VERSION ""

NS_ :

BS_:

BU_: XXX

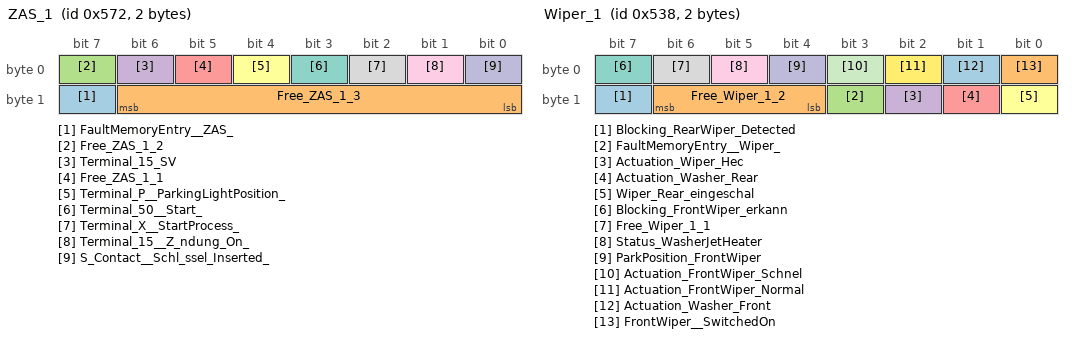
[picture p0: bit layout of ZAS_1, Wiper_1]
BO_ 1394 ZAS_1: 2 XXX
 SG_ FaultMemoryEntry__ZAS_ : 15|1@1+ (1,0) [0|0] "" XXX
 SG_ Free_ZAS_1_3 : 8|7@1+ (1,0) [0|0] "" XXX
 SG_ Free_ZAS_1_2 : 7|1@1+ (1,0) [0|0] "" XXX
 SG_ Terminal_15_SV : 6|1@1+ (1,0) [0|0] "" XXX
 SG_ Free_ZAS_1_1 : 5|1@1+ (1,0) [0|0] "" XXX
 SG_ Terminal_P__ParkingLightPosition_ : 4|1@1+ (1,0) [0|0] "" XXX
 SG_ Terminal_50__Start_ : 3|1@1+ (1,0) [0|0] "" XXX
 SG_ Terminal_X__StartProcess_ : 2|1@1+ (1,0) [0|0] "" XXX
 SG_ Terminal_15__Z_ndung_On_ : 1|1@1+ (1,0) [0|0] "" XXX
 SG_ S_Contact__Schl_ssel_Inserted_ : 0|1@1+ (1,0) [0|0] "" XXX

BO_ 1336 Wiper_1: 2 XXX
 SG_ Blocking_RearWiper_Detected : 15|1@1+ (1,0) [0|0] "" XXX
 SG_ Free_Wiper_1_2 : 12|3@1+ (1,0) [0|0] "" XXX
 SG_ FaultMemoryEntry__Wiper_ : 11|1@1+ (1,0) [0|0] "" XXX
 SG_ Actuation_Wiper_Hec : 10|1@1+ (1,0) [0|0] "" XXX
 SG_ Actuation_Washer_Rear : 9|1@1+ (1,0) [0|0] "" XXX
 SG_ Wiper_Rear_eingeschal : 8|1@1+ (1,0) [0|0] "" XXX
 SG_ Blocking_FrontWiper_erkann : 7|1@1+ (1,0) [0|0] "" XXX
 SG_ Free_Wiper_1_1 : 6|1@1+ (1,0) [0|0] "" XXX
 SG_ Status_WasherJetHeater : 5|1@1+ (1,0) [0|0] "" XXX
 SG_ ParkPosition_FrontWiper : 4|1@1+ (1,0) [0|0] "" XXX
 SG_ Actuation_FrontWiper_Schnel : 3|1@1+ (1,0) [0|0] "" XXX
 SG_ Actuation_FrontWiper_Normal : 2|1@1+ (1,0) [0|0] "" XXX
 SG_ Actuation_Washer_Front : 1|1@1+ (1,0) [0|0] "" XXX
 SG_ FrontWiper__SwitchedOn : 0|1@1+ (1,0) [0|0] "" XXX

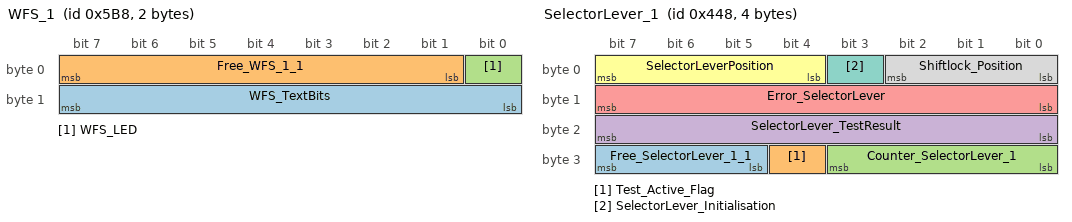
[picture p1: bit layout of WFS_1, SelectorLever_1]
BO_ 1464 WFS_1: 2 XXX
 SG_ WFS_TextBits : 8|8@1+ (1,0) [0|0] "" XXX
 SG_ Free_WFS_1_1 : 1|7@1+ (1,0) [0|0] "" XXX
 SG_ WFS_LED : 0|1@1+ (1,0) [0|0] "" XXX

BO_ 1096 SelectorLever_1: 4 XXX
 SG_ Free_SelectorLever_1_1 : 29|3@1+ (1,0) [0|0] "" XXX
 SG_ Test_Active_Flag : 28|1@1+ (1,0) [0|0] "" XXX
 SG_ Counter_SelectorLever_1 : 24|4@1+ (1,0) [0|15] "" XXX
 SG_ SelectorLever_TestResult : 16|8@1+ (1,0) [0|255] "" XXX
 SG_ Error_SelectorLever : 8|8@1+ (1,0) [0|0] "" XXX
 SG_ SelectorLeverPosition : 4|4@1+ (1,0) [0|0] "" XXX
 SG_ SelectorLever_Initialisation : 3|1@1+ (1,0) [0|0] "" XXX
 SG_ Shiftlock_Position : 0|3@1+ (1,0) [0|0] "" XXX

BO_ 1496 FitmentList_1: 8 XXX
 SG_ TV_Tuner : 63|1@1+ (1,0) [0|0] "" XXX
 SG_ DSP : 62|1@1+ (1,0) [0|0] "" XXX
 SG_ CD_Changer : 61|1@1+ (1,0) [0|0] "" XXX
 SG_ VoiceInput : 60|1@1+ (1,0) [0|0] "" XXX
 SG_ Telematics : 59|1@1+ (1,0) [0|0] "" XXX
 SG_ Navigation : 58|1@1+ (1,0) [0|0] "" XXX
 SG_ Phone : 57|1@1+ (1,0) [0|0] "" XXX
 SG_ Radio : 56|1@1+ (1,0) [0|0] "" XXX
 SG_ MMI_Front : 55|1@1+ (1,0) [0|0] "" XXX
 SG_ MMI_Rear : 54|1@1+ (1,0) [0|0] "" XXX
 SG_ Free_FitmentList_1_11 : 53|1@1+ (1,0) [0|0] "" XXX
 SG_ ClimatePanel_HL : 52|1@1+ (1,0) [0|0] "" XXX
 SG_ Free_FitmentList_1_10 : 50|2@1+ (1,0) [0|0] "" XXX
 SG_ FuelSender : 49|1@1+ (1,0) [0|0] "" XXX
 SG_ AssistDrivingLight : 48|1@1+ (1,0) [0|0] "" XXX
 SG_ Memory_hinter_Driver : 47|1@1+ (1,0) [0|0] "" XXX
 SG_ SeatMemory_Rear : 46|1@1+ (1,0) [0|0] "" XXX
 SG_ SeatMemory_Passenger : 45|1@1+ (1,0) [0|0] "" XXX
 SG_ Trailer_ngersteuergeraet : 44|1@1+ (1,0) [0|0] "" XXX
 SG_ EnergyManagement : 43|1@1+ (1,0) [0|0] "" XXX
 SG_ WiperModule : 42|1@1+ (1,0) [0|0] "" XXX
 SG_ EZS___Kessy__Comfort_ : 41|1@1+ (1,0) [0|0] "" XXX
 SG_ RoofControlUnit : 40|1@1+ (1,0) [0|0] "" XXX
 SG_ AuxHeater : 39|1@1+ (1,0) [0|0] "" XXX
 SG_ Free_FitmentList_1_9 : 38|1@1+ (1,0) [0|0] "" XXX
 SG_ ParkAssist : 37|1@1+ (1,0) [0|0] "" XXX
 SG_ ClimateControlUnit_Comfort : 36|1@1+ (1,0) [0|0] "" XXX
 SG_ Gateway : 35|1@1+ (1,0) [0|0] "" XXX
 SG_ SteeringColumnModule : 34|1@1+ (1,0) [0|0] "" XXX
 SG_ TyrePressure : 33|1@1+ (1,0) [0|0] "" XXX
 SG_ InstrumentCluster_Comfort : 32|1@1+ (1,0) [0|0] "" XXX
 SG_ RoofModule : 31|1@1+ (1,0) [0|0] "" XXX
 SG_ Memory : 30|1@1+ (1,0) [0|0] "" XXX
 SG_ DoorECU_HR : 29|1@1+ (1,0) [0|0] "" XXX
 SG_ DoorECU_HL : 28|1@1+ (1,0) [0|0] "" XXX
 SG_ DoorECU_BT : 27|1@1+ (1,0) [0|0] "" XXX
 SG_ DoorECU_FT : 26|1@1+ (1,0) [0|0] "" XXX
 SG_ ZKE : 25|1@1+ (1,0) [0|0] "" XXX
 SG_ BodyECU_Comfort : 24|1@1+ (1,0) [0|0] "" XXX
 SG_ Free_FitmentList_1_8 : 19|5@1+ (1,0) [0|0] "" XXX
 SG_ Stabiliser_Decoupling : 18|1@1+ (1,0) [0|0] "" XXX
 SG_ SelectorLever : 17|1@1+ (1,0) [0|0] "" XXX
 SG_ BatteryManager : 16|1@1+ (1,0) [0|0] "" XXX
 SG_ Damper_ECU : 15|1@1+ (1,0) [0|0] "" XXX
 SG_ LevelControl : 14|1@1+ (1,0) [0|0] "" XXX
 SG_ EZS___Kessy__Drive_ : 13|1@1+ (1,0) [0|0] "" XXX
 SG_ BrakeBooster : 12|1@1+ (1,0) [0|0] "" XXX
 SG_ PowerSteering : 11|1@1+ (1,0) [0|0] "" XXX
 SG_ Cluster_Drive : 10|1@1+ (1,0) [0|0] "" XXX
 SG_ InjectionPump : 9|1@1+ (1,0) [0|0] "" XXX
 SG_ SteeringAngle : 8|1@1+ (1,0) [0|0] "" XXX
 SG_ AllWheelDrive : 7|1@1+ (1,0) [0|0] "" XXX
 SG_ BodyECU_Drive : 6|1@1+ (1,0) [0|0] "" XXX
 SG_ ADDR : 5|1@1+ (1,0) [0|0] "" XXX
 SG_ Airbag : 4|1@1+ (1,0) [0|0] "" XXX
 SG_ Climatronic_Drive : 3|1@1+ (1,0) [0|0] "" XXX
 SG_ ABS : 2|1@1+ (1,0) [0|0] "" XXX
 SG_ GearboxControlUnit : 1|1@1+ (1,0) [0|0] "" XXX
 SG_ EngineControlUnit : 0|1@1+ (1,0) [0|0] "" XXX

BO_ 1488 SystemInfo_1: 6 XXX
 SG_ CAN_Level_4_1_Drive_Data_Hau : 44|4@1+ (1,0) [0|15] "" XXX
 SG_ CAN_Level_4_1_Drive_Data_Neb : 40|4@1+ (1,0) [0|15] "" XXX
 SG_ CAN_Level_4_1_Comfort_Data_Hau : 36|4@1+ (1,0) [0|15] "" XXX
 SG_ CAN_Level_4_1_Comfort_Data_Neb : 32|4@1+ (1,0) [0|15] "" XXX
 SG_ Free_SystemInfo_1_6 : 30|1@1+ (1,0) [0|0] "" XXX
 SG_ FourDoor : 29|1@1+ (1,0) [0|0] "" XXX
 SG_ RightHandDrive : 28|1@1+ (1,0) [0|0] "" XXX
 SG_ Vehicle_Index : 24|4@1+ (1,0) [0|0] "" XXX
 SG_ Vehicle_Generation : 20|4@1+ (1,0) [0|15] "" XXX
 SG_ Vehicle_Derivative : 16|4@1+ (1,0) [0|15] "" XXX
 SG_ Vehicle_Brand_2 : 12|4@1+ (1,0) [0|15] "" XXX
 SG_ Vehicle_Class : 8|4@1+ (1,0) [0|15] "" XXX
 SG_ FitmentInformation_Valid : 7|1@1+ (1,0) [0|0] "" XXX
 SG_ CAN_Infotainment_Fitted : 6|1@1+ (1,0) [0|0] "" XXX
 SG_ CAN_Infotainment_in_Diagnostics : 5|1@1+ (1,0) [0|0] "" XXX
 SG_ Sleep_CAN_Infotainment : 4|1@1+ (1,0) [0|0] "" XXX
 SG_ CAN_Comfort_in_Diagnostics : 3|1@1+ (1,0) [0|0] "" XXX
 SG_ Sleep_CAN_Comfort : 2|1@1+ (1,0) [0|0] "" XXX
 SG_ CAN_Drive_in_Diagnostics : 1|1@1+ (1,0) [0|0] "" XXX
 SG_ CAN_External_SwitchedIn : 0|1@1+ (1,0) [0|0] "" XXX

BO_ 268 Slave_1: 8 XXX
 SG_ Delta_Reduced_TargetTorque : 48|1@1+ (1,0) [0|0] "" XXX
 SG_ Delta_ThrottleValveAngle : 32|16@1+ (1,0) [0|0] "" XXX
 SG_ Free_Slave_1_1 : 25|7@1+ (1,0) [0|0] "" XXX
 SG_ Delta_IgnitionAngleOutput : 24|1@1+ (1,0) [0|0] "" XXX
 SG_ BattVoltage_Enable_DVE__Slave_ : 23|1@1+ (1,0) [0|0] "" XXX
 SG_ ThrottleValve_Sollwertbegrenzun : 22|1@1+ (1,0) [0|0] "" XXX
 SG_ InjectionInhibit_Learn__Slave_ : 21|1@1+ (1,0) [0|0] "" XXX
 SG_ Master_Detected__Slave_ : 20|1@1+ (1,0) [0|0] "" XXX
 SG_ Error_TorqueOutput : 19|1@1+ (1,0) [0|0] "" XXX
 SG_ Error_Gearbox_Torque : 18|1@1+ (1,0) [0|0] "" XXX
 SG_ Error_BrakesMessage : 17|1@1+ (1,0) [0|0] "" XXX
 SG_ Indicated_ActualTorque__Slave_ : 0|16@1+ (0.0015259,0) [0|99.998] "%" XXX
 SG_ Timeout_BrakesMessage : 0|1@1+ (1,0) [0|0] "" XXX

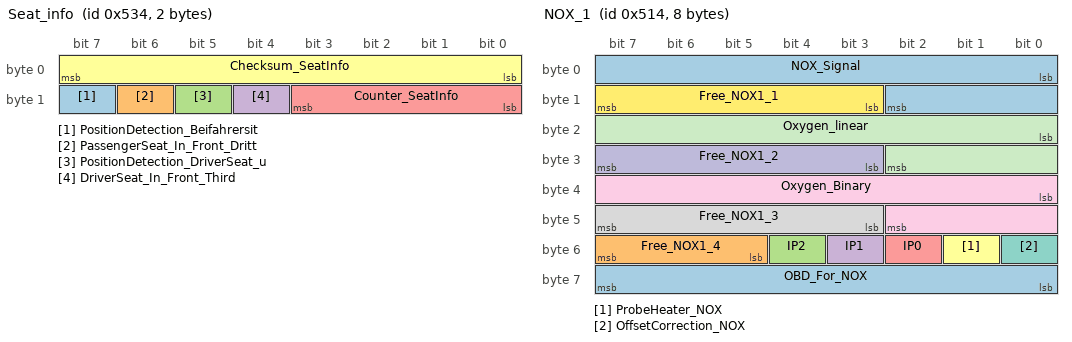
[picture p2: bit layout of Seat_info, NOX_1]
BO_ 1332 Seat_info: 2 XXX
 SG_ PositionDetection_Beifahrersit : 15|1@1+ (1,0) [0|0] "" XXX
 SG_ PassengerSeat_In_Front_Dritt : 14|1@1+ (1,0) [0|0] "" XXX
 SG_ PositionDetection_DriverSeat_u : 13|1@1+ (1,0) [0|0] "" XXX
 SG_ DriverSeat_In_Front_Third : 12|1@1+ (1,0) [0|0] "" XXX
 SG_ Counter_SeatInfo : 8|4@1+ (1,0) [0|15] "" XXX
 SG_ Checksum_SeatInfo : 0|8@1+ (1,0) [0|0] "" XXX

BO_ 1810 PSG_3: 2 XXX
 SG_ SelfTestResult : 0|16@1+ (1,0) [0|0] "" XXX

BO_ 1298 PSG_2: 8 XXX
 SG_ RAM_Contents_4 : 48|16@1+ (1,0) [0|0] "" XXX
 SG_ RAM_Contents_3 : 32|16@1+ (1,0) [0|0] "" XXX
 SG_ RAM_Contents_2 : 16|16@1+ (1,0) [0|0] "" XXX
 SG_ RAM_Contents_1 : 0|16@1+ (1,0) [0|0] "" XXX

BO_ 274 PSG_1: 8 XXX
 SG_ PumpTemperature__2_1_ : 48|16@1+ (0.0625,0) [0|4096] "K" XXX
 SG_ PumpTemperature__3_2_2_ : 44|12@1+ (1,0) [0|0] "" XXX
 SG_ CylinderCounter__3_2_2_ : 43|3@1+ (1,0) [1|8] "Zaehler" XXX
 SG_ ActuationTime__3_2_2_ : 32|11@1+ (0.0469,0) [0|96] "NW" XXX
 SG_ CamshaftSpeed__3_2_2_ : 20|12@1+ (4,0) [0|16380] "upm" XXX
 SG_ Pump_StatusWord__3_2_2_ : 0|20@1+ (1,0) [0|0] "" XXX

BO_ 1300 NOX_1: 8 XXX
 SG_ OBD_For_NOX : 56|8@1+ (1,0) [0|0] "" XXX
 SG_ Free_NOX1_4 : 53|3@1+ (1,0) [0|0] "" XXX
 SG_ IP2 : 52|1@1+ (1,0) [0|0] "" XXX
 SG_ IP1 : 51|1@1+ (1,0) [0|0] "" XXX
 SG_ IP0 : 50|1@1+ (1,0) [0|0] "" XXX
 SG_ ProbeHeater_NOX : 49|1@1+ (1,0) [0|0] "" XXX
 SG_ OffsetCorrection_NOX : 48|1@1+ (1,0) [0|0] "" XXX
 SG_ Free_NOX1_3 : 43|5@1+ (1,0) [0|0] "" XXX
 SG_ Oxygen_Binary : 32|11@1+ (1,-200) [-200|1847] "mV" XXX
 SG_ Free_NOX1_2 : 27|5@1+ (1,0) [0|0] "" XXX
 SG_ Oxygen_linear : 16|11@1+ (1,0) [0|2047] "1000/Lambd" XXX
 SG_ Free_NOX1_1 : 11|5@1+ (1,0) [0|0] "" XXX
 SG_ NOX_Signal : 0|11@1+ (1,0) [0|2047] "ppm" XXX

BO_ 1424 Level_1: 6 XXX
 SG_ LoadState : 40|8@1+ (1,0) [0|253] "Zuladung" XXX
 SG_ FaultMemoryEntry__Level_1 : 39|1@1+ (1,0) [0|0] "" XXX
 SG_ SystemStatus__Level_1_ : 38|1@1+ (1,0) [0|0] "" XXX
 SG_ Reserve_VehicleType : 37|1@1+ (1,0) [0|0] "" XXX
 SG_ VehicleType_Level : 36|1@1+ (1,0) [0|0] "" XXX
 SG_ TextBits__Level_1_ : 32|4@1+ (1,0) [0|0] "" XXX
 SG_ Adjustment_HL : 31|1@1+ (1,0) [0|0] "" XXX
 SG_ Adjustment_HR : 30|1@1+ (1,0) [0|0] "" XXX
 SG_ Adjustment_VL : 29|1@1+ (1,0) [0|0] "" XXX
 SG_ Adjustment_VR : 28|1@1+ (1,0) [0|0] "" XXX
 SG_ Lowering_Vehicle : 27|1@1+ (1,0) [0|0] "" XXX
 SG_ Raise_Vehicle : 26|1@1+ (1,0) [0|0] "" XXX
 SG_ Adjustment_Active : 25|1@1+ (1,0) [0|0] "" XXX
 SG_ CompressorRun_in_Kuerze : 24|1@1+ (1,0) [0|0] "" XXX
 SG_ Free_Level_1_5 : 23|1@1+ (1,0) [0|0] "" XXX
 SG_ PushButton_Level : 22|1@1+ (1,0) [0|0] "" XXX
 SG_ ParkLevel : 21|1@1+ (1,0) [0|0] "" XXX
 SG_ BetweenLevel : 20|1@1+ (1,0) [0|0] "" XXX
 SG_ LevelStatuses : 16|4@1+ (1,0) [0|0] "" XXX
 SG_ MSG_Restriction : 15|1@1+ (1,0) [0|0] "" XXX
 SG_ ESP_Influence : 14|1@1+ (1,0) [0|0] "" XXX
 SG_ WarningLamp_Level_1 : 13|1@1+ (1,0) [0|0] "" XXX
 SG_ Free_Level_1_1 : 12|1@1+ (1,0) [0|0] "" XXX
 SG_ Counter_Level_1 : 8|4@1+ (1,0) [0|15] "Zaehler" XXX
 SG_ Checksum_Level_1 : 0|8@1+ (1,0) [0|0] "" XXX

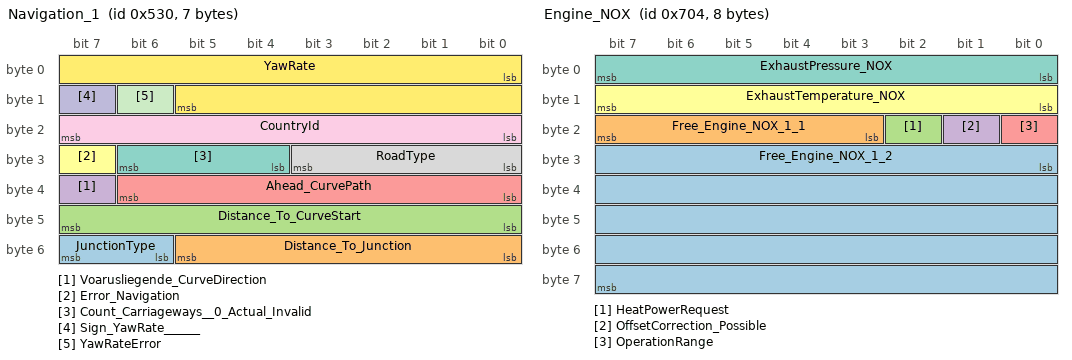
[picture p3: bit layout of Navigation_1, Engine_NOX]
BO_ 1328 Navigation_1: 7 XXX
 SG_ JunctionType : 54|2@1+ (1,0) [0|3] "" XXX
 SG_ Distance_To_Junction : 48|6@1+ (5,0) [0|315] "m" XXX
 SG_ Distance_To_CurveStart : 40|8@1+ (1,0) [0|255] "m" XXX
 SG_ Voarusliegende_CurveDirection : 39|1@1+ (1,0) [0|0] "" XXX
 SG_ Ahead_CurvePath : 32|7@1+ (50,0) [0|6350] "m" XXX
 SG_ Error_Navigation : 31|1@1+ (1,0) [0|0] "" XXX
 SG_ Count_Carriageways__0_Actual_Invalid : 28|3@1+ (1,0) [1|7] "" XXX
 SG_ RoadType : 24|4@1+ (1,0) [0|15] "" XXX
 SG_ CountryId : 16|8@1+ (1,0) [0|0] "" XXX
 SG_ Sign_YawRate______ : 15|1@1+ (1,0) [0|0] "" XXX
 SG_ YawRateError : 14|1@1+ (1,0) [0|0] "" XXX
 SG_ YawRate : 0|14@1+ (0.01,0) [0|100] "deg/sek" XXX

BO_ 1792 MSG_3: 3 XXX
 SG_ MSG_Configuration : 16|8@1+ (1,0) [0|0] "" XXX
 SG_ Position_Of_OT_Pulse : 0|16@1+ (0.01172,-384) [-384|384] "KW" XXX

BO_ 1280 MSG_2: 8 XXX
 SG_ RAM_Address_4 : 48|16@1+ (1,0) [0|0] "" XXX
 SG_ RAM_Address_3 : 32|16@1+ (1,0) [0|0] "" XXX
 SG_ RAM_Address_2 : 16|16@1+ (1,0) [0|0] "" XXX
 SG_ Ram_Address_1 : 0|16@1+ (1,0) [0|0] "" XXX

BO_ 256 MSG_1: 8 XXX
 SG_ CrankshaftSpeed__3_2_2_ : 56|8@1+ (1,0) [0|0] "" XXX
 SG_ Target_DeliveryStart_KW__3_2_2_ : 40|16@1+ (0.01172,-384) [-384|384] "KW" XXX
 SG_ Target_DeliveryStart_NW__3_2_2_ : 28|12@1+ (0.01172,0) [0|768] "degNW" XXX
 SG_ Target_BeforeInjection : 16|12@1+ (1,0) [0|0] "" XXX
 SG_ Target_InjectionQuantity : 0|16@1+ (0.03125,0) [0|2047] "mg/H" XXX

BO_ 1796 Engine_NOX: 8 XXX
 SG_ Free_Engine_NOX_1_2 : 24|40@1+ (1,0) [0|0] "" XXX
 SG_ Free_Engine_NOX_1_1 : 19|5@1+ (1,0) [0|0] "" XXX
 SG_ HeatPowerRequest : 18|1@1+ (1,0) [0|0] "" XXX
 SG_ OffsetCorrection_Possible : 17|1@1+ (1,0) [0|0] "" XXX
 SG_ OperationRange : 16|1@1+ (1,0) [0|0] "" XXX
 SG_ ExhaustTemperature_NOX : 8|8@1+ (5,-40) [-40|1230] "C" XXX
 SG_ ExhaustPressure_NOX : 0|8@1+ (5,600) [600|1870] "mbar" XXX

BO_ 900 Engine_Torques: 8 XXX
 SG_ TorqueData_Inaccurate__Torque : 35|2@1+ (1,0) [0|0] "" XXX

BO_ 1408 Engine_Flexia: 8 XXX
 SG_ IntakeSystem m0 : 63|1@1+ (1,0) [0|0] "" XXX
 SG_ Displacement m0 : 56|7@1+ (0.1,0) [0|12.7] "l" XXX
 SG_ Gradient_The_FillCurve m1 : 56|8@1+ (0.001,0) [0|0.255] "l/mm" XXX
 SG_ Count_Cylinder m0 : 52|4@1+ (1,0) [0|15] "Vent./Zyl." XXX
 SG_ WeightingFactor_SootIndex_Turbo m1 : 50|6@1+ (0.1,0) [0|6.3] "" XXX
 SG_ Count_Valves m0 : 49|3@1+ (1,0) [0|7] "Vent./Zyl." XXX
 SG_ WeightingFactor_WearIndex m1 : 44|6@1+ (0.1,0) [0|6.3] "" XXX
 SG_ Manufacturer_Code m1 : 40|4@1+ (1,0) [0|15] "" XXX
 SG_ EnginePower m0 : 40|9@1+ (1,0) [0|512] "KW" XXX
 SG_ Max_Torque m0 : 32|8@1+ (10,0) [0|2550] "Nm" XXX
 SG_ Normalised_Consumption m1 : 32|8@1+ (10,0) [0|2550] "l/Zyl." XXX
 SG_ OilLevelThreshold m1 : 24|8@1+ (0.25,0) [0|63.75] "cm" XXX
 SG_ Rpm_MaxNorm m0 : 24|8@1+ (100,0) [0|25500] "U/min" XXX
 SG_ WearIndex : 16|8@1+ (1,0) [0|254] "" XXX
 SG_ SootIndex : 8|8@1+ (1,0) [0|254] "" XXX
 SG_ CombustionType : 7|1@1+ (1,0) [0|0] "" XXX
 SG_ Free_Engine_Flexia_1 : 6|1@1+ (1,0) [0|0] "" XXX
 SG_ Warm_Up_Cycle : 5|1@1+ (1,0) [0|0] "" XXX
 SG_ Driving_Cycle : 4|1@1+ (1,0) [0|0] "" XXX
 SG_ Counter_Engine_Flexia : 1|3@1+ (1,0) [0|15] "" XXX
 SG_ Multiplex_Switch_Engine_Flexia M : 0|1@1+ (1,0) [0|0] "" XXX

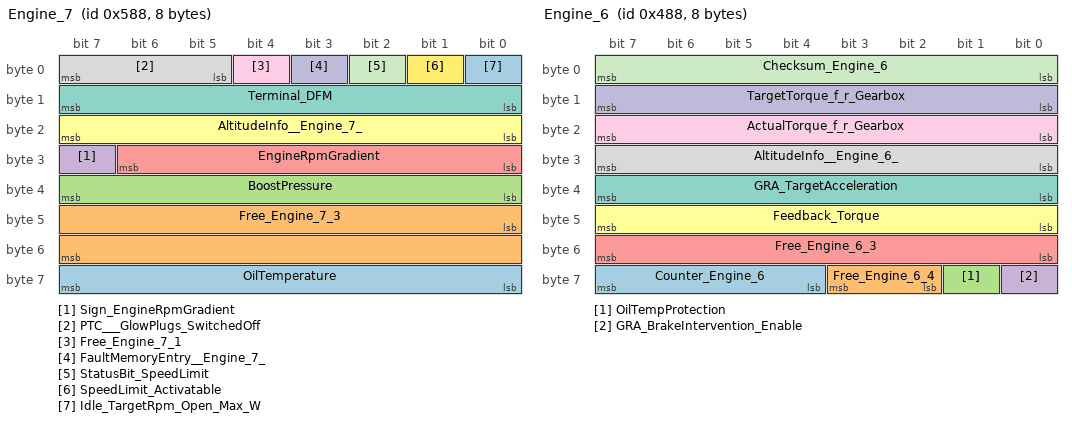
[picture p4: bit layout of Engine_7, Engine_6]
BO_ 1416 Engine_7: 8 XXX
 SG_ OilTemperature : 56|8@1+ (1,0) [0|0] "" XXX
 SG_ Free_Engine_7_3 : 40|16@1+ (1,0) [0|0] "" XXX
 SG_ BoostPressure : 32|8@1+ (0.01,0) [0|2.54] "bar" XXX
 SG_ Sign_EngineRpmGradient : 31|1@1+ (1,0) [0|0] "" XXX
 SG_ EngineRpmGradient : 24|7@1+ (1,0) [0|126] "U/min" XXX
 SG_ AltitudeInfo__Engine_7_ : 16|8@1+ (0.00787,0) [0|2] "" XXX
 SG_ Terminal_DFM : 8|8@1+ (0.4,0) [0|101.6] "%" XXX
 SG_ PTC___GlowPlugs_SwitchedOff : 5|3@1+ (1,0) [0|0] "" XXX
 SG_ Free_Engine_7_1 : 4|1@1+ (1,0) [0|0] "" XXX
 SG_ FaultMemoryEntry__Engine_7_ : 3|1@1+ (1,0) [0|0] "" XXX
 SG_ StatusBit_SpeedLimit : 2|1@1+ (1,0) [0|0] "" XXX
 SG_ SpeedLimit_Activatable : 1|1@1+ (1,0) [0|0] "" XXX
 SG_ Idle_TargetRpm_Open_Max_W : 0|1@1+ (1,0) [0|0] "" XXX

BO_ 1160 Engine_6: 8 XXX
 SG_ Counter_Engine_6 : 60|4@1+ (1,0) [0|15] "" XXX
 SG_ Free_Engine_6_4 : 58|2@1+ (1,0) [0|0] "" XXX
 SG_ OilTempProtection : 57|1@1+ (1,0) [0|0] "" XXX
 SG_ GRA_BrakeIntervention_Enable : 56|1@1+ (1,0) [0|0] "" XXX
 SG_ Free_Engine_6_3 : 48|8@1+ (1,0) [0|0] "" XXX
 SG_ Feedback_Torque : 40|8@1+ (0.39,0) [0|100] "" XXX
 SG_ GRA_TargetAcceleration : 32|8@1+ (0.024,-3.984) [-3.984|2.112] "m/s2" XXX
 SG_ AltitudeInfo__Engine_6_ : 24|8@1+ (0.00787,0) [0|2] "" XXX
 SG_ ActualTorque_f_r_Gearbox : 16|8@1+ (0.39,0) [0|99] "MDI" XXX
 SG_ TargetTorque_f_r_Gearbox : 8|8@1+ (0.39,0) [0|99] "MDI" XXX
 SG_ Checksum_Engine_6 : 0|8@1+ (1,0) [0|0] "" XXX

BO_ 1152 Engine_5: 8 Motor
 SG_ MO5_Mp_Code M : 6|2@1+ (1,0) [0|3] "" Gateway
 SG_ MO5_max_Torque m0 : 0|6@1+ (10,0) [0|630] "Nm" Gateway
 SG_ MO5_Rpm m1 : 0|6@1+ (100,0) [0|6300] "U/min" Gateway
 SG_ MO5_EngineType m2 : 0|6@1+ (1,0) [0|63] "" Gateway
 SG_ MO5_ExhaustType m3 : 0|1@1+ (1,0) [0|1] "" Gateway
 SG_ MO5_ExhaustType2 m3 : 1|1@1+ (1,0) [0|1] "" Gateway
 SG_ MO5_ExhaustType3 m3 : 2|1@1+ (1,0) [0|1] "" Gateway
 SG_ OBD_ColdStart_Denominator m3 : 3|1@1+ (1,0) [0|1] "" Gateway
 SG_ OBD_Minimum_Trip m3 : 4|1@1+ (1,0) [0|1] "" Gateway
 SG_ MO5_DPF_reg m3 : 5|1@1+ (1,0) [0|1] "" Gateway
 SG_ MO5_Preheat : 9|1@1+ (1,0) [0|1] "" KOMBI
 SG_ MO5_E_Gas : 10|1@1+ (1,0) [0|1] "" KOMBI
 SG_ MO5_OBD_2 : 11|1@1+ (1,0) [0|1] "" KOMBI
 SG_ MO5_HotWarning : 12|1@1+ (1,0) [0|1] "" KOMBI
 SG_ MO5_AcCompressor : 13|1@1+ (1,0) [0|1] "" Gateway
 SG_ MO5_Field_Cool : 14|1@1+ (1,0) [0|1] "" Gateway
 SG_ MO5_KliKo_Red : 15|1@1+ (1,0) [0|1] "" Gateway
 SG_ MO5_Consumption : 16|15@1+ (1,0) [0|32767] "µl" KOMBI
 SG_ MO5_UeberlVerb : 31|1@1+ (1,0) [0|1] "" KOMBI
 SG_ MO5_Fan : 32|8@1+ (0.4,0) [0|101.6] "%" Gateway
 SG_ MO5_HLamp : 40|1@1+ (1,0) [0|1] "" KOMBI
 SG_ MO5_ParticleLamp : 41|1@1+ (1,0) [0|1] "" KOMBI
 SG_ MO5_Status_BKU : 42|1@1+ (1,0) [0|1] "" Gateway
 SG_ MO5_TypeStartSteu : 43|1@1+ (1,0) [0|1] "" Gateway
 SG_ MO5_TDE_Lamp : 44|1@1+ (1,0) [0|1] "" KOMBI
 SG_ MO5_TDE_Text : 45|1@1+ (1,0) [0|1] "" KOMBI
 SG_ MO5_DZM_Damping : 46|1@1+ (1,0) [0|1] "" KOMBI
 SG_ MO5_Interlock : 47|1@1+ (1,0) [0|1] "" Gateway
 SG_ MO5_Start : 48|1@1+ (1,0) [0|1] "" Gateway
 SG_ MO5_Starter : 49|1@1+ (1,0) [0|1] "" Gateway
 SG_ MO5_GRA_Hauptsch : 50|1@1+ (1,0) [0|1] "" Gateway
 SG_ MO5_Torques : 51|1@1+ (1,0) [0|1] "" Gateway
 SG_ MO5_EngineText1 : 52|1@1+ (1,0) [0|1] "" KOMBI
 SG_ MO5_EngineText2 : 53|1@1+ (1,0) [0|1] "" KOMBI
 SG_ MO5_EngineText3 : 54|1@1+ (1,0) [0|1] "" KOMBI
 SG_ MO5_EngineText4 : 55|1@1+ (1,0) [0|1] "" KOMBI
 SG_ CHECKSUM : 56|8@1+ (1,0) [0|255] "" Gateway

BO_ 896 Engine_3: 8 Motor
 SG_ MO3_Preheat : 0|1@1+ (1,0) [0|1] "" Gateway
 SG_ MO3_Prio_Rpm : 1|1@1+ (1,0) [0|1] "" Transmission
 SG_ MO_Switch_StartStop : 2|1@1+ (1,0) [0|1] "" Gateway
 SG_ MO3_WinterProgram : 3|1@1+ (1,0) [0|1] "" Transmission
 SG_ MO3_Status_Pedal : 4|1@1+ (1,0) [0|1] "" Gateway
 SG_ MO3_Status_FPG M : 5|1@1+ (1,0) [0|1] "" ESP
 SG_ MO3_Sign_FPG m1 : 6|1@1+ (1,0) [0|1] "" ESP
 SG_ MO3_Status_Temp : 7|1@1+ (1,0) [0|1] "" Gateway
 SG_ MO3_Offsentemp : 8|8@1+ (0.75,-48) [-48|142.5] "°C" Gateway
 SG_ MO3_PedalValue : 16|8@1+ (0.4,0) [0|101.6] "%" Gateway
 SG_ MO3_Wheel_Wu_Mo : 24|12@1+ (0.39,0) [0|1596.66] "%" Transmission
 SG_ MO3_Sign_WheelWu : 36|1@1+ (1,0) [0|1] "" Transmission
 SG_ MO3_Enable_Coasting : 37|1@1+ (1,0) [0|1] "" Transmission
 SG_ MO_StartStop_StopPreparation : 38|1@1+ (1,0) [0|1] "" Gateway
 SG_ MO3_Rpm_Influence : 40|8@1+ (0.39,0) [0|99.45] "%" Transmission
 SG_ MO3_RequestRpm : 48|8@1+ (25,0) [0|6350] "U/min" Transmission
 SG_ MO3_DKW m0 : 56|8@1+ (0.4,0) [0|101.6] "%" Gateway
 SG_ MO3_FPGradient m1 : 56|8@1+ (25,0) [0|6350] "%/s" ESP

BO_ 648 Engine_2: 8 Motor
 SG_ MO2_Mp_Code m : 6|2@1+ (1,0) [0|3] "" Gateway
 SG_ MO2_Gearbox_Code m2 : 0|6@1+ (1,0) [0|63] "" Gateway
 SG_ MO2_max_Mo m3 : 0|6@1+ (10,0) [0|630] "Nm" Gateway
 SG_ MO2_CAN_Vers m0 : 0|6@1+ (1,0) [0|63] "" Gateway
 SG_ MO2_Engine_Code m1 : 0|6@1+ (1,0) [0|63] "" Gateway
 SG_ MO2_Coolant_T : 8|8@1+ (0.75,-48) [-47.25|142.5] "°C" Gateway
 SG_ MO2_BLS : 16|1@1+ (1,0) [0|1] "" Gateway
 SG_ MO2_BTS : 17|1@1+ (1,0) [0|1] "" Gateway
 SG_ MO2_Status_Coolant : 18|1@1+ (1,0) [0|1] "" Gateway
 SG_ MO2_Status_Climate : 19|1@1+ (1,0) [0|1] "" Gateway
 SG_ MO2_Status_No_Bet : 20|1@1+ (1,0) [0|1] "" Gateway
 SG_ MO2_Status_TSK : 21|1@1+ (1,0) [0|1] "" Gateway
 SG_ MO2_Status_GRA : 22|2@1+ (1,0) [0|3] "" ACC,GRA
 SG_ TSK_Limiter_Selected : 25|1@1+ (1,0) [0|1] "" ACC,GRA
 SG_ MO2_GRAregelt : 26|1@1+ (1,0) [0|1] "" Gateway
 SG_ MO2_Sport_Error : 27|1@1+ (1,0) [0|1] "" Gateway
 SG_ MO2_OffRoad : 28|1@1+ (1,0) [0|1] "" Gateway
 SG_ MO2_RME_Gehalt : 29|3@1+ (12.5,0) [0|75] "%" Gateway
 SG_ MO2_GRA_Target : 32|8@1+ (1.28,0) [0|325.12] "km/h" ACC,GRA
 SG_ MO2_LL_TargetRpm : 40|8@1+ (10,0) [0|2540] "1/min" Gateway
 SG_ MO2_Limit_Mo : 48|8@1+ (0.39,0) [0|99.06] "%" Gateway
 SG_ MO2_Mo_ZWR : 56|8@1+ (0.39,0) [0|99.06] "%" Gateway

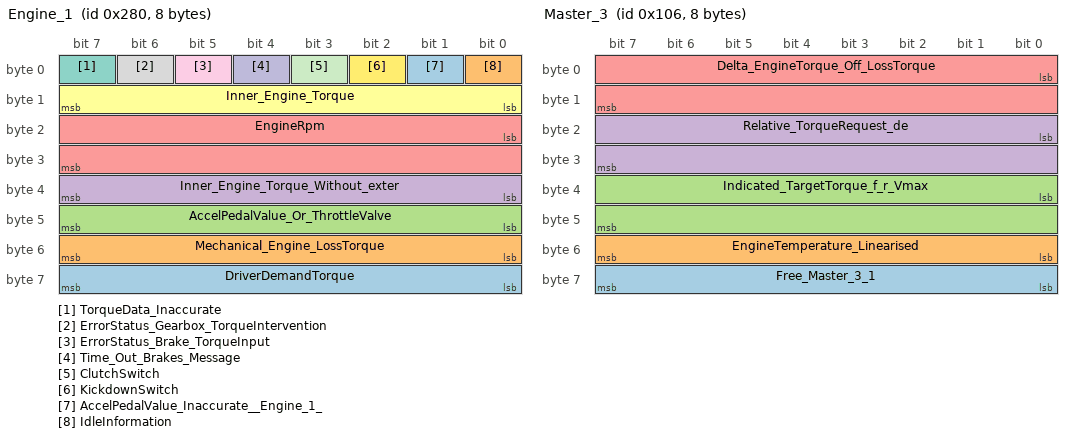
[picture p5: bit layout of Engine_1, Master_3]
BO_ 640 Engine_1: 8 XXX
 SG_ DriverDemandTorque : 56|8@1+ (0.39,0) [0|99] "MDI" XXX
 SG_ Mechanical_Engine_LossTorque : 48|8@1+ (0.39,0) [0|99] "MDI" XXX
 SG_ AccelPedalValue_Or_ThrottleValve : 40|8@1+ (0.4,0) [0|101.6] "%" XXX
 SG_ Inner_Engine_Torque_Without_exter : 32|8@1+ (0.39,0) [0|99] "MDI" XXX
 SG_ EngineRpm : 16|16@1+ (0.25,0) [0|16256] "U/min" XXX
 SG_ Inner_Engine_Torque : 8|8@1+ (0.39,0) [0|99] "MDI" XXX
 SG_ TorqueData_Inaccurate : 7|1@1+ (1,0) [0|0] "" XXX
 SG_ ErrorStatus_Gearbox_TorqueIntervention : 6|1@1+ (1,0) [0|0] "" XXX
 SG_ ErrorStatus_Brake_TorqueInput : 5|1@1+ (1,0) [0|0] "" XXX
 SG_ Time_Out_Brakes_Message : 4|1@1+ (1,0) [0|0] "" XXX
 SG_ ClutchSwitch : 3|1@1+ (1,0) [0|0] "" XXX
 SG_ KickdownSwitch : 2|1@1+ (1,0) [0|0] "" XXX
 SG_ AccelPedalValue_Inaccurate__Engine_1_ M : 1|1@1+ (1,0) [0|0] "" XXX
 SG_ IdleInformation : 0|1@1+ (1,0) [0|0] "" XXX

BO_ 262 Master_3: 8 XXX
 SG_ Free_Master_3_1 : 56|8@1+ (1,0) [0|0] "" XXX
 SG_ EngineTemperature_Linearised : 48|8@1+ (0.75,-48) [-48|143.25] "" XXX
 SG_ Indicated_TargetTorque_f_r_Vmax : 32|16@1+ (0.0015259,0) [0|100] "%" XXX
 SG_ Relative_TorqueRequest_de : 16|16@1+ (0.003052,0) [0|200] "%" XXX
 SG_ Delta_EngineTorque_Off_LossTorque : 0|16@1+ (0.003052,-100) [-100|100] "%" XXX

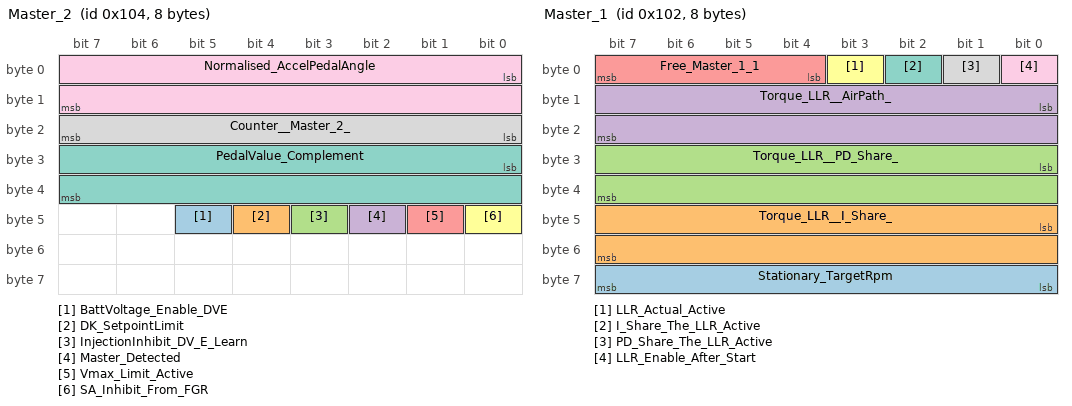
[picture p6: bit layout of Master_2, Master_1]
BO_ 260 Master_2: 8 XXX
 SG_ BattVoltage_Enable_DVE : 45|1@1+ (1,0) [0|0] "" XXX
 SG_ DK_SetpointLimit : 44|1@1+ (1,0) [0|0] "" XXX
 SG_ InjectionInhibit_DV_E_Learn : 43|1@1+ (1,0) [0|0] "" XXX
 SG_ Master_Detected : 42|1@1+ (1,0) [0|0] "" XXX
 SG_ Vmax_Limit_Active : 41|1@1+ (1,0) [0|0] "" XXX
 SG_ SA_Inhibit_From_FGR : 40|1@1+ (1,0) [0|0] "" XXX
 SG_ PedalValue_Complement : 24|16@1+ (1,0) [0|0] "" XXX
 SG_ Counter__Master_2_ : 16|8@1+ (1,0) [0|255] "" XXX
 SG_ Normalised_AccelPedalAngle : 0|16@1+ (0.001526,0) [0|100] "%" XXX

BO_ 258 Master_1: 8 XXX
 SG_ Stationary_TargetRpm : 56|8@1+ (10,0) [0|2550] "Umin" XXX
 SG_ Torque_LLR__I_Share_ : 40|16@1+ (0.003052,-100) [-100|100] "%" XXX
 SG_ Torque_LLR__PD_Share_ : 24|16@1+ (0.003052,-100) [-100|100] "%" XXX
 SG_ Torque_LLR__AirPath_ : 8|16@1+ (0.003052,-100) [-100|100] "%" XXX
 SG_ Free_Master_1_1 : 4|4@1+ (1,0) [0|0] "" XXX
 SG_ LLR_Actual_Active : 3|1@1+ (1,0) [0|0] "" XXX
 SG_ I_Share_The_LLR_Active : 2|1@1+ (1,0) [0|0] "" XXX
 SG_ PD_Share_The_LLR_Active : 1|1@1+ (1,0) [0|0] "" XXX
 SG_ LLR_Enable_After_Start : 0|1@1+ (1,0) [0|0] "" XXX

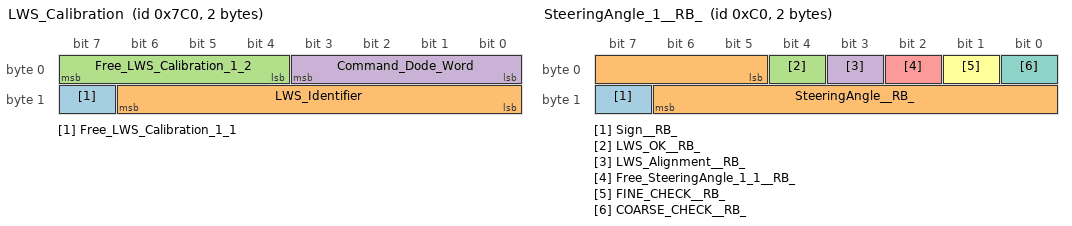
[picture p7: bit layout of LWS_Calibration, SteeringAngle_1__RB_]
BO_ 1984 LWS_Calibration: 2 XXX
 SG_ Free_LWS_Calibration_1_1 : 15|1@1+ (1,0) [0|0] "" XXX
 SG_ LWS_Identifier : 8|7@1+ (1,0) [0|0] "" XXX
 SG_ Free_LWS_Calibration_1_2 : 4|4@1+ (1,0) [0|0] "" XXX
 SG_ Command_Dode_Word : 0|4@1+ (1,0) [0|0] "" XXX

BO_ 1986 SteeringAngle_Init: 4 XXX
 SG_ CodingBytes : 8|24@1+ (1,0) [0|0] "" XXX
 SG_ Identiifier_f_r_LWS_Init : 0|8@1+ (1,0) [0|0] "" XXX

BO_ 192 SteeringAngle_1__RB_: 2 XXX
 SG_ Sign__RB_ : 15|1@1+ (1,0) [0|0] "" XXX
 SG_ SteeringAngle__RB_ : 5|10@1+ (2.5,-720) [-720|720] "" XXX
 SG_ LWS_OK__RB_ : 4|1@1+ (1,0) [0|0] "" XXX
 SG_ LWS_Alignment__RB_ : 3|1@1+ (1,0) [0|0] "" XXX
 SG_ Free_SteeringAngle_1_1__RB_ : 2|1@1+ (1,0) [0|0] "" XXX
 SG_ FINE_CHECK__RB_ : 1|1@1+ (1,0) [0|0] "" XXX
 SG_ COARSE_CHECK__RB_ : 0|1@1+ (1,0) [0|0] "" XXX

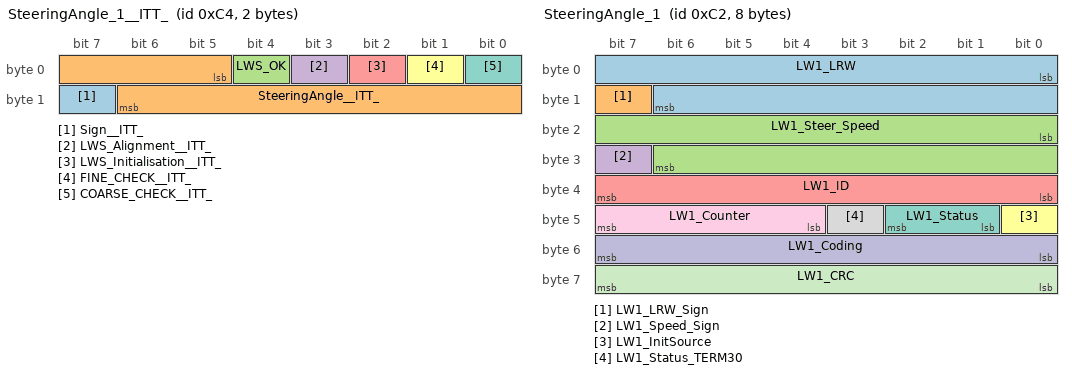
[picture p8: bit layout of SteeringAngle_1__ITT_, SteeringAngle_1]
BO_ 196 SteeringAngle_1__ITT_: 2 XXX
 SG_ Sign__ITT_ : 15|1@1+ (1,0) [0|0] "" XXX
 SG_ SteeringAngle__ITT_ : 5|10@1+ (1.5,-768) [-768|766.5] "" XXX
 SG_ LWS_OK : 4|1@1+ (1,0) [0|0] "" XXX
 SG_ LWS_Alignment__ITT_ : 3|1@1+ (1,0) [0|0] "" XXX
 SG_ LWS_Initialisation__ITT_ : 2|1@1+ (1,0) [0|0] "" XXX
 SG_ FINE_CHECK__ITT_ : 1|1@1+ (1,0) [0|0] "" XXX
 SG_ COARSE_CHECK__ITT_ : 0|1@1+ (1,0) [0|0] "" XXX

BO_ 194 SteeringAngle_1: 8 XXX
 SG_ LW1_LRW : 0|15@1+ (0.04375,0) [0|1433.55625] "°Grad" Gateway,ESP,ABS
 SG_ LW1_LRW_Sign : 15|1@1+ (1,0) [0|1] "" Gateway,ESP,ABS
 SG_ LW1_Steer_Speed : 16|15@1+ (0.04375,0) [0|1433.55625] "°Grad/s" Gateway,ESP,ABS
 SG_ LW1_Speed_Sign : 31|1@1+ (1,0) [0|1] "" Gateway,ESP,ABS
 SG_ LW1_ID : 32|8@1+ (1,0) [0|255] "" Gateway,ESP,ABS
 SG_ LW1_InitSource : 40|1@1+ (1,0) [0|1] "" Gateway,ESP,ABS
 SG_ LW1_Status : 41|2@1+ (1,0) [0|3] "" Gateway,ESP,ABS
 SG_ LW1_Status_TERM30 : 43|1@1+ (1,0) [0|1] "" Gateway,ESP,ABS
 SG_ LW1_Counter : 44|4@1+ (1,0) [0|15] "" Gateway,ESP,ABS
 SG_ LW1_Coding : 48|8@1+ (1,0) [0|255] "" Gateway
 SG_ LW1_CRC : 56|8@1+ (1,0) [0|255] "" Gateway,ESP,ABS

BO_ 1502 PowerSteering_Error: 7 XXX
 SG_ WorkshopCode : 48|8@1+ (1,0) [0|0] "" XXX
 SG_ Multiplex_Signal : 45|3@1+ (1,0) [0|7] "" XXX
 SG_ SensorCoding_PowerSteering : 44|1@1+ (1,0) [0|0] "" XXX
 SG_ CurveCoding_PowerSteering : 40|4@1+ (1,0) [0|15] "Kennlinie" XXX
 SG_ Sender_f__Lenkw__Memory_ausles : 39|1@1+ (1,0) [0|0] "" XXX
 SG_ InstrumentCluster__Memory_ReadOut : 38|1@1+ (1,0) [0|0] "" XXX
 SG_ ControlUnit__Memory_ReadOut : 37|1@1+ (1,0) [0|0] "" XXX
 SG_ PowerSteering_ControlUnit_Defective : 36|1@1+ (1,0) [0|0] "" XXX
 SG_ Free_PowerSteering_1_3 : 32|4@1+ (1,0) [0|0] "" XXX
 SG_ Free_PowerSteering_1_4 : 30|2@1+ (1,0) [0|0] "" XXX
 SG_ Sender_f__Lenkwi__k__CAN_Comm_sp : 29|1@1+ (1,0) [0|0] "" XXX
 SG_ Sender_f__SteeringAngle_k__CAN_Comm : 28|1@1+ (1,0) [0|0] "" XXX
 SG_ InstrumentCluster__k__CAN_Comm__sp : 27|1@1+ (1,0) [0|0] "" XXX
 SG_ InstrumentCluster_k__CAN_Comm : 26|1@1+ (1,0) [0|0] "" XXX
 SG_ ControlUnit_k__CAN_Comm__S : 25|1@1+ (1,0) [0|0] "" XXX
 SG_ ControlUnit_No_CAN_Comm : 24|1@1+ (1,0) [0|0] "" XXX
 SG_ PowerSteering_Voltage_Ks__After_Mas : 23|1@1+ (1,0) [0|0] "" XXX
 SG_ PowerSteering_Voltage_Ks_After_Mass : 22|1@1+ (1,0) [0|0] "" XXX
 SG_ PowerSteering_Voltage_Ks__After___s : 21|1@1+ (1,0) [0|0] "" XXX
 SG_ PowerSteering_Voltage_Ks__After__ : 20|1@1+ (1,0) [0|0] "" XXX
 SG_ PowerSteering_TemperatureProtection_sp_ : 19|1@1+ (1,0) [0|0] "" XXX
 SG_ PowerSteering_TemperatureProtection : 18|1@1+ (1,0) [0|0] "" XXX
 SG_ PowerSteering_Operation_Implaus__Sig__sp : 17|1@1+ (1,0) [0|0] "" XXX
 SG_ PowerSteering_Operation_Implaus__Signal : 16|1@1+ (1,0) [0|0] "" XXX
 SG_ PowerSteeringSensor_k__Comm__sp : 15|1@1+ (1,0) [0|0] "" XXX
 SG_ PowerSteeringSensor_No_Comm_ : 14|1@1+ (1,0) [0|0] "" XXX
 SG_ PowerSteeringSensor_Defective_sp_ : 13|1@1+ (1,0) [0|0] "" XXX
 SG_ PowerSteeringSensor_Defective : 12|1@1+ (1,0) [0|0] "" XXX
 SG_ PowerSteeringSensor_OpenCircuit_s : 11|1@1+ (1,0) [0|0] "" XXX
 SG_ PowerSteeringSensor_OpenCircuit : 10|1@1+ (1,0) [0|0] "" XXX
 SG_ PowerSteeringSensor_Ks_After_Mass_s : 9|1@1+ (1,0) [0|0] "" XXX
 SG_ PowerSteeringSensor_Ks_After_Mass : 8|1@1+ (1,0) [0|0] "" XXX
 SG_ Voltage_Term_15_Closed_Small_sp_ : 7|1@1+ (1,0) [0|0] "" XXX
 SG_ Voltage_Term_15_Closed_Small : 6|1@1+ (1,0) [0|0] "" XXX
 SG_ Free_PowerSteering_1_5 : 4|2@1+ (1,0) [0|0] "" XXX
 SG_ Voltage_Term_30_Closed_Small_sp_ : 3|1@1+ (1,0) [0|0] "" XXX
 SG_ Voltage_Term_30_Closed_Small : 2|1@1+ (1,0) [0|0] "" XXX
 SG_ Voltage_Term_30_Closed_gro__sp_ : 1|1@1+ (1,0) [0|0] "" XXX
 SG_ Voltage_Term_30_Closed_gro_ : 0|1@1+ (1,0) [0|0] "" XXX

BO_ 976 PowerSteering_1: 2 XXX
 SG_ LH1_LoadInfo : 0|7@1+ (1,0) [0|127] "A" XXX
 SG_ LH1_Error_LEFT : 7|1@1+ (1,0) [0|1] "" XXX
 SG_ LH1_SafetyLamp : 8|1@1+ (1,0) [0|1] "" XXX
 SG_ LH1_FaultLamp : 9|1@1+ (1,0) [0|1] "" XXX
 SG_ LH1_TextBits : 10|3@1+ (1,0) [0|7] "" XXX
 SG_ LH1_AcousticSign : 13|1@1+ (1,0) [0|1] "" XXX
 SG_ LH1_SleepInd : 14|1@1+ (1,0) [0|1] "" XXX
 SG_ LH1_FaultEntry : 15|1@1+ (1,0) [0|1] "" XXX
 SG_ LH1_EPS_DiagMode : 16|1@1+ (1,0) [0|1] "" XXX
 SG_ LH1_Valid_ECU_Temp : 19|1@1+ (1,0) [0|1] "" XXX
 SG_ LH1_Cooling : 20|1@1+ (1,0) [0|1] "" XXX
 SG_ LH1_Mode_Hybrid : 21|1@1+ (1,0) [0|1] "" XXX
 SG_ LH1_NL_Undervolt : 24|1@1+ (1,0) [0|1] "" XXX
 SG_ LH1_NL_Overvolt : 25|1@1+ (1,0) [0|1] "" XXX
 SG_ LH1_NL_Overtemp : 26|1@1+ (1,0) [0|1] "" XXX
 SG_ LH1_NL_Sensor : 27|1@1+ (1,0) [0|1] "" XXX
 SG_ LH1_NL_CAN_SS : 28|1@1+ (1,0) [0|1] "" XXX
 SG_ LH1_NL_ECU : 29|1@1+ (1,0) [0|1] "" XXX
 SG_ LH1_NL_Engine : 30|1@1+ (1,0) [0|1] "" XXX
 SG_ LH1_NL_PowerDensity : 31|1@1+ (1,0) [0|1] "" XXX
 SG_ LH1_UPower : 32|8@1+ (0.5,0) [0|100] "%" XXX
 SG_ LH1_ECU_Temp : 40|8@1+ (1,-70) [-70|185] "°C" XXX

BO_ 1312 Cluster_3: 8 XXX
 SG_ Free_Cluster_3_2 : 60|4@1+ (1,0) [0|0] "" XXX
 SG_ Odometer : 40|20@1+ (1,0) [0|1000000] "km" XXX
 SG_ ErrorStatus_ParkedTime : 39|1@1+ (1,0) [0|0] "" XXX
 SG_ ParkedTime : 24|15@1+ (4,0) [0|131068] "sec" XXX
 SG_ Free_Cluster_3_1 : 20|4@1+ (1,0) [0|0] "" XXX
 SG_ KeyInfo : 16|4@1+ (1,0) [0|15] "" XXX
 SG_ Cluster_Multiplex_Code M : 14|2@1+ (1,0) [0|0] "" XXX
 SG_ Cluster_FitmentList_Niveauregulie m3 : 11|1@1+ (1,0) [0|0] "" XXX
 SG_ Cluster_Multiplex_Brand m1 : 11|3@1+ (1,0) [0|0] "" XXX
 SG_ Cluster_FitmentList_PowerSteering m3 : 10|1@1+ (1,0) [0|0] "" XXX
 SG_ Cluster_FitmentList_DieselPump m3 : 9|1@1+ (1,0) [0|0] "" XXX
 SG_ Cluster_FitmentList_SteeringAngle m3 : 8|1@1+ (1,0) [0|0] "" XXX
 SG_ Cluster_Multiplex_Series m1 : 8|3@1+ (1,0) [0|0] "" XXX
 SG_ Cluster_Multiplex_CountryVariant m0 : 8|6@1+ (1,0) [0|0] "" XXX
 SG_ Cluster_FitmentList_AllWheelDrive m3 : 7|1@1+ (1,0) [0|0] "" XXX
 SG_ Cluster_FitmentList_VehicleElectrics m3 : 6|1@1+ (1,0) [0|0] "" XXX
 SG_ Cluster_FitmentList_ACC m3 : 5|1@1+ (1,0) [0|0] "" XXX
 SG_ Cluster_FitmentList_Airbag m3 : 4|1@1+ (1,0) [0|0] "" XXX
 SG_ Cluster_Multiplex_Generation m1 : 4|4@1+ (1,0) [0|0] "" XXX
 SG_ Cluster_FitmentList_Climate m3 : 3|1@1+ (1,0) [0|0] "" XXX
 SG_ Cluster_FitmentList_ABS m3 : 2|1@1+ (1,0) [0|0] "" XXX
 SG_ Cluster_FitmentList_Engine m3 : 0|1@1+ (1,0) [0|0] "" XXX
 SG_ Cluster_Multiplex_Derivative m1 : 0|4@1+ (1,0) [0|0] "" XXX
 SG_ Cluster_Multiplex_LanguageVariant m0 : 0|8@1+ (1,0) [0|0] "" XXX
 SG_ Cluster_Multiplex_TyreCircumference m2 : 0|12@1+ (1,0) [0|4095] "mm" XXX

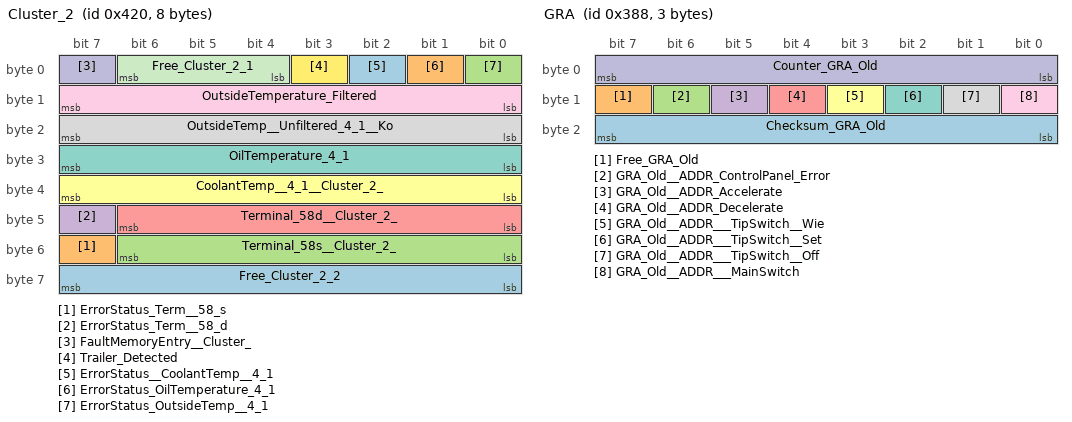
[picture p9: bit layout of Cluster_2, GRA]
BO_ 1056 Cluster_2: 8 XXX
 SG_ Free_Cluster_2_2 : 56|8@1+ (1,0) [0|0] "" XXX
 SG_ ErrorStatus_Term__58_s : 55|1@1+ (1,0) [0|0] "" XXX
 SG_ Terminal_58s__Cluster_2_ : 48|7@1+ (1,0) [0|100] "%" XXX
 SG_ ErrorStatus_Term__58_d : 47|1@1+ (1,0) [0|0] "" XXX
 SG_ Terminal_58d__Cluster_2_ : 40|7@1+ (1,0) [0|100] "%" XXX
 SG_ CoolantTemp__4_1__Cluster_2_ : 32|8@1+ (0.75,-48) [-48|142.5] "C" XXX
 SG_ OilTemperature_4_1 : 24|8@1+ (1,-60) [-60|194] "C" XXX
 SG_ OutsideTemp__Unfiltered_4_1__Ko : 16|8@1+ (0.5,-50) [-50|77] "C" XXX
 SG_ OutsideTemperature_Filtered : 8|8@1+ (0.5,-50) [-50|77] "C" XXX
 SG_ FaultMemoryEntry__Cluster_ : 7|1@1+ (1,0) [0|0] "" XXX
 SG_ Free_Cluster_2_1 : 4|3@1+ (1,0) [0|0] "" XXX
 SG_ Trailer_Detected : 3|1@1+ (1,0) [0|0] "" XXX
 SG_ ErrorStatus__CoolantTemp__4_1 : 2|1@1+ (1,0) [0|0] "" XXX
 SG_ ErrorStatus_OilTemperature_4_1 : 1|1@1+ (1,0) [0|0] "" XXX
 SG_ ErrorStatus_OutsideTemp__4_1 : 0|1@1+ (1,0) [0|0] "" XXX

BO_ 800 Cluster_1: 8 XXX
 SG_ Free_Cluster_1_3 : 56|8@1+ (1,0) [0|0] "" XXX
 SG_ Displayed_Speed : 46|10@1+ (0.32,0) [0|325] "km/h" XXX
 SG_ Indicator_Right_4_1 : 45|1@1+ (1,0) [0|0] "" XXX
 SG_ Indicator_Left_4_1 : 44|1@1+ (1,0) [0|0] "" XXX
 SG_ Set_TimeGap__Cluster_1_ : 43|1@1+ (1,0) [0|0] "" XXX
 SG_ ADDR_Buzzer_SwitchedOff : 42|1@1+ (1,0) [0|0] "" XXX
 SG_ Free_Cluster_1_2 : 40|2@1+ (1,0) [0|0] "" XXX
 SG_ Speed__Cluster_1_ : 25|15@1+ (0.01,0) [0|326] "km/h" XXX
 SG_ SignalSource_Speed_4_ : 24|1@1+ (1,0) [0|0] "" XXX
 SG_ LowFuelWarning : 23|1@1+ (1,0) [0|0] "" XXX
 SG_ TankContents : 16|7@1+ (1,0) [0|126] "l" XXX
 SG_ FuelStop : 15|1@1+ (1,0) [0|0] "" XXX
 SG_ Free_Cluster_1_7 : 12|3@1+ (1,0) [0|0] "" XXX
 SG_ Cluster_In_ActuatorTest : 11|1@1+ (1,0) [0|0] "" XXX
 SG_ ChargeWarning_Lamp__Cluster_ : 10|1@1+ (1,0) [0|0] "" XXX
 SG_ BrakeInfo : 8|2@1+ (1,0) [0|0] "" XXX
 SG_ GlowPlugLamp__Cluster_1_ : 7|1@1+ (1,0) [0|0] "" XXX
 SG_ LowFuelLamp : 6|1@1+ (1,0) [0|0] "" XXX
 SG_ HotWarning_PreWarning : 5|1@1+ (1,0) [0|0] "" XXX
 SG_ CoolantLow : 4|1@1+ (1,0) [0|0] "" XXX
 SG_ Dynamic_OilPressureWarning : 3|1@1+ (1,0) [0|0] "" XXX
 SG_ OilPressure : 2|1@1+ (1,0) [0|0] "" XXX
 SG_ ErrorStatus_Tank : 1|1@1+ (1,0) [0|0] "" XXX
 SG_ DriverDoor_4_1 : 0|1@1+ (1,0) [0|0] "" XXX

BO_ 1504 Climate_1: 8 XXX
 SG_ OutsideTemp__Unfilt__Sto_f__4_1 : 56|8@1+ (0.5,-50) [-50|77] "C" XXX
 SG_ FaultMemoryEntry__Climate_ : 55|1@1+ (1,0) [0|0] "" XXX
 SG_ Free_Climate_1_5 : 50|5@1+ (1,0) [0|0] "" XXX
 SG_ AC_Switch : 49|1@1+ (1,0) [0|0] "" XXX
 SG_ TemperatureUnit : 48|1@1+ (1,0) [0|0] "" XXX
 SG_ RadiatorFanActuation__Klim : 40|8@1+ (0.4,0) [0|101.6] "%" XXX
 SG_ BlowerLoad_4_1 : 32|8@1+ (0.4,0) [0|101.6] "%" XXX
 SG_ CompressorLoad : 24|8@1+ (0.25,0) [0|63.5] "Nm" XXX
 SG_ ClimatePressureSignal__Climate_1_ : 16|8@1+ (0.2,0) [0|50.8] "bar" XXX
 SG_ OutsideTemp__Unfilt__4_1__Climate_1 : 8|8@1+ (0.5,-50) [-50|77] "C" XXX
 SG_ RefrigerantPressure_Outdated : 7|1@1+ (1,0) [0|0] "" XXX
 SG_ CompressorTorque_Outdated_4_1 : 6|1@1+ (1,0) [0|0] "" XXX
 SG_ No_HeatOutput_Requested_4_1 : 5|1@1+ (1,0) [0|0] "" XXX
 SG_ CompressorState__4_1_ : 4|1@1+ (1,0) [0|0] "" XXX
 SG_ Heated_Windscreen : 3|1@1+ (1,0) [0|0] "" XXX
 SG_ Heated_RearWindow : 2|1@1+ (1,0) [0|0] "" XXX
 SG_ DriverDemand_AuxHeater : 1|1@1+ (1,0) [0|0] "" XXX
 SG_ RpmIncrease : 0|1@1+ (1,0) [0|0] "" XXX

BO_ 906 GRA_New: 4 XXX
 SG_ CHECKSUM : 0|8@1+ (1,0) [0|255] "" XXX
 SG_ GRA_MainSwitch : 8|1@1+ (1,0) [0|1] "" XXX
 SG_ GRA_Cancel : 9|1@1+ (1,0) [0|1] "" XXX
 SG_ GRA_Down_Short : 10|1@1+ (1,0) [0|1] "" XXX
 SG_ GRA_Up_Short : 11|1@1+ (1,0) [0|1] "" XXX
 SG_ GRA_Down_Long : 12|1@1+ (1,0) [0|1] "" XXX
 SG_ GRA_Up_Long : 13|1@1+ (1,0) [0|1] "" XXX
 SG_ GRA_Error_Condition : 14|1@1+ (1,0) [0|1] "" XXX
 SG_ GRA_CodingInfo : 15|1@1+ (1,0) [0|1] "" XXX
 SG_ GRA_New_Set : 16|1@1+ (1,0) [0|1] "" XXX
 SG_ GRA_Recall : 17|1@1+ (1,0) [0|1] "" XXX
 SG_ GRA_Transmitter : 18|2@1+ (1,0) [0|3] "" XXX
 SG_ COUNTER : 20|4@1+ (1,0) [0|15] "" XXX
 SG_ GRA_Tip_Down : 24|1@1+ (1,0) [0|1] "" XXX
 SG_ GRA_Tip_Up : 25|1@1+ (1,0) [0|1] "" XXX
 SG_ GRA_TimeGap : 26|2@1+ (1,0) [0|3] "" XXX
 SG_ GRA_Status_Limiter : 28|1@1+ (1,0) [0|1] "" XXX
 SG_ GRA_Type_MainSwitch : 29|1@1+ (1,0) [0|1] "" XXX
 SG_ GRA_SportSwitch : 30|1@1+ (1,0) [0|1] "" XXX
 SG_ GRA_Error_Tip : 31|1@1+ (1,0) [0|1] "" XXX

BO_ 904 GRA: 3 XXX
 SG_ Checksum_GRA_Old : 16|8@1+ (1,0) [0|0] "" XXX
 SG_ Free_GRA_Old : 15|1@1+ (1,0) [0|0] "" XXX
 SG_ GRA_Old__ADDR_ControlPanel_Error : 14|1@1+ (1,0) [0|0] "" XXX
 SG_ GRA_Old__ADDR_Accelerate : 13|1@1+ (1,0) [0|0] "" XXX
 SG_ GRA_Old__ADDR_Decelerate : 12|1@1+ (1,0) [0|0] "" XXX
 SG_ GRA_Old__ADDR___TipSwitch__Wie : 11|1@1+ (1,0) [0|0] "" XXX
 SG_ GRA_Old__ADDR___TipSwitch__Set : 10|1@1+ (1,0) [0|0] "" XXX
 SG_ GRA_Old__ADDR___TipSwitch__Off : 9|1@1+ (1,0) [0|0] "" XXX
 SG_ GRA_Old__ADDR___MainSwitch : 8|1@1+ (1,0) [0|0] "" XXX
 SG_ Counter_GRA_Old : 0|8@1+ (1,0) [0|255] "" XXX

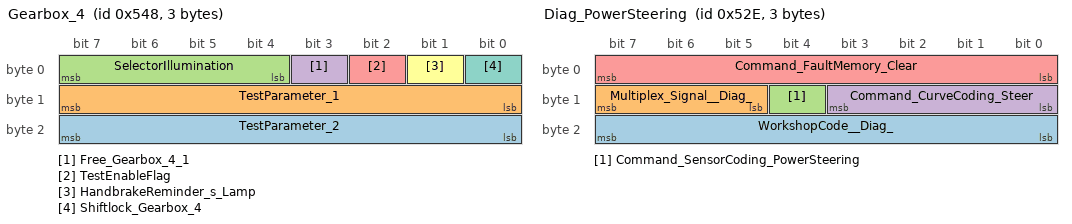
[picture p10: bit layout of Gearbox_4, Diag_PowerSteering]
BO_ 1352 Gearbox_4: 3 XXX
 SG_ TestParameter_2 : 16|8@1+ (1,0) [0|255] "" XXX
 SG_ TestParameter_1 : 8|8@1+ (1,0) [0|255] "" XXX
 SG_ SelectorIllumination : 4|4@1+ (1,0) [0|0] "" XXX
 SG_ Free_Gearbox_4_1 : 3|1@1+ (1,0) [0|0] "" XXX
 SG_ TestEnableFlag : 2|1@1+ (1,0) [0|0] "" XXX
 SG_ HandbrakeReminder_s_Lamp : 1|1@1+ (1,0) [0|0] "" XXX
 SG_ Shiftlock_Gearbox_4 : 0|1@1+ (1,0) [0|0] "" XXX

BO_ 1344 Gearbox_2: 8 XXX
 SG_ Engaged_DriveRange : 60|4@1+ (1,0) [0|0] "" XXX
 SG_ GearDisplay_Cluster___Gearbox_Va : 56|4@1+ (1,0) [0|15] "" XXX
 SG_ FaultLamp_f_r_Clutch_At_VL : 55|1@1+ (1,0) [0|0] "" XXX
 SG_ Request_CreepAdaptation : 54|1@1+ (1,0) [0|0] "" XXX
 SG_ ECO_Display__4_1_ : 53|1@1+ (1,0) [0|0] "" XXX
 SG_ Shift_Lock_Lamp : 52|1@1+ (1,0) [0|0] "" XXX
 SG_ Suppression_From_Warnings : 51|1@1+ (1,0) [0|0] "" XXX
 SG_ Chime : 50|1@1+ (1,0) [0|0] "" XXX
 SG_ Starter_Is_Actuated : 49|1@1+ (1,0) [0|0] "" XXX
 SG_ HighShiftLamp : 48|1@1+ (1,0) [0|0] "" XXX
 SG_ SyncTime : 40|8@1+ (20,0) [0|5080] "ms" XXX
 SG_ Inverted_Synchronisation_Wu : 32|8@1+ (25,0) [0|6350] "U/min" XXX
 SG_ Synchronisation_RequestedRpm : 24|8@1+ (25,0) [0|6350] "U/min" XXX
 SG_ GradientLimit : 16|8@1+ (10,0) [0|2540] "Nm/s" XXX
 SG_ IdleTargetRpm__Gearbox : 8|8@1+ (10,0) [0|2540] "U/min" XXX
 SG_ Zahler_Gearbox_2 : 4|4@1+ (1,0) [0|15] "" XXX
 SG_ ThrottleBlipFlag : 3|1@1+ (1,0) [0|0] "" XXX
 SG_ Ecomatic__4_1_ : 2|1@1+ (1,0) [0|0] "" XXX
 SG_ OverrunCutSupport : 1|1@1+ (1,0) [0|0] "" XXX
 SG_ LFR_Adaptation_EnableFlag : 0|1@1+ (1,0) [0|0] "" XXX

BO_ 1088 Gearbox_1: 8 Transmission
 SG_ GE1_Shift : 0|1@1+ (1,0) [0|1] "" Gateway
 SG_ GE1_Status_Protection : 1|1@1+ (1,0) [0|1] "" Motor
 SG_ GE1_AcCompressor : 2|1@1+ (1,0) [0|1] "" Motor
 SG_ GE1_WK : 3|2@1+ (1,0) [0|3] "" Gateway
 SG_ GE1_StSt_Info : 5|2@1+ (1,0) [0|3] "" Gateway
 SG_ GE1_EGS_Req : 7|1@1+ (1,0) [0|1] "" Motor
 SG_ GE1_TargetGear : 8|4@1+ (1,0) [0|15] "" Gateway
 SG_ GE1_Selection_Pos : 12|4@1+ (1,0) [0|15] "" Gateway
 SG_ GE1_Mrad_CrankTorque : 16|8@1+ (0.1,0) [0|25.4] "" Gateway
 SG_ GE1_Target_Mo : 24|8@1+ (0.39,0) [0|99.06] "%" Motor
 SG_ GE1_Fahrwistd : 32|8@1+ (0.249,-31.623) [-31.623|31.623] "" Gateway
 SG_ GE1_LimpHome : 40|4@1+ (1,0) [0|15] "" Gateway
 SG_ GE1_Cooling : 44|2@1+ (1,0) [0|3] "" Gateway
 SG_ GE1_Status_OBD : 47|1@1+ (1,0) [0|1] "" Motor
 SG_ GE1_LaunchControl : 48|1@1+ (1,0) [0|1] "" ESP
 SG_ GE1_InfoBit : 49|1@1+ (1,0) [0|1] "" Gateway
 SG_ GE1_SleepInd : 50|1@1+ (1,0) [0|1] "" Gateway
 SG_ COUNTER : 51|4@1+ (1,0) [0|15] "" Gateway
 SG_ GE1_FaultEntry : 55|1@1+ (1,0) [0|1] "" Gateway
 SG_ GE1_WaVerl_Mo : 56|8@1+ (0.39,0) [0|99.06] "%" Motor

BO_ 912 Gate_Comfort_1: 8 XXX
 SG_ GK1_Status_RDK_Warn : 0|1@1+ (1,0) [0|1] "" XXX
 SG_ GK1_Status_Trailer : 1|1@1+ (1,0) [0|1] "" XXX
 SG_ GK1_Status_Light1 : 2|1@1+ (1,0) [0|1] "" XXX
 SG_ GK1_Status_Light3 : 3|1@1+ (1,0) [0|1] "" XXX
 SG_ GK1_Status_DoorContact : 4|1@1+ (1,0) [0|1] "" XXX
 SG_ GK1_Status_Left_Front : 5|1@1+ (1,0) [0|1] "" XXX
 SG_ GK1_SleepAckn : 7|1@1+ (1,0) [0|1] "" XXX
 SG_ GK1_CharismaMode m1 : 8|4@1+ (1,0) [0|15] "" XXX
 SG_ GK1_SamFuncNr M : 12|4@1+ (1,0) [0|15] "" XXX
 SG_ GK1_Fa_DoorContact : 16|1@1+ (1,0) [0|1] "" XXX
 SG_ GK1_ReverseSch : 17|1@1+ (1,0) [0|1] "" XXX
 SG_ GK1_ELV_Lock : 18|1@1+ (1,0) [0|1] "" XXX
 SG_ GK1_Status_Kessy_2 : 19|1@1+ (1,0) [0|1] "" XXX
 SG_ GK1_Status_AuxHeater : 20|1@1+ (1,0) [0|1] "" XXX
 SG_ GK1_SH_Fitment : 21|1@1+ (1,0) [0|1] "" XXX
 SG_ GK1_ParkFrontWi : 22|1@1+ (1,0) [0|1] "" XXX
 SG_ GK1_KW_Warm : 23|1@1+ (1,0) [0|1] "" XXX
 SG_ BCM_Remotestart_Operation : 24|1@1+ (1,0) [0|1] "" XXX
 SG_ BSK_HL_Opened : 26|1@1+ (1,0) [0|1] "" XXX
 SG_ BSK_HR_Opened : 27|1@1+ (1,0) [0|1] "" XXX
 SG_ GK1_Reverse : 28|1@1+ (1,0) [0|1] "" XXX
 SG_ GK1_BrLeft_Left : 29|1@1+ (1,0) [0|1] "" XXX
 SG_ GK1_BrLeft_Right : 30|1@1+ (1,0) [0|1] "" XXX
 SG_ GK1_BrLeft_Centre : 31|1@1+ (1,0) [0|1] "" XXX
 SG_ GK1_BLS_ILM : 32|1@1+ (1,0) [0|1] "" XXX
 SG_ GK1_EDC_ILM : 33|1@1+ (1,0) [0|1] "" XXX
 SG_ GK1_Indicator_Left : 34|1@1+ (1,0) [0|1] "" XXX
 SG_ GK1_Indicator_Right : 35|1@1+ (1,0) [0|1] "" XXX
 SG_ GK1_def_P_Lock : 36|1@1+ (1,0) [0|1] "" XXX
 SG_ GK1_LS1_HighBeam : 37|1@1+ (1,0) [0|1] "" XXX
 SG_ GK1_Status_Light2 : 38|1@1+ (1,0) [0|1] "" XXX
 SG_ GK1_Status_LSM : 39|1@1+ (1,0) [0|1] "" XXX
 SG_ GK1_Count_Trailer : 40|4@1+ (1,0) [0|15] "" XXX
 SG_ BSK_BT_Opened : 41|1@1+ (1,0) [0|1] "" XXX
 SG_ BSK_HD_MainDetent : 43|1@1+ (1,0) [0|1] "" XXX
 SG_ GK1_BLS_AAG : 44|1@1+ (1,0) [0|1] "" XXX
 SG_ GK1_EDC_AAG : 45|1@1+ (1,0) [0|1] "" XXX
 SG_ GK1_Trailer : 46|1@1+ (1,0) [0|1] "" XXX
 SG_ GK1_BrLeft_Trailer : 47|1@1+ (1,0) [0|1] "" XXX
 SG_ GK1_LowBeam : 48|1@1+ (1,0) [0|1] "" XXX
 SG_ GK1_HighBeam : 49|1@1+ (1,0) [0|1] "" XXX
 SG_ GK1_Wiper_Front : 50|1@1+ (1,0) [0|1] "" XXX
 SG_ GK1_Status_ILM_F_1 : 51|1@1+ (1,0) [0|1] "" XXX
 SG_ GK1_LowBeam_VL_def : 52|1@1+ (1,0) [0|1] "" XXX
 SG_ GK1_LowBeam_VR_def : 53|1@1+ (1,0) [0|1] "" XXX
 SG_ GK1_Flash_Motorway : 54|1@1+ (1,0) [0|1] "" XXX
 SG_ GK1_HazardFlash_Status : 55|1@1+ (1,0) [0|1] "" XXX
 SG_ GK1_SH_Running : 56|1@1+ (1,0) [0|1] "" XXX
 SG_ SH1_On_WaterPump : 57|1@1+ (1,0) [0|1] "" XXX
 SG_ GK1_Fog_On : 58|1@1+ (1,0) [0|1] "" XXX
 SG_ GK1_BrakeLight : 59|1@1+ (1,0) [0|1] "" XXX
 SG_ GK1_Trailer_Unplugged : 60|1@1+ (1,0) [0|1] "" XXX
 SG_ GK1_TrailerKonLamp : 61|1@1+ (1,0) [0|1] "" XXX
 SG_ LDS_Position_AFL : 62|1@1+ (1,0) [0|1] "" XXX
 SG_ GK1_SH_AdditionalFunc : 63|1@1+ (1,0) [0|1] "" XXX

BO_ 1340 Chassis_1: 1 XXX
 SG_ Free_Chassis_1_2 : 7|1@1+ (1,0) [0|0] "" XXX
 SG_ Free_Chassis_1_1 : 6|2@1+ (1,0) [0|0] "" XXX
 SG_ OnPosition_ChassisDamping_4 : 4|3@1+ (1,0) [0|7] "" XXX
 SG_ Actuation_VehicleLevel : 0|4@1+ (1,0) [0|15] "" XXX

BO_ 1472 EPB_1: 8 XXX
 SG_ COUNTER : 0|4@1+ (1,0) [0|15] "" XXX
 SG_ EP1_Error_Status : 4|2@1+ (1,0) [0|3] "" Vector__XXX
 SG_ EP1_Status_EPB : 6|1@1+ (1,0) [0|1] "" XXX
 SG_ EP1_Status_Switch : 7|1@1+ (1,0) [0|1] "" XXX
 SG_ EP1_ClampForce : 8|5@1+ (1,0) [0|30] "Unit_KiloNewto" XXX
 SG_ EP1_SwitchInfo : 13|2@1+ (1,0) [0|3] "" XXX
 SG_ EP1_Status_NWS : 15|1@1+ (1,0) [0|1] "" XXX
 SG_ EP1_Tilt_Angle : 16|8@1+ (1,-128) [-128|127] "Unit_PerCentOfForceOfGravi" XXX
 SG_ EP1_Deceleration : 24|8@1+ (0.048,-7.968) [-7.968|4.224] "Unit_MeterPerSeconSquar" XXX
 SG_ EP1_FaultEntry : 32|1@1+ (1,0) [0|1] "" XXX
 SG_ EP1_Enable_Ver : 33|1@1+ (1,0) [0|1] "" XXX
 SG_ EP1_AutoHold_Allowed : 34|1@1+ (1,0) [0|1] "" XXX
 SG_ EP1_AutoHold_Active : 35|1@1+ (1,0) [0|1] "" XXX
 SG_ EP1_SleepInd : 36|1@1+ (1,0) [0|1] "" XXX
 SG_ EP1_Status_Term_15 : 37|1@1+ (1,0) [0|1] "" XXX
 SG_ EP1_Lamp_AutoP : 38|1@1+ (1,0) [0|1] "" XXX
 SG_ EP1_BrakeLight : 39|1@1+ (1,0) [0|1] "" XXX
 SG_ EP1_WarningTone1 : 40|1@1+ (1,0) [0|1] "" XXX
 SG_ EP1_WarningTone2 : 41|1@1+ (1,0) [0|1] "" XXX
 SG_ EP1_ReqShLock : 42|1@1+ (1,0) [0|1] "" XXX
 SG_ EPB_AutoHoldLamp : 43|1@1+ (1,0) [0|1] "" XXX
 SG_ EP1_QualTiltWi : 44|1@1+ (1,0) [0|1] "" XXX
 SG_ EP1_ClutchModRange : 45|2@1+ (1,0) [0|3] "" XXX
 SG_ EP1_HydraulicHold : 47|1@1+ (1,0) [0|1] "" XXX
 SG_ EP1_Func_Lamp : 48|1@1+ (1,0) [0|1] "" Vector__XXX
 SG_ EP1_WarningTone : 49|1@1+ (1,0) [0|1] "" XXX
 SG_ EP1_Error_BKL : 50|1@1+ (1,0) [0|1] "" Vector__XXX
 SG_ EP1_Error_Yellow : 51|1@1+ (1,0) [0|1] "" XXX
 SG_ EP1__Text : 52|4@1+ (1,0) [0|8] "" Vector__XXX
 SG_ CHECKSUM : 56|8@1+ (1,0) [0|255] "" XXX

BO_ 1326 Diag_PowerSteering: 3 XXX
 SG_ WorkshopCode__Diag_ : 16|8@1+ (1,0) [0|0] "" XXX
 SG_ Multiplex_Signal__Diag_ : 13|3@1+ (1,0) [0|7] "" XXX
 SG_ Command_SensorCoding_PowerSteering : 12|1@1+ (1,0) [0|0] "" XXX
 SG_ Command_CurveCoding_Steer : 8|4@1+ (1,0) [0|0] "" XXX
 SG_ Command_FaultMemory_Clear : 0|8@1+ (1,0) [0|0] "" XXX

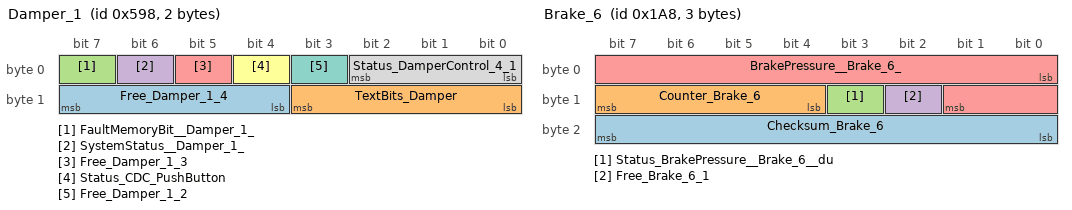
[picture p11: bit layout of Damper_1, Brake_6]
BO_ 1432 Damper_1: 2 XXX
 SG_ Free_Damper_1_4 : 12|4@1+ (1,0) [0|0] "" XXX
 SG_ TextBits_Damper : 8|4@1+ (1,0) [0|0] "" XXX
 SG_ FaultMemoryBit__Damper_1_ : 7|1@1+ (1,0) [0|0] "" XXX
 SG_ SystemStatus__Damper_1_ : 6|1@1+ (1,0) [0|0] "" XXX
 SG_ Free_Damper_1_3 : 5|1@1+ (1,0) [0|0] "" XXX
 SG_ Status_CDC_PushButton : 4|1@1+ (1,0) [0|0] "" XXX
 SG_ Free_Damper_1_2 : 3|1@1+ (1,0) [0|0] "" XXX
 SG_ Status_DamperControl_4_1 : 0|3@1+ (1,0) [0|7] "" XXX

BO_ 1392 BodyECU_Load: 4 XXX
 SG_ AirCon_SwitchOff : 31|1@1+ (1,0) [0|0] "" XXX
 SG_ SeatVentilation_SwitchOff : 30|1@1+ (1,0) [0|0] "" XXX
 SG_ WasherFluidHeater_SwitchOff : 29|1@1+ (1,0) [0|0] "" XXX
 SG_ SteeringWheelHeating_SwitchOff : 28|1@1+ (1,0) [0|0] "" XXX
 SG_ Heated_Seats_SwitchOff : 27|1@1+ (1,0) [0|0] "" XXX
 SG_ Heated_DoorMirror_Shutoff : 26|1@1+ (1,0) [0|0] "" XXX
 SG_ Heated_Windscreen_Shutoff : 25|1@1+ (1,0) [0|0] "" XXX
 SG_ Heated_RearWindow_SwitchOff : 24|1@1+ (1,0) [0|0] "" XXX
 SG_ BatteryVoltage_VehicleBattery : 16|8@1+ (0.05,5) [5|17.7] "V" XXX
 SG_ BonnetContact : 15|1@1+ (1,0) [0|0] "" XXX
 SG_ HeadlightLevelling : 14|1@1+ (1,0) [0|0] "" XXX
 SG_ FaultMemoryEntry__BodyECU_Load : 13|1@1+ (1,0) [0|0] "" XXX
 SG_ State_The_StarterBattery : 11|2@1+ (1,0) [0|0] "" XXX
 SG_ State_The_VehicleElectricsBattery : 9|2@1+ (1,0) [0|0] "" XXX
 SG_ LL_RpmIncrease : 8|1@1+ (1,0) [0|0] "" XXX
 SG_ Terminal_L : 7|1@1+ (1,0) [0|0] "" XXX
 SG_ Free_BodyECU_Load_1_1 : 4|3@1+ (1,0) [0|0] "" XXX
 SG_ ZAS_Terminal_50 : 3|1@1+ (1,0) [0|0] "" XXX
 SG_ ZAS_Terminal_X : 2|1@1+ (1,0) [0|0] "" XXX
 SG_ ZAS_Terminal_15 : 1|1@1+ (1,0) [0|0] "" XXX
 SG_ ZAS_Terminal_S : 0|1@1+ (1,0) [0|0] "" XXX

BO_ 1136 BodyECU_Cluster: 5 XXX
 SG_ Free_BodyECU_Cluster_1_3 : 36|4@1+ (1,0) [0|0] "" XXX
 SG_ RearBackrest_HR_Lock__4_1 : 35|1@1+ (1,0) [0|0] "" XXX
 SG_ RearBackrest_HL_Lock__4_1 : 34|1@1+ (1,0) [0|0] "" XXX
 SG_ FaultLamp_PowerSteering_Outdated : 33|1@1+ (1,0) [0|0] "" XXX
 SG_ FaultLamp_PowerSteering__BodyECU_Komb : 32|1@1+ (1,0) [0|0] "" XXX
 SG_ ErrorStatus_Term__58s : 31|1@1+ (1,0) [0|0] "" XXX
 SG_ Terminal_58s__BodyECU_Cluster_ : 24|7@1+ (1,0) [0|100] "%" XXX
 SG_ ErrorStatus_Term__58d : 23|1@1+ (1,0) [0|0] "" XXX
 SG_ Terminal_58d__BodyECU_Cluster_ : 16|7@1+ (1,0) [0|100] "%" XXX
 SG_ Undervoltage : 15|1@1+ (1,0) [0|0] "" XXX
 SG_ Free_BodyECU_Cluster_1_2 : 14|1@1+ (1,0) [0|0] "" XXX
 SG_ Tailgate_Opened : 13|1@1+ (1,0) [0|0] "" XXX
 SG_ Bonnet_Opened : 12|1@1+ (1,0) [0|0] "" XXX
 SG_ Door_Rear_Right_Opened : 11|1@1+ (1,0) [0|0] "" XXX
 SG_ Door_Rear_Left_Opened : 10|1@1+ (1,0) [0|0] "" XXX
 SG_ PassengerDoor_Opened : 9|1@1+ (1,0) [0|0] "" XXX
 SG_ DriverDoor_Opened : 8|1@1+ (1,0) [0|0] "" XXX
 SG_ Charge_TellTale : 7|1@1+ (1,0) [0|0] "" XXX
 SG_ Free_BodyECU_Cluster_1_1 : 6|1@1+ (1,0) [0|0] "" XXX
 SG_ ReversingLight : 5|1@1+ (1,0) [0|0] "" XXX
 SG_ DWA_Accumulator : 4|1@1+ (1,0) [0|0] "" XXX
 SG_ HazardFlash_Mode : 3|1@1+ (1,0) [0|0] "" XXX
 SG_ Trailer_TellTale : 2|1@1+ (1,0) [0|0] "" XXX
 SG_ Indicator_Right_TellTale : 1|1@1+ (1,0) [0|0] "" XXX
 SG_ Indicator_Left_TellTale : 0|1@1+ (1,0) [0|0] "" XXX

BO_ 424 Brake_6: 3 XXX
 SG_ Checksum_Brake_6 : 16|8@1+ (1,0) [0|0] "" XXX
 SG_ Counter_Brake_6 : 12|4@1+ (1,0) [0|15] "" XXX
 SG_ Status_BrakePressure__Brake_6__du : 11|1@1+ (1,0) [0|0] "" XXX
 SG_ Free_Brake_6_1 : 10|1@1+ (1,0) [0|0] "" XXX
 SG_ BrakePressure__Brake_6_ : 0|10@1+ (0.3255,-40) [-40|293] "bar" XXX

BO_ 1192 Brake_5: 8 XXX
 SG_ CHECKSUM : 56|8@1+ (1,0) [0|0] "" XXX
 SG_ COUNTER : 52|4@1+ (1,0) [0|15] "" XXX
 SG_ BR5_ECD_Lamp : 51|1@1+ (1,0) [0|0] "" XXX
 SG_ BR5_ZT_Rueckk_Convert : 48|1@1+ (1,0) [0|1] "" XXX
 SG_ BR5_Anhi_Status : 40|1@1+ (1,0) [0|1] "" XXX
 SG_ ESP_RollerMode_Deactivate : 34|1@1+ (1,0) [0|1] "" XXX
 SG_ BR5_Sign_Pressure : 31|1@1+ (1,0) [0|1] "" XXX
 SG_ BR5_Status_Pressure : 30|1@1+ (1,0) [0|1] "" XXX
 SG_ BR5_PressureValid : 29|1@1+ (1,0) [0|1] "" XXX
 SG_ BR5_Standstill : 28|1@1+ (1,0) [0|1] "" XXX
 SG_ BR5_BrakePressure : 16|12@1+ (0.1,0) [0|250] "bar" XXX
 SG_ BR5_Sign : 15|1@1+ (1,0) [0|1] "" XXX
 SG_ BR5_Status_YawRate : 14|1@1+ (1,0) [0|1] "" XXX
 SG_ BR5_YawRate : 0|14@1+ (0.01,0) [0|100] "Grad/sec" XXX
 SG_ BR5_ANB_CM_Rueckk_Convert : 49|1@1+ (1,0) [0|1] "" XXX
 SG_ BR5_HDC_Ready : 50|1@1+ (1,0) [0|1] "" XXX
 SG_ ESP_Status_FallBack_eBKV : 35|1@1+ (1,0) [0|1] "" XXX
 SG_ ESP_Request_EPB : 36|2@1+ (1,0) [0|3] "" XXX
 SG_ ESP_AutoHold_active : 38|1@1+ (1,0) [0|1] "" XXX
 SG_ ESP_AutoHold_Standby : 39|1@1+ (1,0) [0|1] "" XXX
 SG_ BR5_Anhi_Act : 41|1@1+ (1,0) [0|1] "" XXX
 SG_ BR5_v_Monitor : 42|1@1+ (1,0) [0|1] "" XXX
 SG_ BR5_BrakeLight : 43|1@1+ (1,0) [0|1] "" XXX
 SG_ BR5_EmergencyBraking : 44|1@1+ (1,0) [0|1] "" XXX
 SG_ BR5_Driver_Occurs_ZBR_Threshold : 45|1@1+ (1,0) [0|1] "" XXX
 SG_ BR5_AWV2_BrakeJerk : 46|1@1+ (1,0) [0|1] "" XXX
 SG_ BR5_AWV2_Error : 47|1@1+ (1,0) [0|1] "" XXX

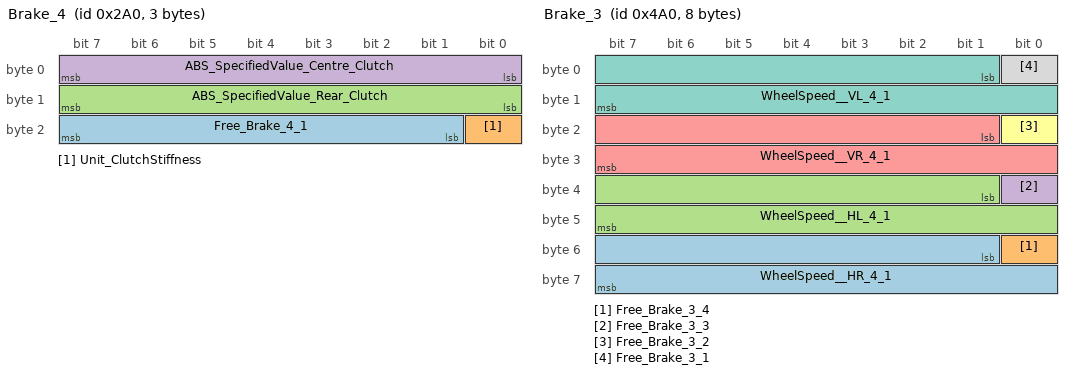
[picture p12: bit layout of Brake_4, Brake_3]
BO_ 672 Brake_4: 3 XXX
 SG_ Free_Brake_4_1 : 17|7@1+ (1,0) [0|0] "" XXX
 SG_ Unit_ClutchStiffness : 16|1@1+ (1,0) [0|0] "" XXX
 SG_ ABS_SpecifiedValue_Rear_Clutch : 8|8@1+ (0.7874,0) [0|100] "%" XXX
 SG_ ABS_SpecifiedValue_Centre_Clutch : 0|8@1+ (3,-381) [-381|378] "Nm/min" XXX

BO_ 1184 Brake_3: 8 XXX
 SG_ WheelSpeed__HR_4_1 : 49|15@1+ (0.01,0) [0|326] "km/h" XXX
 SG_ Free_Brake_3_4 : 48|1@1+ (1,0) [0|0] "" XXX
 SG_ WheelSpeed__HL_4_1 : 33|15@1+ (0.01,0) [0|326] "km/h" XXX
 SG_ Free_Brake_3_3 : 32|1@1+ (1,0) [0|0] "" XXX
 SG_ WheelSpeed__VR_4_1 : 17|15@1+ (0.01,0) [0|326] "km/h" XXX
 SG_ Free_Brake_3_2 : 16|1@1+ (0.01,0) [0|325] "km/h" XXX
 SG_ WheelSpeed__VL_4_1 : 1|15@1+ (0.01,0) [0|326] "km/h" XXX
 SG_ Free_Brake_3_1 : 0|1@1+ (1,0) [0|0] "" XXX

BO_ 1440 Brake_2: 8 XXX
 SG_ Measured_LateralAccel : 63|1@1+ (1,0) [0|0] "" XXX
 SG_ Free_Brake_2_2 : 62|1@1+ (1,0) [0|0] "" XXX
 SG_ PulseCount : 56|6@1+ (1,0) [0|63] "" XXX
 SG_ ErrorStatus_DistancePulses_4_1 : 55|1@1+ (1,0) [0|0] "" XXX
 SG_ Free_Brake_2_5 : 54|1@1+ (1,0) [0|0] "" XXX
 SG_ WarningLamp_DDS : 53|1@1+ (1,0) [0|0] "" XXX
 SG_ FaultMemoryEntry_Brake : 52|1@1+ (1,0) [0|0] "" XXX
 SG_ DistPulseCounterStatus : 51|1@1+ (1,0) [0|0] "" XXX
 SG_ DistancePulses_FrontAxle : 40|11@1+ (1,0) [0|2047] "" XXX
 SG_ Timestamp : 24|16@1+ (1,0) [0|65535] "tics" XXX
 SG_ Average_WheelSpeed__Brake_2 : 9|15@1+ (0.002,0) [0|65.278] "U/sec" XXX
 SG_ LatAccel__TimerTic M : 8|1@1+ (1,0) [0|0] "" XXX
 SG_ Timer m1 : 0|8@1+ (0.04,0) [0|10.2] "usec" XXX
 SG_ LateralAccel m0 : 0|8@1+ (0.01,-1.27) [-1.27|1.27] "g" XXX

BO_ 416 Brake_1: 8 ABS
 SG_ BR1_ASR_Req : 0|1@1+ (1,0) [0|1] "" Motor
 SG_ BR1_MSR_Req M : 1|1@1+ (1,0) [0|1] "" Motor
 SG_ BR1_ABS_Brake : 2|1@1+ (1,0) [0|1] "" XXX
 SG_ BR1_EDS_OnGround : 3|1@1+ (1,0) [0|1] "" XXX
 SG_ BR1_ESP_OnGround : 4|1@1+ (1,0) [0|1] "" XXX
 SG_ BR1_ASR_OnGround : 5|2@1+ (1,0) [0|3] "" Transmission
 SG_ BR1_EBV_OnGround : 7|1@1+ (1,0) [0|1] "" XXX
 SG_ BR1_Lamp_ABS : 8|1@1+ (1,0) [0|1] "" XXX
 SG_ BR1_Lamp_ASR : 9|1@1+ (1,0) [0|1] "" XXX
 SG_ BR1_Lamp_BK : 10|1@1+ (1,0) [0|1] "" XXX
 SG_ BR1_LightShift : 11|1@1+ (1,0) [0|1] "" XXX
 SG_ BR1_StatusPressureThreshold : 12|1@1+ (1,0) [0|1] "" XXX
 SG_ BR1_MAD : 13|1@1+ (1,0) [0|1] "" XXX
 SG_ BR1_Status_MAD : 14|1@1+ (1,0) [0|1] "" XXX
 SG_ BR1_Diagnostics : 15|1@1+ (1,0) [0|1] "" XXX
 SG_ BR1_BKV_active : 16|1@1+ (1,0) [0|1] "" XXX
 SG_ BR1_Wheel_kmh : 17|15@1+ (0.01,0) [0|326.39] "km/h" XXX
 SG_ BR1_ASRMo_sl : 32|8@1+ (0.39,0) [0|99.06] "%" Motor
 SG_ BR1_ASRMo_fa m0 : 40|8@1+ (0.39,0) [0|99.06] "%" Motor
 SG_ BR1_MSR_Mo_inv m1 : 40|8@1+ (-0.39,99.45) [0|99.06] "%" Motor
 SG_ BR1_MSR_Mo : 48|8@1+ (0.39,0) [0|99.06] "%" Motor
 SG_ BR1_Counter : 56|4@1+ (1,0) [0|15] "" XXX
 SG_ BR1_ASR_ESP : 60|1@1+ (1,0) [0|1] "" XXX
 SG_ BR1_ESPASR_passive : 61|1@1+ (1,0) [0|1] "" XXX
 SG_ BR1_Status_ESP : 62|1@1+ (1,0) [0|1] "" XXX
 SG_ BR1_Substitute_Kmh : 63|1@1+ (1,0) [0|1] "" XXX

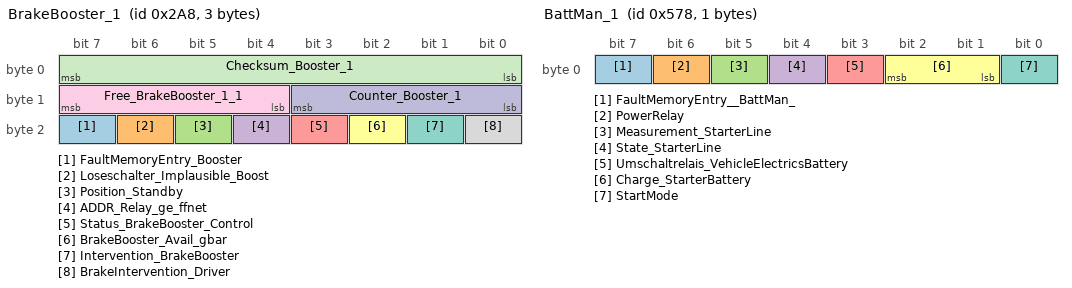
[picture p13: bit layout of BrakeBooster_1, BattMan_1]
BO_ 680 BrakeBooster_1: 3 XXX
 SG_ FaultMemoryEntry_Booster : 23|1@1+ (1,0) [0|0] "" XXX
 SG_ Loseschalter_Implausible_Boost : 22|1@1+ (1,0) [0|0] "" XXX
 SG_ Position_Standby : 21|1@1+ (1,0) [0|0] "" XXX
 SG_ ADDR_Relay_ge_ffnet : 20|1@1+ (1,0) [0|0] "" XXX
 SG_ Status_BrakeBooster_Control : 19|1@1+ (1,0) [0|0] "" XXX
 SG_ BrakeBooster_Avail_gbar : 18|1@1+ (1,0) [0|0] "" XXX
 SG_ Intervention_BrakeBooster : 17|1@1+ (1,0) [0|0] "" XXX
 SG_ BrakeIntervention_Driver : 16|1@1+ (1,0) [0|0] "" XXX
 SG_ Free_BrakeBooster_1_1 : 12|4@1+ (1,0) [0|0] "" XXX
 SG_ Counter_Booster_1 : 8|4@1+ (1,0) [0|15] "" XXX
 SG_ Checksum_Booster_1 : 0|8@1+ (1,0) [0|0] "" XXX

BO_ 1400 BattMan_1: 1 XXX
 SG_ FaultMemoryEntry__BattMan_ : 7|1@1+ (1,0) [0|0] "" XXX
 SG_ PowerRelay : 6|1@1+ (1,0) [0|0] "" XXX
 SG_ Measurement_StarterLine : 5|1@1+ (1,0) [0|0] "" XXX
 SG_ State_StarterLine : 4|1@1+ (1,0) [0|0] "" XXX
 SG_ Umschaltrelais_VehicleElectricsBattery : 3|1@1+ (1,0) [0|0] "" XXX
 SG_ Charge_StarterBattery : 1|2@1+ (1,0) [0|0] "" XXX
 SG_ StartMode : 0|1@1+ (1,0) [0|0] "" XXX

BO_ 704 AllWheelDrive_1: 5 XXX
 SG_ ClutchStiffness_Rear__Is : 32|8@1+ (0.7874,0) [0|100] "%" XXX
 SG_ FaultMemoryEntry_AllWheelDrive_1 : 31|1@1+ (1,0) [0|0] "" XXX
 SG_ Free_AllWheelDrive_1_1 : 26|5@1+ (1,0) [0|0] "" XXX
 SG_ Shift_PreWarning : 25|1@1+ (1,0) [0|0] "" XXX
 SG_ Shift_Active__AllWheelDrive_1_ : 24|1@1+ (1,0) [0|0] "" XXX
 SG_ GearInfo__PNG_ : 20|4@1+ (1,0) [0|0] "" XXX
 SG_ PNG_Display_Flashing : 19|1@1+ (1,0) [0|0] "" XXX
 SG_ PNG_Status_4_1 : 16|3@1+ (1,0) [0|0] "" XXX
 SG_ ClutchStiffness_Centre__Actual : 8|8@1+ (3,-381) [-381|378] "Nm/min" XXX
 SG_ Unit_The_Kupplungssteifigkei : 7|1@1+ (1,0) [0|0] "" XXX
 SG_ SpeedLimit : 6|1@1+ (1,0) [0|0] "" XXX
 SG_ AllWheelDrive_WarningLamp : 5|1@1+ (1,0) [0|0] "" XXX
 SG_ LimpHome : 4|1@1+ (1,0) [0|0] "" XXX
 SG_ Clutch_Complete_Open : 3|1@1+ (1,0) [0|0] "" XXX
 SG_ ErrorStatus_Kupplungssteifigke : 2|1@1+ (1,0) [0|0] "" XXX
 SG_ Ubertemperaturschutz__AllWheelDrive_1_ : 1|1@1+ (1,0) [0|0] "" XXX
 SG_ Error_AllWheelDrive_Clutch : 0|1@1+ (1,0) [0|0] "" XXX

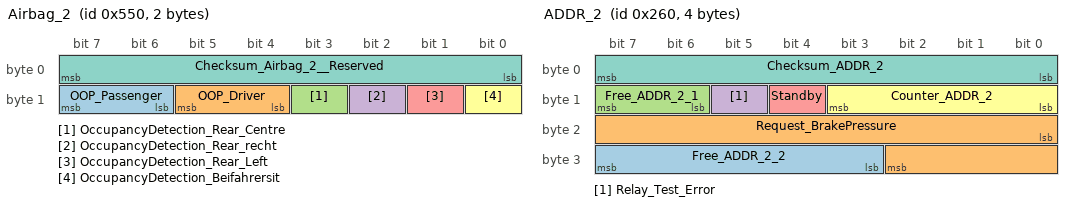
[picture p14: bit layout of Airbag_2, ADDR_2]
BO_ 1360 Airbag_2: 2 XXX
 SG_ OOP_Passenger : 14|2@1+ (1,0) [0|0] "" XXX
 SG_ OOP_Driver : 12|2@1+ (1,0) [0|0] "" XXX
 SG_ OccupancyDetection_Rear_Centre : 11|1@1+ (1,0) [0|0] "" XXX
 SG_ OccupancyDetection_Rear_recht : 10|1@1+ (1,0) [0|0] "" XXX
 SG_ OccupancyDetection_Rear_Left : 9|1@1+ (1,0) [0|0] "" XXX
 SG_ OccupancyDetection_Beifahrersit : 8|1@1+ (1,0) [0|0] "" XXX
 SG_ Checksum_Airbag_2__Reserved : 0|8@1+ (1,0) [0|0] "" XXX

BO_ 80 Airbag_1: 4 XXX
 SG_ CHECKSUM : 24|8@1+ (1,0) [0|0] "" XXX
 SG_ COUNTER : 20|4@1+ (1,0) [0|15] "" XXX
 SG_ FaultMemoryEntry : 19|1@1+ (1,0) [0|0] "" XXX
 SG_ Free_Airbag_1_2 : 18|1@1+ (1,0) [0|0] "" XXX
 SG_ Airbag_In_ActuatorTest : 17|1@1+ (1,0) [0|0] "" XXX
 SG_ Airbag_in_Diagnostics : 16|1@1+ (1,0) [0|0] "" XXX
 SG_ BeltWarning_Passenger : 15|1@1+ (1,0) [0|0] "" XXX
 SG_ BeltSwitch_Passenger : 14|1@1+ (1,0) [0|0] "" XXX
 SG_ BeltWarning_Driver : 13|1@1+ (1,0) [0|0] "" XXX
 SG_ BeltSwitch_Driver : 12|1@1+ (1,0) [0|0] "" XXX
 SG_ Airbag_SystemError : 11|1@1+ (1,0) [0|0] "" XXX
 SG_ Kindersitzerkennung : 10|1@1+ (1,0) [0|0] "" XXX
 SG_ Airbag_Deactivated : 9|1@1+ (1,0) [0|0] "" XXX
 SG_ Airbag_Lamp : 8|1@1+ (1,0) [0|0] "" XXX
 SG_ Crash_Intensity : 5|3@1+ (1,0) [0|111] "B" XXX
 SG_ Rollover : 4|1@1+ (1,0) [0|0] "" XXX
 SG_ Side_Crash_Passenger : 3|1@1+ (1,0) [0|0] "" XXX
 SG_ Side_Crash_Driver : 2|1@1+ (1,0) [0|0] "" XXX
 SG_ Rear_Crash : 1|1@1+ (1,0) [0|0] "" XXX
 SG_ Front_Crash : 0|1@1+ (1,0) [0|0] "" XXX

BO_ 864 ADDR_System: 8 XXX
 SG_ S_Checksum_ADDR_1 : 56|8@1+ (1,0) [0|0] "" XXX
 SG_ S_Free_ADDR_1_1 : 52|4@1+ (1,0) [0|0] "" XXX
 SG_ S_TimeGap_Measured : 48|4@1+ (1,0) [0|15] "" XXX
 SG_ S_FaultMemoryEntry_ADDR : 47|1@1+ (1,0) [0|0] "" XXX
 SG_ S_FaultMemoryEntry_Bremsbo : 46|1@1+ (1,0) [0|0] "" XXX
 SG_ S_ADDR_Relay_Opened : 45|1@1+ (1,0) [0|0] "" XXX
 SG_ S_BrakeBooster_Status : 43|2@1+ (1,0) [0|0] "" XXX
 SG_ S_Intervention_BrakeBooster : 42|1@1+ (1,0) [0|0] "" XXX
 SG_ S_Loeseschalter_Implausible : 41|1@1+ (1,0) [0|0] "" XXX
 SG_ S_BrakeIntervention_Driver : 40|1@1+ (1,0) [0|0] "" XXX
 SG_ S_Display_Sensor_blind : 39|1@1+ (1,0) [0|0] "" XXX
 SG_ S_Actuation_Optical_Fahrerh : 38|1@1+ (1,0) [0|0] "" XXX
 SG_ S_Actuation_Chime_2 : 37|1@1+ (1,0) [0|0] "" XXX
 SG_ S_Actuation_Chime_1 : 36|1@1+ (1,0) [0|0] "" XXX
 SG_ S_ShiftPrompt : 34|2@1+ (1,0) [0|0] "" XXX
 SG_ S_Display_Priority : 33|1@1+ (1,0) [0|0] "" XXX
 SG_ S_Display_TimeGap : 32|1@1+ (1,0) [0|0] "" XXX
 SG_ S_SetSpeed : 24|8@1+ (1,0) [0|254] "km/h" XXX
 SG_ S_Object_Recorded : 22|2@1+ (1,0) [0|0] "" XXX
 SG_ S_Set_TimeGap__ADDR_1_ : 18|4@1+ (1,0) [0|15] "" XXX
 SG_ S_Synchronisation_BrakeBooster : 17|1@1+ (1,0) [0|0] "" XXX
 SG_ S_TorqueRequest_Enable : 16|1@1+ (1,0) [0|0] "" XXX
 SG_ S_Prevention_OverrunFuelCut : 15|1@1+ (1,0) [0|0] "" XXX
 SG_ S_Status_ADDR_1__S_ : 13|2@1+ (1,0) [0|0] "" XXX
 SG_ S_Error_ADDR_1__S_ : 12|1@1+ (1,0) [0|0] "" XXX
 SG_ S_Counter_ADDR_1 : 8|4@1+ (1,0) [0|15] "" XXX
 SG_ S_TorqueRequest_ADDR : 0|8@1+ (0.39,0) [0|99] "MDI" XXX

BO_ 608 ADDR_2: 4 XXX
 SG_ Free_ADDR_2_2 : 27|5@1+ (1,0) [0|0] "" XXX
 SG_ Request_BrakePressure : 16|11@1+ (0.0625,0) [0|127.9375] "bar" XXX
 SG_ Free_ADDR_2_1 : 14|2@1+ (1,0) [0|0] "" XXX
 SG_ Relay_Test_Error : 13|1@1+ (1,0) [0|0] "" XXX
 SG_ Standby : 12|1@1+ (1,0) [0|0] "" XXX
 SG_ Counter_ADDR_2 : 8|4@1+ (1,0) [0|15] "" XXX
 SG_ Checksum_ADDR_2 : 0|8@1+ (1,0) [0|0] "" XXX

BO_ 1324 ADDR_1: 8 XXX
 SG_ Checksum_ADDR_1 : 56|8@1+ (1,0) [0|0] "" XXX
 SG_ Free_ADDR_1_5 : 52|4@1+ (1,0) [0|0] "" XXX
 SG_ TimeGap_Measured : 48|4@1+ (1,0) [0|15] "" XXX
 SG_ FaultMemoryEntry_ADDR : 47|1@1+ (1,0) [0|0] "" XXX
 SG_ Reserved_ADDR_1_1 : 40|7@1+ (1,0) [0|0] "" XXX
 SG_ Display_Sensor_blind : 39|1@1+ (1,0) [0|0] "" XXX
 SG_ Actuation_Optical_Fahrerhin : 38|1@1+ (1,0) [0|0] "" XXX
 SG_ Actuation_Chime_2 : 37|1@1+ (1,0) [0|0] "" XXX
 SG_ Actuation_Chime_1 : 36|1@1+ (1,0) [0|0] "" XXX
 SG_ ShiftPrompt : 34|2@1+ (1,0) [0|0] "" XXX
 SG_ Display_Priority : 33|1@1+ (1,0) [0|0] "" XXX
 SG_ Display_TimeGap : 32|1@1+ (1,0) [0|0] "" XXX
 SG_ SetSpeed : 24|8@1+ (1,0) [0|254] "km/h" XXX
 SG_ Object_Recorded : 22|2@1+ (1,0) [0|0] "" XXX
 SG_ Set_TimeGap__ADDR_1_ : 18|4@1+ (1,0) [0|15] "" XXX
 SG_ Synchronisation_BrakeBooster : 17|1@1+ (1,0) [0|0] "" XXX
 SG_ TorqueRequest_Enable : 16|1@1+ (1,0) [0|0] "" XXX
 SG_ Prevention_OverrunFuelCut : 15|1@1+ (1,0) [0|0] "" XXX
 SG_ Status_ADDR_1 : 13|2@1+ (1,0) [0|0] "" XXX
 SG_ Error_ADDR_1 : 12|1@1+ (1,0) [0|0] "" XXX
 SG_ Counter_ADDR_1 : 8|4@1+ (1,0) [0|15] "" XXX
 SG_ TorqueRequest_ADDR : 0|8@1+ (0.39,0) [0|99] "MDI" XXX

BO_ 1550 Units_1: 2 XXX
 SG_ MFA_v_Unit_02 : 0|1@1+ (1,0) [0|1] "" XXX

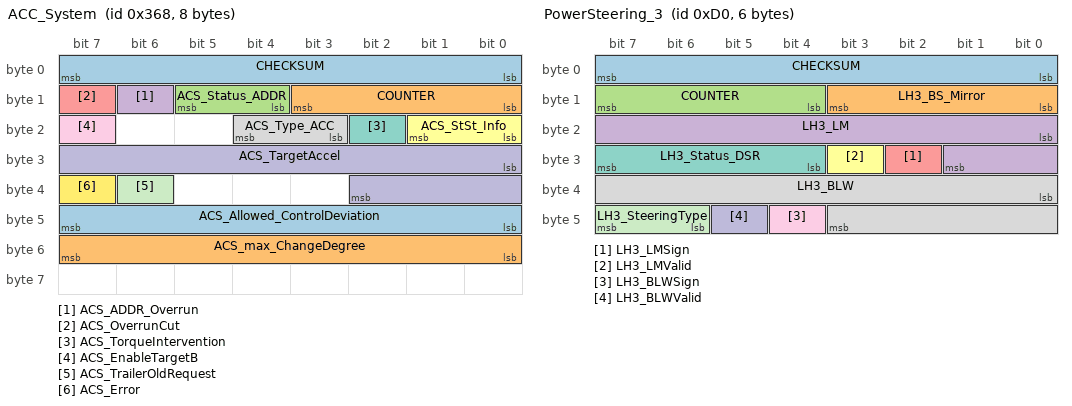
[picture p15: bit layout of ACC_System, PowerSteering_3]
BO_ 872 ACC_System: 8 XXX
 SG_ CHECKSUM : 0|8@1+ (1,0) [0|255] "" XXX
 SG_ COUNTER : 8|4@1+ (1,0) [0|15] "" XXX
 SG_ ACS_Status_ADDR : 12|2@1+ (1,0) [0|3] "" XXX
 SG_ ACS_ADDR_Overrun : 14|1@1+ (1,0) [0|1] "" XXX
 SG_ ACS_OverrunCut : 15|1@1+ (1,0) [0|1] "" XXX
 SG_ ACS_StSt_Info : 16|2@1+ (1,0) [0|3] "" XXX
 SG_ ACS_TorqueIntervention : 18|1@1+ (1,0) [0|1] "" XXX
 SG_ ACS_Type_ACC : 19|2@1+ (1,0) [0|3] "" XXX
 SG_ ACS_EnableTargetB : 23|1@1+ (1,0) [0|1] "" XXX
 SG_ ACS_TargetAccel : 24|11@1+ (0.005,-7.22) [-7.22|3.005] "Unit_MeterPerSeconSquar" XXX
 SG_ ACS_TrailerOldRequest : 38|1@1+ (1,0) [0|1] "" XXX
 SG_ ACS_Error : 39|1@1+ (1,0) [0|1] "" XXX
 SG_ ACS_Allowed_ControlDeviation : 40|8@1+ (0.005,0) [0|1.265] "Unit_MeterPerSeconSquar" XXX
 SG_ ACS_max_ChangeDegree : 48|8@1+ (0.02,0) [0.02|5.06] "Unit_MeterPerSeconSquar" XXX

BO_ 1386 ACC_GRA_Display: 8 XXX
 SG_ CHECKSUM : 0|8@1+ (1,0) [0|255] "" XXX
 SG_ ACA_StatusACC : 8|3@1+ (1,0) [0|7] "" XXX
 SG_ ACA_ID_StatusACC : 11|5@1+ (1,0) [0|31] "" XXX
 SG_ ACA_Fahrerhinw : 16|1@1+ (1,0) [0|1] "" XXX
 SG_ ACA_DispDisplay : 17|1@1+ (1,0) [0|1] "" XXX
 SG_ ACA_TimeGap : 18|4@1+ (1,0) [0|15] "" XXX
 SG_ ACA_V_Request : 24|8@1+ (1,0) [0|255] "Unit_KiloMeterPerHour" XXX
 SG_ ACA_kmh_mph : 32|1@1+ (1,0) [0|1] "" XXX
 SG_ ACA_Acoustic1 : 33|1@1+ (1,0) [0|1] "" XXX
 SG_ ACA_Acoustic2 : 34|1@1+ (1,0) [0|1] "" XXX
 SG_ ACA_PrioDisp : 35|2@1+ (1,0) [0|3] "" XXX
 SG_ ACA_gemZeitl : 40|4@1+ (1,0) [0|15] "" XXX
 SG_ ACA_ACC_Decel : 44|1@1+ (1,0) [0|1] "" XXX
 SG_ ACA_StatusGRA : 48|3@1+ (1,0) [0|7] "" XXX
 SG_ ACA_ID_StatusGRA : 51|5@1+ (1,0) [0|31] "" XXX
 SG_ ACA_Coding : 56|1@1+ (1,0) [0|1] "" XXX
 SG_ ACA_SpeedoScale : 57|1@1+ (1,0) [0|1] "" XXX
 SG_ ACA_Change_TimeGap : 58|1@1+ (1,0) [0|1] "" XXX
 SG_ COUNTER : 60|4@1+ (1,0) [0|15] "" XXX

BO_ 208 PowerSteering_3: 6 XXX
 SG_ CHECKSUM : 0|8@1+ (1,0) [0|255] "" XXX
 SG_ LH3_BS_Mirror : 8|4@1+ (1,0) [0|15] "" XXX
 SG_ COUNTER : 12|4@1+ (1,0) [0|15] "" XXX
 SG_ LH3_LM : 16|10@1+ (1,0) [0|1023] "" XXX
 SG_ LH3_LMSign : 26|1@1+ (1,0) [0|1] "" XXX
 SG_ LH3_LMValid : 27|1@1+ (1,0) [0|1] "" XXX
 SG_ LH3_Status_DSR : 28|4@1+ (1,0) [0|15] "" XXX
 SG_ LH3_BLW : 32|12@1+ (0.15,0) [0|615] "" XXX
 SG_ LH3_BLWSign : 44|1@1+ (1,0) [0|1] "" XXX
 SG_ LH3_BLWValid : 45|1@1+ (1,0) [0|1] "" XXX
 SG_ LH3_SteeringType : 46|2@1+ (1,0) [0|3] "" XXX

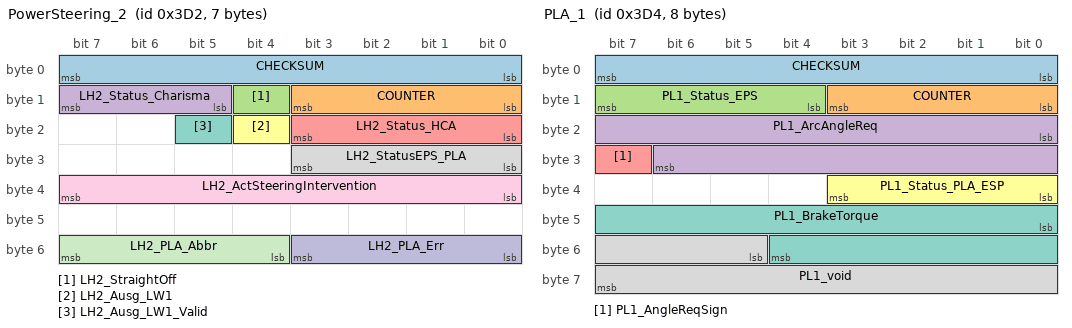
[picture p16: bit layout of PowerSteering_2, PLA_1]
BO_ 978 PowerSteering_2: 7 XXX
 SG_ CHECKSUM : 0|8@1+ (1,0) [0|255] "" XXX
 SG_ COUNTER : 8|4@1+ (1,0) [0|15] "" XXX
 SG_ LH2_StraightOff : 12|1@1+ (1,0) [0|1] "" XXX
 SG_ LH2_Status_Charisma : 13|3@1+ (1,0) [0|7] "" XXX
 SG_ LH2_Status_HCA : 16|4@1+ (1,0) [0|15] "" XXX
 SG_ LH2_Ausg_LW1 : 20|1@1+ (1,0) [0|1] "" XXX
 SG_ LH2_Ausg_LW1_Valid : 21|1@1+ (1,0) [0|1] "" XXX
 SG_ LH2_StatusEPS_PLA : 24|4@1+ (1,0) [0|15] "" XXX
 SG_ LH2_ActSteeringIntervention : 32|8@1+ (1,0) [0|255] "" XXX
 SG_ LH2_PLA_Err : 48|4@1+ (1,0) [0|15] "" XXX
 SG_ LH2_PLA_Abbr : 52|4@1+ (1,0) [0|15] "" XXX

BO_ 980 PLA_1: 8 XXX
 SG_ CHECKSUM : 0|8@1+ (1,0) [0|255] "" XXX
 SG_ COUNTER : 8|4@1+ (1,0) [0|15] "" XXX
 SG_ PL1_Status_EPS : 12|4@1+ (1,0) [0|15] "" XXX
 SG_ PL1_ArcAngleReq : 16|15@1+ (0.04375,0) [0|1433.55625] "Unit_DegreeOfArc" XXX
 SG_ PL1_AngleReqSign : 31|1@1+ (1,0) [0|1] "" XXX
 SG_ PL1_Status_PLA_ESP : 32|4@1+ (1,0) [0|10] "" Vector__XXX
 SG_ PL1_BrakeTorque : 40|13@1+ (4,0) [0|32760] "Unit_NewtoMeter" Vector__XXX
 SG_ PL1_void : 53|11@1+ (1,0) [0|2047] "" XXX

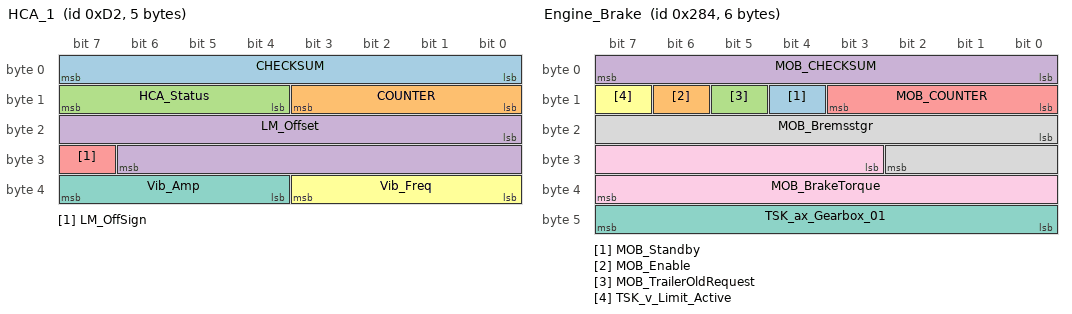
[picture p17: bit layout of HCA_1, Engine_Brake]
BO_ 210 HCA_1: 5 XXX
 SG_ CHECKSUM : 0|8@1+ (1,0) [0|15] "" XXX
 SG_ COUNTER : 8|4@1+ (1,0) [0|15] "" XXX
 SG_ HCA_Status : 12|4@1+ (1,0) [0|15] "" XXX
 SG_ LM_Offset : 16|15@1+ (0.03125,0) [0|300] "cNm" XXX
 SG_ LM_OffSign : 31|1@1+ (1,0) [0|1] "" XXX
 SG_ Vib_Freq : 32|4@1+ (4,0) [0|60] "Hz" XXX
 SG_ Vib_Amp : 36|4@1+ (0.5,0) [0|7.5] "Nm" XXX

BO_ 644 Engine_Brake: 6 XXX
 SG_ MOB_Standby : 12|1@1+ (1,0) [0|1] ""  XXX
 SG_ MOB_Enable : 14|1@1+ (1,0) [0|1] "" BCM_Gateway,Bremse_MK25AESP,Gateway_separat
 SG_ MOB_TrailerOldRequest : 13|1@1+ (1,0) [0|1] "" Bremse_MK25AESP,Getriebe_DQ
 SG_ MOB_CHECKSUM : 0|8@1+ (1,0) [0|255] "" Bremse_MK25AESP
 SG_ MOB_COUNTER : 8|4@1+ (1,0) [0|15] "" Bremse_MK25AESP
 SG_ TSK_v_Limit_Active : 15|1@0+ (1,0) [0|1] "" XXX
 SG_ TSK_ax_Gearbox_01 : 40|8@1+ (0.048,0) [0|255] "m/s2" XXX
 SG_ MOB_Bremsstgr : 16|11@1+ (0.048852,0) [0|100] "Unit_PerCent" Vector__XXX
 SG_ MOB_BrakeTorque : 27|13@1+ (4,0) [0|32760] "Unit_NewtoMeter"  Bremse_MK25AESP

BO_ 870 AWV: 8 XXX
 SG_ CHECKSUM : 0|8@1+ (1,0) [0|255] "" Vector__XXX
 SG_ COUNTER : 8|4@1+ (1,0) [0|15] "" Vector__XXX
 SG_ AWV_Text : 12|4@1+ (1,0) [0|14] "" Vector__XXX
 SG_ AWV_1_Enable : 16|1@1+ (1,0) [0|1] "" Vector__XXX
 SG_ AWV_1_Prefill : 17|1@1+ (1,0) [0|1] "" Vector__XXX
 SG_ AWV_1_Parameter : 18|2@1+ (1,0) [0|3] "" Vector__XXX
 SG_ AWV_only : 20|1@1+ (1,0) [0|1] "" Vector__XXX
 SG_ AWV_CityANB_Variant : 21|1@1+ (1,0) [0|1] "" Vector__XXX
 SG_ AWV_Hold : 22|1@1+ (1,0) [0|1] "" Vector__XXX
 SG_ ANB_PartialBraking_Enable : 23|1@1+ (1,0) [0|1] "" Vector__XXX
 SG_ AWV_2_Status : 24|1@1+ (1,0) [0|1] "" Vector__XXX
 SG_ AWV_2_Error : 25|1@1+ (1,0) [0|1] "" Vector__XXX
 SG_ AWV_2_SU_WarnTime : 26|2@1+ (1,0) [0|3] "" Vector__XXX
 SG_ AWV_2_SU_BrakeJerk : 28|1@1+ (1,0) [0|1] "" Vector__XXX
 SG_ AWV_2_SU_Chime : 29|1@1+ (1,0) [0|1] "" Vector__XXX
 SG_ AWV_2_SU_Lamp : 30|1@1+ (1,0) [0|1] "" Vector__XXX
 SG_ AWV_2_Umfeldwarn : 31|1@1+ (1,0) [0|1] "" Vector__XXX
 SG_ AWV_2_Enable : 32|1@1+ (1,0) [0|1] "" Vector__XXX
 SG_ AWV_2_JerkProfile : 33|3@1+ (1,0) [0|7] "" Vector__XXX
 SG_ AWV_2_WarningTone : 36|1@1+ (1,0) [0|1] "" Vector__XXX
 SG_ AWV_2_Warnsymbol : 37|1@1+ (1,0) [0|1] "" Vector__XXX
 SG_ AWV_InfoTone : 38|1@1+ (1,0) [0|1] "" Vector__XXX
 SG_ AWV_2_BeltTensioner : 39|1@1+ (1,0) [0|1] "" Vector__XXX
 SG_ AWV_Configuration_MenuReq : 40|1@1+ (1,0) [0|1] "" Vector__XXX
 SG_ AWV_Configuration_Vorw_MenuReq : 41|1@1+ (1,0) [0|1] "" Vector__XXX
 SG_ AWV_Configuration_Status : 42|1@1+ (1,0) [0|1] "" Vector__XXX
 SG_ AWV_Configuration_Vorw_Status : 43|1@1+ (1,0) [0|1] "" Vector__XXX
 SG_ AWV_2_DistanceWarning : 51|1@1+ (1,0) [0|1] "" Vector__XXX
 SG_ ANB_TargetBraking_Enable : 52|1@1+ (1,0) [0|1] "" Vector__XXX
 SG_ ANB_CM_Request : 53|1@1+ (1,0) [0|1] "" Vector__XXX
 SG_ ANB_Target_Teilbrems_Decel_Req : 54|10@1+ (0.024,-20.016) [0|1023] "Unit_MeterPerSeconSquar" Vector__XXX

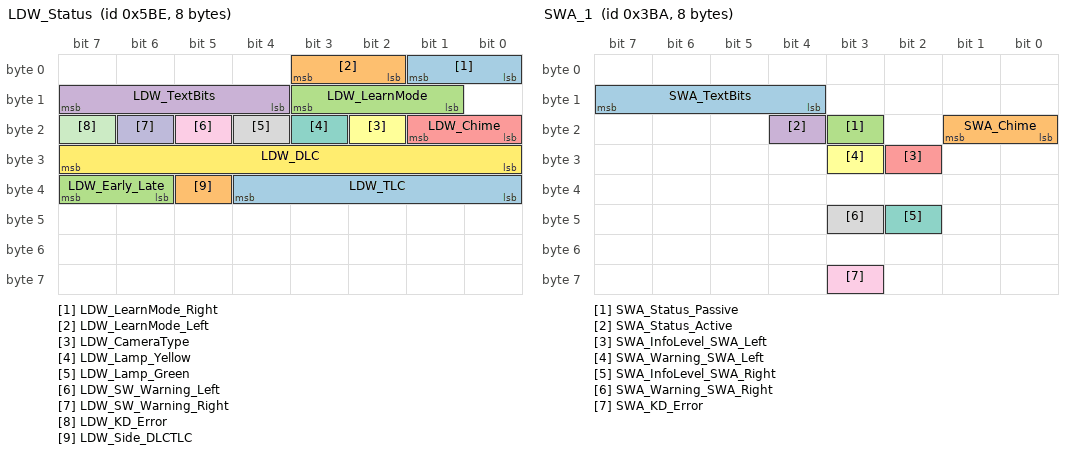
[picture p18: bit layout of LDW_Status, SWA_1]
BO_ 1470 LDW_Status: 8 XXX
 SG_ LDW_LearnMode_Right : 0|2@1+ (1,0) [0|3] "" XXX
 SG_ LDW_LearnMode_Left : 2|2@1+ (1,0) [0|3] "" XXX
 SG_ LDW_LearnMode : 9|3@1+ (1,0) [0|3] "" XXX
 SG_ LDW_TextBits : 12|4@1+ (1,0) [0|15] "" XXX
 SG_ LDW_Chime : 16|2@1+ (1,0) [0|3] "" XXX
 SG_ LDW_CameraType : 18|1@1+ (1,0) [0|1] "" XXX
 SG_ LDW_Lamp_Yellow : 19|1@1+ (1,0) [0|1] "" XXX
 SG_ LDW_Lamp_Green : 20|1@1+ (1,0) [0|1] "" XXX
 SG_ LDW_SW_Warning_Left : 21|1@1+ (1,0) [0|1] "" XXX
 SG_ LDW_SW_Warning_Right : 22|1@1+ (1,0) [0|1] "" XXX
 SG_ LDW_KD_Error : 23|1@1+ (1,0) [0|1] "" XXX
 SG_ LDW_DLC : 24|8@1+ (0.01,-1.25) [-1.25|1.25] "" XXX
 SG_ LDW_TLC : 32|5@1+ (0.1,0) [0|3] "" XXX
 SG_ LDW_Side_DLCTLC : 37|1@1+ (1,0) [0|1] "" XXX
 SG_ LDW_Early_Late : 38|2@1+ (1,0) [0|3] "" XXX

BO_ 428 Brake_8: 8 XXX
 SG_ BR8_Checksum : 0|8@1+ (1,0) [0|255] "" XXX
 SG_ BR8_Counter : 8|4@1+ (1,0) [0|15] "" XXX
 SG_ BR8_Status_ACC_Req : 12|1@1+ (1,0) [0|1] "" XXX
 SG_ BR8_Decel_EPB_Act : 13|1@1+ (1,0) [0|1] "" XXX
 SG_ BR8_Status_Br_temp : 14|1@1+ (1,0) [0|1] "" XXX
 SG_ BR8_Status_Br_Pressure : 15|1@1+ (1,0) [0|1] "" XXX
 SG_ BR8_TolAlign_HL : 16|8@1+ (0.048828125,-6.201171875) [-6.201171875|6.15234375] "Unit_PerCent" XXX
 SG_ BR8_TolAlign_HR : 24|8@1+ (0.048828125,-6.201171875) [-6.201171875|6.15234375] "Unit_PerCent" XXX
 SG_ BR8_ActualAccel : 32|9@1+ (0.02,-7.22) [-7.22|2.98] "Unit_MeterPerSeconSquar"  XXX
 SG_ BR8_Status_HW_BLS : 41|1@1+ (1,0) [0|1] "" XXX
 SG_ BR8_QB_LAccel : 42|1@1+ (1,0) [0|1] "" XXX
 SG_ BR8_ESC_Mode : 43|2@1+ (1,0) [0|3] "" XXX
 SG_ BR8_ActBrSyst : 45|1@1+ (1,0) [0|1] "" XXX
 SG_ BR8_Fa_Brakes : 46|1@1+ (1,0) [0|1] "" XXX
 SG_ BR8_StatusBrSyst : 47|1@1+ (1,0) [0|1] "" XXX
 SG_ BR8_LongAccel : 48|10@1+ (0.03125,-16) [-15.96875|15.9375] "Unit_MeterPerSeconSquar" XXX
 SG_ BR8_Status_ADDR_BR : 58|1@1+ (1,0) [0|1] "" XXX
 SG_ BR8_Quattro : 59|1@1+ (1,0) [0|1] "" XXX
 SG_ BR8_Status_DecelReg : 60|1@1+ (1,0) [0|1] "" XXX
 SG_ BR8_Status_BLS : 61|1@1+ (1,0) [0|1] "" XXX
 SG_ BR8_Decel_EPB : 62|1@1+ (1,0) [0|1] "" XXX
 SG_ BR8_Check_EPB : 63|1@1+ (1,0) [0|1] "" XXX

BO_ 928 Brake_10: 8 XXX
 SG_ B10_Checksum : 0|8@1+ (1,0) [0|255] "" XXX
 SG_ B10_Counter : 8|4@1+ (1,0) [0|15] "" XXX
 SG_ B10_QB_DistPulse_VL : 12|1@1+ (1,0) [0|1] "" XXX
 SG_ B10_QB_DistPulse_VR : 13|1@1+ (1,0) [0|1] "" XXX
 SG_ B10_QB_DistPulse_HL : 14|1@1+ (1,0) [0|1] "" XXX
 SG_ B10_QB_DistPulse_HR : 15|1@1+ (1,0) [0|1] "" XXX
 SG_ B10_DistPulse_VL : 16|10@1+ (1,0) [0|1000] "" XXX
 SG_ B10_DistPulse_VR : 26|10@1+ (1,0) [0|1000] "" XXX
 SG_ B10_DistPulse_HL : 36|10@1+ (1,0) [0|1000] "" XXX
 SG_ B10_DistPulse_HR : 46|10@1+ (1,0) [0|1000] "" XXX
 SG_ B10_QB_Direction_VL : 56|1@1+ (1,0) [0|1] "" XXX
 SG_ B10_QB_Direction_VR : 57|1@1+ (1,0) [0|1] "" XXX
 SG_ B10_QB_Direction_HL : 58|1@1+ (1,0) [0|1] "" XXX
 SG_ B10_QB_Direction_HR : 59|1@1+ (1,0) [0|1] "" XXX
 SG_ B10_Direction_VL : 60|1@1+ (1,0) [0|1] "" XXX
 SG_ B10_Direction_VR : 61|1@1+ (1,0) [0|1] "" XXX
 SG_ B10_Direction_HL : 62|1@1+ (1,0) [0|1] "" XXX
 SG_ B10_Direction_HR : 63|1@1+ (1,0) [0|1] "" XXX

BO_ 835 RDK_Status: 3 XXX
 SG_ RKS_Tyre_VL : 0|1@1+ (1,0) [0|1] "" XXX
 SG_ RKS_Tyre_VR : 1|1@1+ (1,0) [0|1] "" XXX
 SG_ RKS_Tyre_HL : 2|1@1+ (1,0) [0|1] "" XXX
 SG_ RKS_Tyre_HR : 3|1@1+ (1,0) [0|1] "" XXX
 SG_ RKS_Tyre_RR : 4|1@1+ (1,0) [0|1] "" XXX
 SG_ RKS_Warning_2 : 5|1@1+ (1,0) [0|1] "" XXX
 SG_ RKS_Warning_1 : 6|1@1+ (1,0) [0|1] "" XXX
 SG_ RKS_SystemError : 7|1@1+ (1,0) [0|1] "" XXX
 SG_ RKS_Kalibrier_abgew : 8|1@1+ (1,0) [0|1] "" XXX
 SG_ RKS_PressureDiff_Front : 9|1@1+ (1,0) [0|1] "" XXX
 SG_ RKS_PressureDiff_Rear : 10|1@1+ (1,0) [0|1] "" XXX
 SG_ RKS_Befuellung_RR_low : 11|1@1+ (1,0) [0|1] "" XXX
 SG_ RKS_RadioMalfunction : 12|1@1+ (1,0) [0|1] "" XXX
 SG_ RKS_System_Off : 13|1@1+ (1,0) [0|1] "" XXX
 SG_ RKS_KD_Error : 15|1@1+ (1,0) [0|1] "" XXX
 SG_ RKS_Lamp : 16|1@1+ (1,0) [0|1] "" XXX
 SG_ RKS_Tone : 17|1@1+ (1,0) [0|1] "" XXX
 SG_ RKS_Chime : 18|1@1+ (1,0) [0|1] "" XXX
 SG_ RKS_RDK_Blinkbit : 19|1@1+ (1,0) [0|1] "" XXX
 SG_ RKS_PartLoad : 20|1@1+ (1,0) [0|1] "" XXX

BO_ 914 Gate_Comfort_2: 8 XXX
 SG_ GK2_Status_LSM : 0|1@1+ (1,0) [0|1] "" XXX
 SG_ GK2_Status_Lichtsensor : 1|1@1+ (1,0) [0|1] "" XXX
 SG_ GK2_Status_Light1 : 2|1@1+ (1,0) [0|1] "" XXX
 SG_ GK2_Status_VSG : 3|1@1+ (1,0) [0|1] "" XXX
 SG_ GK2_Status_Key : 4|1@1+ (1,0) [0|1] "" XXX
 SG_ GK2_Status_Profile : 5|1@1+ (1,0) [0|1] "" XXX
 SG_ GK2_Status_Clima2 : 6|1@1+ (1,0) [0|1] "" XXX
 SG_ GK2_Status_BodyECU4 : 7|1@1+ (1,0) [0|1] "" XXX
 SG_ GK2_Status_Kessy_4 : 8|1@1+ (1,0) [0|1] "" XXX
 SG_ BS4_Sliding_Leuchtw_Req : 9|1@1+ (1,0) [0|1] "" XXX
 SG_ BS4_GLW_HighBeam_Req : 10|1@1+ (1,0) [0|1] "" XXX
 SG_ GK2_Blk_L_Check : 11|1@1+ (1,0) [0|1] "" XXX
 SG_ GK2_Blk_R_Check : 12|1@1+ (1,0) [0|1] "" XXX
 SG_ GK2_LS_CommError : 14|1@1+ (1,0) [0|1] "" XXX
 SG_ GK2_LS_def : 15|1@1+ (1,0) [0|1] "" XXX
 SG_ GK2_Brightness : 16|3@1+ (714.286,0) [0|5000.002] "Unit_Lux" XXX
 SG_ GK2_VD_Closed_ver : 19|1@1+ (1,0) [0|1] "" XXX
 SG_ GK2_VD_Unlocked : 20|1@1+ (1,0) [0|1] "" XXX
 SG_ GK2_VD_Open_ver : 21|1@1+ (1,0) [0|1] "" XXX
 SG_ GK2_Roof_Req : 22|1@1+ (1,0) [0|1] "" XXX
 SG_ GK2_VDKD_Open : 23|1@1+ (1,0) [0|1] "" XXX
 SG_ GK2_Key : 24|4@1+ (1,0) [0|15] "" XXX
 SG_ GK2_Hardtop : 28|1@1+ (1,0) [0|1] "" XXX
 SG_ GK2_AFL_Switch : 29|1@1+ (1,0) [0|1] "" XXX
 SG_ GK2_RearFog : 30|1@1+ (1,0) [0|1] "" XXX
 SG_ GK2_EM_LIN_Invalid : 31|1@1+ (1,0) [0|1] "" XXX
 SG_ GK2_Profile : 32|4@1+ (1,0) [0|15] "" XXX
 SG_ GK2_Term_StSt_Info : 36|2@1+ (1,0) [0|3] "" XXX
 SG_ GK2_BodyECU_StSt_Info : 38|2@1+ (1,0) [0|3] "" XXX
 SG_ GK2_BEM_P_Alternator : 40|8@1+ (50,0) [0|12700] "Unit_Watt" XXX
 SG_ GK2_BEM_ShutoffStages : 48|3@1+ (1,0) [0|7] "" XXX
 SG_ GK2_BEM_DFM : 51|5@1+ (3.225,0.025) [0.025|100] "Unit_PerCent" XXX
 SG_ GK2_Kessy_StSt_Info : 56|2@1+ (1,0) [0|3] "" XXX
 SG_ GK2_BEM_StSt_Info : 58|2@1+ (1,0) [0|3] "" XXX

BO_ 954 SWA_1: 8 SWA
 SG_ SWA_TextBits : 12|4@1+ (1,0) [0|15] ""  XXX
 SG_ SWA_Chime : 16|2@1+ (1,0) [0|3] ""  XXX
 SG_ SWA_Status_Passive : 19|1@1+ (1,0) [0|1] ""  XXX
 SG_ SWA_Status_Active : 20|1@1+ (1,0) [0|1] ""  XXX
 SG_ SWA_InfoLevel_SWA_Left : 26|1@1+ (1,0) [0|1] ""  XXX
 SG_ SWA_Warning_SWA_Left : 27|1@1+ (1,0) [0|1] ""  XXX
 SG_ SWA_InfoLevel_SWA_Right : 42|1@1+ (1,0) [0|1] ""  XXX
 SG_ SWA_Warning_SWA_Right : 43|1@1+ (1,0) [0|1] ""  XXX
 SG_ SWA_KD_Error : 59|1@1+ (1,0) [0|1] ""  XXX

BO_ 1175 ParkAssist_01: 8 XXX
 SG_ PH_ShutoffCause : 13|3@1+ (1,0) [0|7] "" XXX
 SG_ PH_Opt_Display_V_On : 16|1@1+ (1,0) [0|1] "" XXX
 SG_ PH_Opt_Display_H_On : 17|1@1+ (1,0) [0|1] "" XXX
 SG_ PH_Opt_Disp_V_Obstacle : 18|1@1+ (1,0) [0|1] "" XXX
 SG_ PH_Opt_Disp_H_Obstacle : 19|1@1+ (1,0) [0|1] "" XXX
 SG_ PH_ToneSender_V_Active : 20|1@1+ (1,0) [0|1] "" XXX
 SG_ PH_ToneSender_H_Active : 21|1@1+ (1,0) [0|1] "" XXX
 SG_ PH_ToneSender_Mute : 22|1@1+ (1,0) [0|1] "" XXX
 SG_ PH_Req_AudioDucking : 23|1@1+ (1,0) [0|1] "" XXX
 SG_ PH_Frequency_Rear : 32|4@1+ (1,0) [0|15] "" XXX
 SG_ PH_Volume_Rear : 36|4@1+ (1,0) [0|15] "" XXX
 SG_ PH_Frequency_Front : 40|4@1+ (1,0) [0|15] "" XXX
 SG_ PH_Volume_Front : 44|4@1+ (1,0) [0|15] "" XXX
 SG_ PH_Trigger_ImageOpenShift : 48|1@1+ (1,0) [0|1] "" XXX
 SG_ PH_StartStop_Info : 49|2@1+ (1,0) [0|3] "" XXX
 SG_ PH_Aufbauten_Det : 51|1@1+ (1,0) [0|1] "" XXX
 SG_ PH_RangeDet_Front : 52|2@1+ (1,0) [0|3] "" XXX
 SG_ PH_RangeDet_Rear : 54|2@1+ (1,0) [0|3] "" XXX
 SG_ PH_Defective : 56|1@1+ (1,0) [0|1] "" XXX
 SG_ PH_Disturbed : 57|1@1+ (1,0) [0|1] "" XXX
 SG_ PH_Systemzustand : 58|3@1+ (1,0) [0|7] "" XXX
 SG_ PH_Display_Kundenwunsch : 61|2@1+ (1,0) [0|3] "" XXX
 SG_ PH_KD_Error : 63|1@1+ (1,0) [0|1] "" XXX

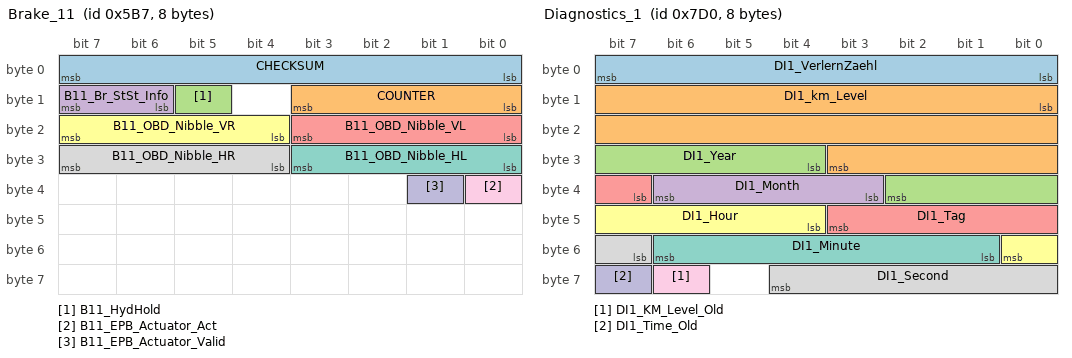
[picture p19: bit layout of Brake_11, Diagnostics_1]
BO_ 1463 Brake_11: 8 XXX
 SG_ CHECKSUM : 0|8@1+ (1,0) [0|255] "" XXX
 SG_ COUNTER : 8|4@1+ (1,0) [0|15] "" XXX
 SG_ B11_HydHold : 13|1@1+ (1,0) [0|1] "" XXX
 SG_ B11_Br_StSt_Info : 14|2@1+ (1,0) [0|3] "" XXX
 SG_ B11_OBD_Nibble_VL : 16|4@1+ (1,0) [0|15] "" XXX
 SG_ B11_OBD_Nibble_VR : 20|4@1+ (1,0) [0|15] "" XXX
 SG_ B11_OBD_Nibble_HL : 24|4@1+ (1,0) [0|15] "" XXX
 SG_ B11_OBD_Nibble_HR : 28|4@1+ (1,0) [0|15] "" XXX
 SG_ B11_EPB_Actuator_Act : 32|1@1+ (1,0) [0|1] "" XXX
 SG_ B11_EPB_Actuator_Valid : 33|1@1+ (1,0) [0|1] "" XXX

BO_ 1500 Target_FitmentList_New: 8 XXX
 SG_ VL1_Engine_ECU : 0|1@1+ (1,0) [0|1] "" XXX
 SG_ VL1_Gearbox_ECU : 1|1@1+ (1,0) [0|1] "" XXX
 SG_ VL1_ABS : 2|1@1+ (1,0) [0|1] "" XXX
 SG_ VL1_Cluster : 3|1@1+ (1,0) [0|1] "" XXX
 SG_ VL1_LSM : 4|1@1+ (1,0) [0|1] "" XXX
 SG_ VL1_Airbag : 5|1@1+ (1,0) [0|1] "" XXX
 SG_ VL1_PowerSteering : 6|1@1+ (1,0) [0|1] "" XXX
 SG_ VL1_Dyn_LWR : 7|1@1+ (1,0) [0|1] "" XXX
 SG_ VL1_res_08 : 8|1@1+ (1,0) [0|1] "" XXX
 SG_ VL1_AllWheelDrive : 9|1@1+ (1,0) [0|1] "" XXX
 SG_ VL1_ADDR : 10|1@1+ (1,0) [0|1] "" XXX
 SG_ VL1_ADDR_Disconnected : 11|1@1+ (1,0) [0|1] "" XXX
 SG_ VL1_EPB : 12|1@1+ (1,0) [0|1] "" XXX
 SG_ VL1_res_13 : 13|1@1+ (1,0) [0|1] "" XXX
 SG_ VL1_Damper : 14|1@1+ (1,0) [0|1] "" XXX
 SG_ VL1_Quersperre : 15|1@1+ (1,0) [0|1] "" XXX
 SG_ VL1_EngineSlave : 16|1@1+ (1,0) [0|1] "" XXX
 SG_ VL1_SWA : 17|1@1+ (1,0) [0|1] "" XXX
 SG_ VL1_HCA : 18|1@1+ (1,0) [0|1] "" XXX
 SG_ VL1_RKA_Plus : 19|1@1+ (1,0) [0|1] "" XXX
 SG_ VL1_PLA : 20|1@1+ (1,0) [0|1] "" XXX
 SG_ VL1_WFS_KBI : 21|1@1+ (1,0) [0|1] "" XXX
 SG_ VL1_Cluster_KBI : 22|1@1+ (1,0) [0|1] "" XXX
 SG_ VL1_Target_eq_Actual : 23|1@1+ (1,0) [0|1] "" XXX
 SG_ VL1_BodyECU_Comfort : 24|1@1+ (1,0) [0|1] "" XXX
 SG_ VL1_ZKE : 25|1@1+ (1,0) [0|1] "" XXX
 SG_ VL1_DoorECU_FT : 26|1@1+ (1,0) [0|1] "" XXX
 SG_ VL1_DoorECU_BT : 27|1@1+ (1,0) [0|1] "" XXX
 SG_ VL1_DoorECU_HL : 28|1@1+ (1,0) [0|1] "" XXX
 SG_ VL1_DoorECU_HR : 29|1@1+ (1,0) [0|1] "" XXX
 SG_ VL1_Memory : 30|1@1+ (1,0) [0|1] "" XXX
 SG_ VL1_RoofModule_K : 31|1@1+ (1,0) [0|1] "" XXX
 SG_ VL1_CentralElectrics_II : 32|1@1+ (1,0) [0|1] "" XXX
 SG_ VL1_RDK : 33|1@1+ (1,0) [0|1] "" XXX
 SG_ VL1_SteeringColumn : 34|1@1+ (1,0) [0|1] "" XXX
 SG_ VL1_Gateway : 35|1@1+ (1,0) [0|1] "" XXX
 SG_ VL1_Clima_Comfort : 36|1@1+ (1,0) [0|1] "" XXX
 SG_ VL1_ParkAssist : 37|1@1+ (1,0) [0|1] "" XXX
 SG_ VL1_PTC_Heating : 38|1@1+ (1,0) [0|1] "" XXX
 SG_ VL1_LevelHeat : 39|1@1+ (1,0) [0|1] "" XXX
 SG_ VL1_Roof : 40|1@1+ (1,0) [0|1] "" XXX
 SG_ VL1_RSE_I : 41|1@1+ (1,0) [0|1] "" XXX
 SG_ VL1_res_42 : 42|1@1+ (1,0) [0|1] "" XXX
 SG_ VL1_MDI_I : 43|1@1+ (1,0) [0|1] "" XXX
 SG_ VL1_Trailer : 44|1@1+ (1,0) [0|1] ""  SWA
 SG_ VL1_Memory_BF : 45|1@1+ (1,0) [0|1] "" XXX
 SG_ VL1_Easy_Entry_VF : 46|1@1+ (1,0) [0|1] "" XXX
 SG_ VL1_Easy_Entry_VB : 47|1@1+ (1,0) [0|1] "" XXX
 SG_ VL1_Tailgate : 48|1@1+ (1,0) [0|1] "" XXX
 SG_ VL1_Rearview : 49|1@1+ (1,0) [0|1] "" XXX
 SG_ VL1_Sonderfzg_ECU : 50|1@1+ (1,0) [0|1] "" XXX
 SG_ VL1_KeysModule : 51|1@1+ (1,0) [0|1] "" XXX
 SG_ VL1_Kompass : 52|1@1+ (1,0) [0|1] "" XXX
 SG_ VL1_WFS_K : 53|1@1+ (1,0) [0|1] "" XXX
 SG_ VL1_GSM_Pager : 54|1@1+ (1,0) [0|1] "" XXX
 SG_ VL1_InfoElektronik : 55|1@1+ (1,0) [0|1] "" XXX
 SG_ VL1_DSP : 56|1@1+ (1,0) [0|1] "" XXX
 SG_ VL1_DAB : 57|1@1+ (1,0) [0|1] "" XXX
 SG_ VL1_Telematics : 58|1@1+ (1,0) [0|1] "" XXX
 SG_ VL1_Navigation : 59|1@1+ (1,0) [0|1] "" XXX
 SG_ VL1_TV_Tuner : 60|1@1+ (1,0) [0|1] "" XXX
 SG_ VL1_InclinationModule_I : 61|1@1+ (1,0) [0|1] "" XXX
 SG_ VL1_Radio : 62|1@1+ (1,0) [0|1] "" XXX
 SG_ VL1_Phone : 63|1@1+ (1,0) [0|1] "" XXX

BO_ 1490 Ident: 8 XXX
 SG_ IDT_Mux M : 0|2@1+ (1,0) [0|2] "" XXX
 SG_ IDT_Secret_1 m0 : 8|8@1+ (1,0) [0|255] "" XXX
 SG_ IDT_VIN_4 m1 : 8|8@1+ (1,0) [0|255] "" XXX
 SG_ IDT_VIN_11 m2 : 8|8@1+ (1,0) [0|255] "" XXX
 SG_ IDT_Secret_2 m0 : 16|8@1+ (1,0) [0|255] "" XXX
 SG_ IDT_VIN_5 m1 : 16|8@1+ (1,0) [0|255] "" XXX
 SG_ IDT_VIN_12 m2 : 16|8@1+ (1,0) [0|255] "" XXX
 SG_ IDT_Secret_3 m0 : 24|8@1+ (1,0) [0|255] "" XXX
 SG_ IDT_VIN_6 m1 : 24|8@1+ (1,0) [0|255] "" XXX
 SG_ IDT_VIN_13 m2 : 24|8@1+ (1,0) [0|255] "" XXX
 SG_ IDT_Secret_4 m0 : 32|8@1+ (1,0) [0|255] "" XXX
 SG_ IDT_VIN_7 m1 : 32|8@1+ (1,0) [0|255] "" XXX
 SG_ IDT_VIN_14 m2 : 32|8@1+ (1,0) [0|255] "" XXX
 SG_ IDT_VIN_1 m0 : 40|8@1+ (1,0) [0|255] "" XXX
 SG_ IDT_VIN_8 m1 : 40|8@1+ (1,0) [0|255] "" XXX
 SG_ IDT_VIN_15 m2 : 40|8@1+ (1,0) [0|255] "" XXX
 SG_ IDT_VIN_2 m0 : 48|8@1+ (1,0) [0|255] "" XXX
 SG_ IDT_VIN_9 m1 : 48|8@1+ (1,0) [0|255] "" XXX
 SG_ IDT_VIN_16 m2 : 48|8@1+ (1,0) [0|255] "" XXX
 SG_ IDT_VIN_3 m0 : 56|8@1+ (1,0) [0|255] "" XXX
 SG_ IDT_VIN_10 m1 : 56|8@1+ (1,0) [0|255] "" XXX
 SG_ IDT_VIN_17 m2 : 56|8@1+ (1,0) [0|255] "" XXX

BO_ 2000 Diagnostics_1: 8 XXX
 SG_ DI1_VerlernZaehl : 0|8@1+ (1,0) [0|254] "" XXX
 SG_ DI1_km_Level : 8|20@1+ (1,0) [0|1048575] "Unit_KiloMeter" XXX
 SG_ DI1_Year : 28|7@1+ (1,2000) [2000|2127] "Unit_Year" XXX
 SG_ DI1_Month : 35|4@1+ (1,0) [1|12] "Unit_Month" XXX
 SG_ DI1_Tag : 39|5@1+ (1,0) [0|31] "Unit_Day" XXX
 SG_ DI1_Hour : 44|5@1+ (1,0) [0|23] "Unit_Hours" XXX
 SG_ DI1_Minute : 49|6@1+ (1,0) [0|59] "Unit_Minut" XXX
 SG_ DI1_Second : 55|6@1+ (1,0) [0|59] "Unit_Secon" XXX
 SG_ DI1_KM_Level_Old : 62|1@1+ (1,0) [0|1] "" XXX
 SG_ DI1_Time_Old : 63|1@1+ (1,0) [0|1] "" XXX

CM_ SG_ 80 Checksumme_Airbag_1 "Checksum Airbag_1";
CM_ SG_ 80 Zaehler_Airbag_1 "Counter Airbag_1";

CM_ BO_ 194 "Steering wheel angle message 1 - Contains steering angle, speed, and status information [DE: Lenkwinkel_1]";

CM_ SG_ 194 LW1_LRW "Steering wheel angle (0 = straight ahead, 7FFFh = stop)";
CM_ SG_ 194 LW1_LRW_Sign "Steering angle sign: 0=positive (left), 1=negative (right)";
CM_ SG_ 194 LW1_Steer_Speed "Steering wheel angular velocity (0 = no movement, 7FFFh = max speed) [DE: LW1_Lenk_Gesch]";
CM_ SG_ 194 LW1_Speed_Sign "Angular velocity sign: 0=positive, 1=negative [DE: LW1_Gesch_Sign]";
CM_ SG_ 194 LW1_ID "Calibration ID - 0=not calibrated, 128=calibrated (PQ35/46/VW32x/VW411)";
CM_ SG_ 194 LW1_InitSource "Initialization source [DE: LW1_Initquelle]";
CM_ SG_ 194 LW1_Status "Sensor status";
CM_ SG_ 194 LW1_Status_TERM30 "Terminal 30 status (Kostal sensor) [DE: LW1_Sta_KL30]";
CM_ SG_ 194 LW1_Counter "Free running message counter [DE: LW1_Zaehler]";
CM_ SG_ 194 LW1_Coding "Coding data (multiplex output depends on counter) [DE: LW1_Kodier]";
CM_ SG_ 194 LW1_CRC "Checksum - One's complement of 8-bit sum of bytes 1,2,3,4,6";

CM_ SG_ 210 LM_Offset "centiNewton-meters for ease of calculation without FP math in Panda";
CM_ SG_ 210 Vib_Amp "Steering wheel haptic, amplitude";
CM_ SG_ 210 Vib_Freq "Steering wheel haptic, frequency";

CM_ SG_ 416 BR1_ASR_Req "ASR request to engine - requests in bytes 5 and 6 to be executed [DE: BR1_ASR_Anf]";
CM_ SG_ 416 BR1_MSR_Req "MSR request - when set, byte 6 contains inverse MSR torque [DE: BR1_MSR_Anf]";
CM_ SG_ 416 BR1_ABS_Brake "ABS control active (including pressure reduction) [DE: BR1_ABS_Brems]";
CM_ SG_ 416 BR1_EDS_OnGround "Electronic differential lock intervention [DE: BR1_EDS_Ongr]";
CM_ SG_ 416 BR1_ESP_OnGround "ESP driving dynamics control intervention [DE: BR1_ESP_Ongr]";
CM_ SG_ 416 BR1_ASR_OnGround "ASR transmission switching influence [DE: BR1_ASR_Ongr]";
CM_ SG_ 416 BR1_EBV_OnGround "Electronic brake force distribution intervention [DE: BR1_EBV_Ongr]";
CM_ SG_ 416 BR1_Lamp_ABS "ABS safety warning lamp [DE: BR1_Lampe_ABS]";
CM_ SG_ 416 BR1_Lamp_ASR "ASR/ESP lamp (including flashing info) [DE: BR1_Lampe_ASR]";
CM_ SG_ 416 BR1_Lamp_BK "Brake control lamp (red) [DE: BR1_Lampe_BK]";
CM_ SG_ 416 BR1_LightShift "Brake light switch / brake pressure threshold exceeded [DE: BR1_Lichtschalt]";
CM_ SG_ 416 BR1_StatusPressureThreshold "Brake test switch / pressure threshold status [DE: BR1_StaDruckschw]";
CM_ SG_ 416 BR1_MAD "OBD rough road suppression";
CM_ SG_ 416 BR1_Status_MAD "Rough road suppression status [DE: BR1_Sta_MAD]";
CM_ SG_ 416 BR1_Diagnostics "ABS diagnosis mode active [DE: BR1_Diagnose]";
CM_ SG_ 416 BR1_BKV_active "Active brake booster installed and not faulty";
CM_ SG_ 416 BR1_Wheel_kmh "Vehicle speed (mean of driven wheels or ABS reference) [DE: BR1_Rad_kmh]";
CM_ SG_ 416 BR1_ASRMo_sl "ASR engagement torque slow (0-99.06%)";
CM_ SG_ 416 BR1_ASRMo_fa "ASR engagement torque fast when MSR_Anf=0 (0-99.06%)";
CM_ SG_ 416 BR1_MSR_Mo_inv "Inverse MSR torque when MSR_Anf=1 (99.06-0%)";
CM_ SG_ 416 BR1_MSR_Mo "MSR engagement torque (0-99.06%)";
CM_ SG_ 416 BR1_Counter "Message counter to mark intervention moment [DE: BR1_Zaehler]";
CM_ SG_ 416 BR1_ASR_ESP "Control unit type: 0=ABS/EDS, 1=ASR/ESP/MABS";
CM_ SG_ 416 BR1_ESPASR_passive "ESP/ASR passive or deactivated by driver";
CM_ SG_ 416 BR1_Status_ESP "ESP error status (fault memory entry) [DE: BR1_Sta_ESP]";
CM_ SG_ 416 BR1_Substitute_Kmh "Speed is substitute value (sensor defect) [DE: BR1_Ersatz_Kmh]";

CM_ SG_ 640 Inner_Engine_Torque "Engine Indicated Torque [DE: inneres_Motor_Moment]";
CM_ SG_ 640 DriverDemandTorque "Driver Requested Torque [DE: Fahrerwunschmoment]";
CM_ SG_ 640 Mechanical_Engine_LossTorque "Mechanical Torque Loss [DE: mechanisches_Motor_Verlustmomen]";
CM_ SG_ 640 AccelPedalValue_Or_ThrottleValve "Accelerator Pedal or Throttle Position [DE: Fahrpedalwert_oder_Drosselklapp]";
CM_ SG_ 640 EngineRpm "Engine Speed [DE: Motordrehzahl]";
CM_ SG_ 640 TorqueData_Inaccurate "Approximate Torque Values [DE: Momentenangaben_ungenau]";
CM_ SG_ 640 Inner_Engine_Torque_Without_exter "Inner torque without external [DE: inneres_Motor_Moment_ohne_exter]";

CM_ SG_ 644 MOB_CHECKSUM "Checksum MOB";
CM_ SG_ 644 MOB_COUNTER "Counter MOB";

CM_ BO_ 648 "Motor message 2 - Contains engine status, temperatures, and torque information [DE: Motor_2]";
CM_ SG_ 648 MO2_Mp_Code "Multiplex code - switches after 4 transmissions";
CM_ SG_ 648 MO2_Gearbox_Code "Transmission code (multiplex value when Mp_Code=2) [DE: MO2_Getr_Code]";
CM_ SG_ 648 MO2_max_Mo "Maximum torque MDI (multiplex value when Mp_Code=3)";
CM_ SG_ 648 MO2_CAN_Vers "CAN version (multiplex value when Mp_Code=0)";
CM_ SG_ 648 MO2_Engine_Code "Motor code (multiplex value when Mp_Code=1) [DE: MO2_Motor_Code]";
CM_ SG_ 648 MO2_Coolant_T "Engine coolant temperature or substitute value [DE: MO2_Kuehlm_T]";
CM_ SG_ 648 MO2_BLS "Brake light switch - unfiltered raw signal";
CM_ SG_ 648 MO2_BTS "Brake test switch";
CM_ SG_ 648 MO2_Status_Coolant "Coolant temperature status - 0=OK, 1=Not OK [DE: MO2_Sta_Kuehlm]";
CM_ SG_ 648 MO2_Status_Climate "Air conditioning compressor status [DE: MO2_Sta_Klima]";
CM_ SG_ 648 MO2_Status_No_Bet "Normal operation status (Terminal 15 on, init complete) [DE: MO2_Sta_No_Bet]";
CM_ SG_ 648 MO2_Status_TSK "Drive train coordinator status";
CM_ SG_ 648 MO2_Status_GRA "GRA/ACC status [DE: MO2_Sta_GRA]";
CM_ SG_ 648 TSK_Limiter_Selected "Speed limiter selected [DE: TSK_Limiter_ausgewaehlt]";
CM_ SG_ 648 MO2_GRAregelt "GRA regulating to displayed speed";
CM_ SG_ 648 MO2_Sport_Error "Sport mode error (Porsche Cayenne)";
CM_ SG_ 648 MO2_OffRoad "OffRoad mode active";
CM_ SG_ 648 MO2_RME_Gehalt "Rapeseed oil methyl ester content (diesel)";
CM_ SG_ 648 MO2_GRA_Target "GRA target speed setpoint [DE: MO2_GRA_Soll]";
CM_ SG_ 648 MO2_LL_TargetRpm "Idle target speed [DE: MO2_LL_Solldz]";
CM_ SG_ 648 MO2_Limit_Mo "Limiting torque - max possible at speed [DE: MO2_Begr_Mo]";
CM_ SG_ 648 MO2_Mo_ZWR "Minimum engine torque with ignition angle retardation";

CM_ SG_ 896 MO3_Preheat "Pre-glow active (diesel engines) [DE: MO3_Vorgluehen]";
CM_ SG_ 896 MO3_Prio_Rpm "Engine speed priority: 0=request, 1=mandatory [DE: MO3_Prio_Dz]";
CM_ SG_ 896 MO_Switch_StartStop "Start/stop deactivated by driver (LED on when 0) [DE: MO_Schalter_StartStopp]";
CM_ SG_ 896 MO3_WinterProgram "Winter driving program active [DE: MO3_Winterprg]";
CM_ SG_ 896 MO3_Status_Pedal "Accelerator pedal status: 0=OK, 1=substitute value [DE: MO3_Sta_Pedal]";
CM_ SG_ 896 MO3_Status_FPG "Accelerator pedal gradient control bit (multiplexer for byte 8) [DE: MO3_Sta_FPG]";
CM_ SG_ 896 MO3_Sign_FPG "Accelerator pedal gradient sign (only when MO3_Sta_FPG=1)";
CM_ SG_ 896 MO3_Status_Temp "Intake air temperature status: 0=OK, 1=substitute value [DE: MO3_Sta_Temp]";
CM_ SG_ 896 MO3_Offsentemp "Intake air temperature";
CM_ SG_ 896 MO3_PedalValue "Accelerator pedal raw signal (0-101.6%) [DE: MO3_Pedalwert]";
CM_ SG_ 896 MO3_Wheel_Wu_Mo "Wheel torque request (12-bit value, 0-1596.66% MDI) [DE: MO3_Rad_Wu_Mo]";
CM_ SG_ 896 MO3_Sign_WheelWu "Wheel torque sign: 0=positive, 1=negative [DE: MO3_Vorz_RadWu]";
CM_ SG_ 896 MO3_Enable_Coasting "Sailing operation enable for transmission [DE: MO3_Freigabe_Segeln]";
CM_ SG_ 896 MO_StartStop_StopPreparation "Engine stop in preparation [DE: MO_StartStopp_StoppVorbereitung]";
CM_ SG_ 896 MO3_Rpm_Influence "Engine speed influence factor (0-100% interpolation) [DE: MO3_Dz_Beeinfl]";
CM_ SG_ 896 MO3_RequestRpm "Desired engine speed (when MO3_Prio_Dz=1) [DE: MO3_WunschDz]";
CM_ SG_ 896 MO3_DKW "Throttle valve position when MO3_Sta_FPG=0 (0-101.6%)";
CM_ SG_ 896 MO3_FPGradient "Accelerator pedal gradient when MO3_Sta_FPG=1 (0-6350%/s)";

CM_ SG_ 912 GK1_Fa_DoorContact "Status of the driver's door rotary latch [DE: GK1_Fa_Tuerkont]";
CM_ SG_ 912 BSK_HL_Opened "Status of the rear left door rotary latch [DE: BSK_HL_geoeffnet]";
CM_ SG_ 912 BSK_HR_Opened "Status of the rear right door rotary latch [DE: BSK_HR_geoeffnet]";
CM_ SG_ 912 BSK_BT_Opened "Status of the passenger door rotary latch [DE: BSK_BT_geoeffnet]";
CM_ SG_ 912 BSK_HD_MainDetent "Status of trunk lid main detent [DE: BSK_HD_Hauptraste]";

CM_ BO_ 1088 "Getriebe 1 - Contains gear status, torque requests, and control signals [DE: Getriebe_1]";

CM_ SG_ 1088 GE1_Shift "Gear shift active: 0=no shift, 1=shift in progress [DE: GE1_Schaltung]";
CM_ SG_ 1088 GE1_Status_Protection "Transmission/converter protection request (power reduction or ignition angle) [DE: GE1_Sta_Schutz]";
CM_ SG_ 1088 GE1_AcCompressor "AC compressor off request [DE: GE1_Klimakompr]";
CM_ SG_ 1088 GE1_WK "Torque converter clutch status";
CM_ SG_ 1088 GE1_StSt_Info "Start/stop coordinator info";
CM_ SG_ 1088 GE1_EGS_Req "EGS request - byte 4 becomes valid when set [DE: GE1_EGS_Anf]";
CM_ SG_ 1088 GE1_TargetGear "Target gear when shifting or current gear [DE: GE1_Zielgang]";
CM_ SG_ 1088 GE1_Selection_Pos "Selector lever position / driving program [DE: GE1_Wahl_Pos]";
CM_ SG_ 1088 GE1_Mrad_CrankTorque "Wheel torque to crankshaft torque ratio (Mrad/Mcrank) [DE: GE1_Mrad_Mkurb]";
CM_ SG_ 1088 GE1_Target_Mo "Internal target engine torque request (0-99.06%) [DE: GE1_Soll_Mo]";
CM_ SG_ 1088 GE1_Fahrwistd "Driving resistance index (normalized % slope)";
CM_ SG_ 1088 GE1_LimpHome "Emergency mode status [DE: GE1_Notlauf]";
CM_ SG_ 1088 GE1_Cooling "Cooling request level [DE: GE1_Kuehlung]";
CM_ SG_ 1088 GE1_Status_OBD "OBD status - MIL lamp control [DE: GE1_Sta_OBD]";
CM_ SG_ 1088 GE1_LaunchControl "Launch control active";
CM_ SG_ 1088 GE1_InfoBit "Transmission type: 0=stepped automatic, 1=CVT [DE: GE1_Infobit]";
CM_ SG_ 1088 GE1_SleepInd "Sleep readiness after terminal 15 off";
CM_ SG_ 1088 GE1_Zaehler "Message counter (synchronized with Getriebe_2)";
CM_ SG_ 1088 GE1_FaultEntry "Fault memory entry present [DE: GE1_Fehlereintr]";
CM_ SG_ 1088 GE1_WaVerl_Mo "Transmission torque loss / clutch torque (0-99.06%)";

CM_ SG_ 1056 ErrorStatus_OutsideTemp__4_1 "ambient temp error [DE: Fehlerstatus_Aussentemp__4_1]";
CM_ SG_ 1056 ErrorStatus_OilTemperature_4_1 "oil temp error [DE: Fehlerstatus_Oeltemperatur_4_1]";
CM_ SG_ 1056 ErrorStatus__CoolantTemp__4_1 "water temp error [DE: Fehlerst__Kuehlmitteltemp__4_1]";
CM_ SG_ 1056 OutsideTemperature_Filtered "outside temp, filtered [DE: Aussentemperatur_gefiltert]";
CM_ SG_ 1056 OilTemperature_4_1 "kombi oil temperature [DE: Oeltemperatur_4_1]";
CM_ SG_ 1056 CoolantTemp__4_1__Cluster_2_ "kombi coolant temperature [DE: Kuehlmitteltemp__4_1__Kombi_2_]";

CM_ SG_ 1096 Counter_SelectorLever_1 "Counter Waehlhebel_1 [DE: Zaehler_Waehlhebel_1]";

CM_ BO_ 1152 "Motor message 5 - Contains engine type, consumption, lamps, and diagnostic info [DE: Motor_5]";

CM_ SG_ 1152 MO5_Mp_Code "Multiplex selector - switches every 4 transmissions";
CM_ SG_ 1152 MO5_max_Torque "Maximum torque when Mp_Code=0 (0-630 Nm) [DE: MO5_max_Moment]";
CM_ SG_ 1152 MO5_Rpm "Engine speed at max torque when Mp_Code=1 (0-6300 RPM) [DE: MO5_Drehzahl]";
CM_ SG_ 1152 MO5_EngineType "Engine type info when Mp_Code=2 (cylinder count, turbo, fuel type) [DE: MO5_Motortyp]";
CM_ SG_ 1152 MO5_ExhaustType "Exhaust type EOBD when Mp_Code=3 [DE: MO5_Abgastyp]";
CM_ SG_ 1152 MO5_ExhaustType2 "Exhaust type OBD when Mp_Code=3 [DE: MO5_Abgastyp2]";
CM_ SG_ 1152 MO5_ExhaustType3 "DPF installed when Mp_Code=3 [DE: MO5_Abgastyp3]";
CM_ SG_ 1152 OBD_ColdStart_Denominator "Cold start denominator increment when Mp_Code=3 [DE: OBD_Kaltstart_Denominator]";
CM_ SG_ 1152 OBD_Minimum_Trip "Minimum normalized trip when Mp_Code=3";
CM_ SG_ 1152 MO5_DPF_reg "DPF regenerating when Mp_Code=3";
CM_ SG_ 1152 MO5_Preheat "Diesel pre-glow lamp [DE: MO5_Vorgluehen]";
CM_ SG_ 1152 MO5_E_Gas "E-Gas system lamp (petrol only)";
CM_ SG_ 1152 MO5_OBD_2 "OBD/MIL lamp control";
CM_ SG_ 1152 MO5_HotWarning "Coolant overheat warning lamp [DE: MO5_Heissl]";
CM_ SG_ 1152 MO5_AcCompressor "AC compressor off request [DE: MO5_KlimaKompr]";
CM_ SG_ 1152 MO5_Field_Cool "Map cooling installed and OK [DE: MO5_Feld_kuehl]";
CM_ SG_ 1152 MO5_KliKo_Red "AC compressor power reduction";
CM_ SG_ 1152 MO5_Consumption "Fuel consumption counter (15-bit, µl) [DE: MO5_Verbrauch]";
CM_ SG_ 1152 MO5_UeberlVerb "Consumption counter overflow";
CM_ SG_ 1152 MO5_Fan "Cooling fan PWM control (0-101.6%) [DE: MO5_Luefter]";
CM_ SG_ 1152 MO5_HLamp "Overheat pre-warning [DE: MO5_HLeuchte]";
CM_ SG_ 1152 MO5_ParticleLamp "Particle filter lamp [DE: MO5_PartikelLamp]";
CM_ SG_ 1152 MO5_Status_BKU "Brake vacuum pump status (Porsche only) [DE: MO5_Sta_BKU]";
CM_ SG_ 1152 MO5_TypeStartSteu "Starter control type: 0=BSG/BCM, 1=MSG [DE: MO5_TypStartSteu]";
CM_ SG_ 1152 MO5_TDE_Lamp "Fuel cap warning lamp (petrol only) [DE: MO5_TDE_Lampe]";
CM_ SG_ 1152 MO5_TDE_Text "Fuel cap text display (petrol only)";
CM_ SG_ 1152 MO5_DZM_Damping "RPM gauge damping control [DE: MO5_DZM_Daempf]";
CM_ SG_ 1152 MO5_Interlock "Interlock switch for manual transmission start";
CM_ SG_ 1152 MO5_Start "Automatic start permission";
CM_ SG_ 1152 MO5_Starter "Starter control permission [DE: MO5_Anlasser]";
CM_ SG_ 1152 MO5_GRA_Hauptsch "GRA main switch / readiness";
CM_ SG_ 1152 MO5_Torques "MDI torque values doubled [DE: MO5_Momente]";
CM_ SG_ 1152 MO5_EngineText1 "Text: Engine workshop [DE: MO5_Motortext1]";
CM_ SG_ 1152 MO5_EngineText2 "Text: Exhaust workshop (deprecated) [DE: MO5_Motortext2]";
CM_ SG_ 1152 MO5_EngineText3 "Text: Fuel system fault [DE: MO5_Motortext3]";
CM_ SG_ 1152 MO5_EngineText4 "Text: Particle filter needs regeneration [DE: MO5_Motortext4]";
CM_ SG_ 1152 CHECKSUM "Checksum with final value 0x0";

CM_ SG_ 1160 Counter_Engine_6 "Counter Motor_6 [DE: Zaehler_Motor_6]";
CM_ SG_ 1160 AltitudeInfo__Engine_6_ "Altitude Correction [DE: Hoeheninfo__Motor_6_]";
CM_ SG_ 1160 ActualTorque_f_r_Gearbox "Actual torque for gear [DE: Istmoment_f_r_Getriebe]";
CM_ SG_ 1160 TargetTorque_f_r_Gearbox "Target torque for gearbox [DE: Sollmoment_f_r_Getriebe]";
CM_ SG_ 1160 Checksum_Engine_6 "Checksum Motor_6 [DE: Checksumme_Motor_6]";
CM_ SG_ 1160 GRA_TargetAcceleration "GRA target acceleration [DE: GRA_Sollbeschleunigung]";
CM_ SG_ 1160 Feedback_Torque "Feedback torque-integral gear intervention [DE: Ruckmeldung_Momenten]";

CM_ SG_ 1344 Zahler_Gearbox_2 "Counter Getriebe_2 [DE: Zahler_Getriebe_2]";
CM_ SG_ 1344 HighShiftLamp "Upshift Flag [DE: Hochschaltlampe]";

CM_ SG_ 1386 ACA_V_Request "255=unset [DE: ACA_V_Wunsch]";

CM_ SG_ 1408 Counter_Engine_Flexia "Counter Motor_Flexia [DE: Zaehler_Motor_Flexia]";
CM_ SG_ 1408 CombustionType "Type of combustion [DE: Verbrennungsart]";
CM_ SG_ 1408 Max_Torque "Maximum torque [DE: Max_Drehmoment]";
CM_ SG_ 1408 Rpm_MaxNorm "RPM of maximum torque [DE: Drehzahl_MaxNorm]";
CM_ SG_ 1408 Displacement "Displacement [DE: Hubraum]";
CM_ SG_ 1408 Count_Cylinder "Number of cylinders [DE: Anzahl_Zylinder]";
CM_ SG_ 1408 Count_Valves "Number of valves [DE: Anzahl_Ventile]";
CM_ SG_ 1408 IntakeSystem "Induction System [DE: Ansaugsystem]";
CM_ SG_ 1408 EnginePower "Maximum engine power [DE: Motorleistung]";

CM_ SG_ 1416 BoostPressure "Boost Pressure [DE: Ladedruck]";
CM_ SG_ 1416 EngineRpmGradient "Engine speed gradient [DE: Motordrehzahlgradient]";
CM_ SG_ 1416 AltitudeInfo__Engine_7_ "Altitude correction factor [DE: Hoeheninfo__Motor_7_]";
CM_ SG_ 1416 OilTemperature "Oil temperature [DE: Oltemperatur]";

CM_ SG_ 1470 LDW_Direction "0=right,1=left";
CM_ SG_ 1470 XX_DLCORTLC1 "Might be DLC or TLC";
CM_ SG_ 1470 XX_DLCORTLC2 "Might be DLC or TLC, might have wrong size";

CM_ SG_ 1550 MFA_v_Signal_02 "0=km/h, 1=mph";

SG_MUL_VAL_ 416 BR1_ASRMo_fa BR1_MSR_Req 0-0;
SG_MUL_VAL_ 416 BR1_MSR_Mo_inv BR1_MSR_Req 1-1;

SG_MUL_VAL_ 896 MO3_DKW MO3_Status_FPG 0-0;
SG_MUL_VAL_ 896 MO3_FPGradient MO3_Status_FPG 1-1;
SG_MUL_VAL_ 896 MO3_Sign_FPG MO3_Status_FPG 1-1;

VAL_ 194 LW1_LRW_Sign 0 "Positive_Sign" 1 "Negative_Sign";
VAL_ 194 LW1_Speed_Sign 0 "Positive_Sign" 1 "Negative_Sign";
VAL_ 194 LW1_ID 0 "Yet_not_Calibrated" 128 "Calibrated_Only_At_PQ35_46_VW32x_VW411";
VAL_ 194 LW1_InitSource 0 "Brake_3" 1 "EPS_Bit";
VAL_ 194 LW1_Status 0 "OK" 1 "no_initial" 2 "sporadic_failure" 3 "permanent_failure";
VAL_ 194 LW1_Status_TERM30 0 "ok" 1 "no_init_s";

VAL_ 416 BR1_ASR_Req 0 "no_requirement" 1 "ASR_requirement";
VAL_ 416 BR1_MSR_Req 0 "no_requirement" 1 "MSR_requirement";
VAL_ 416 BR1_ABS_Brake 0 "no_ABS_control" 1 "ABS_control";
VAL_ 416 BR1_EDS_OnGround 0 "no_EDS_intervention" 1 "EDS_intervention";
VAL_ 416 BR1_ESP_OnGround 0 "no_ESP_intervention" 1 "ESP_intervention";
VAL_ 416 BR1_ASR_OnGround 0 "no_requirement" 1 "ASR_shift_map" 2 "Downshift" 3 "Switching_ban";
VAL_ 416 BR1_EBV_OnGround 0 "no_EBV_intervention" 1 "EBV_intervention";
VAL_ 416 BR1_Lamp_ABS 0 "Lamp_off" 1 "Lamp_on";
VAL_ 416 BR1_Lamp_ASR 0 "Lamp_off" 1 "Lamp_on";
VAL_ 416 BR1_Lamp_BK 0 "Lamp_off" 1 "Lamp_on";
VAL_ 416 BR1_LightShift 0 "no_Brakes_Threshold_unterschr" 1 "Brake_Pressed_Threshold_ueberschr";
VAL_ 416 BR1_StatusPressureThreshold 0 "Status_guel_BKV_n_angest_k_Br" 1 "Status_n_Avail_BKV_angest_Br";
VAL_ 416 BR1_MAD 0 "no_Unblanking" 1 "Unblanking";
VAL_ 416 BR1_Status_MAD 0 "valid" 1 "invalid";
VAL_ 416 BR1_Diagnostics 0 "no" 1 "in_Diagnostics";
VAL_ 416 BR1_BKV_active 0 "BKV_not_installed_or_fault" 1 "BKV_installed_and_not_fault";
VAL_ 416 BR1_ASR_ESP 0 "ABS_ABS_EDS" 1 "ASR_ESP_MABS";
VAL_ 416 BR1_ESPASR_passive 0 "ESP_ASR_activated" 1 "ESP_Or_ASR_passive_get_Or_Fktumsch_Or_RollerMode";
VAL_ 416 BR1_Status_ESP 0 "ok" 1 "Failure";
VAL_ 416 BR1_Substitute_Kmh 0 "OK" 1 "Substitute_value";

SG_MUL_VAL_ 648 MO2_Gearbox_Code MO2_Mp_Code 2-2;
SG_MUL_VAL_ 648 MO2_max_Mo MO2_Mp_Code 3-3;
SG_MUL_VAL_ 648 MO2_CAN_Vers MO2_Mp_Code 0-0;
SG_MUL_VAL_ 648 MO2_Engine_Code MO2_Mp_Code 1-1;

SG_MUL_VAL_ 1152 MO5_max_Torque MO5_Mp_Code 0-0;
SG_MUL_VAL_ 1152 MO5_Rpm MO5_Mp_Code 1-1;
SG_MUL_VAL_ 1152 MO5_EngineType MO5_Mp_Code 2-2;
SG_MUL_VAL_ 1152 MO5_ExhaustType MO5_Mp_Code 3-3;
SG_MUL_VAL_ 1152 MO5_ExhaustType2 MO5_Mp_Code 3-3;
SG_MUL_VAL_ 1152 MO5_ExhaustType3 MO5_Mp_Code 3-3;
SG_MUL_VAL_ 1152 OBD_ColdStart_Denominator MO5_Mp_Code 3-3;
SG_MUL_VAL_ 1152 OBD_Minimum_Trip MO5_Mp_Code 3-3;
SG_MUL_VAL_ 1152 MO5_DPF_reg MO5_Mp_Code 3-3;

VAL_ 648 MO2_Mp_Code 0 "CAN_Level" 1 "Engine_Kod" 2 "Gearbox_Kod" 3 "MDI_Max";

VAL_ 648 MO2_Gearbox_Code 0 "_5HP19" 1 "_5HP24" 2 "AG4" 3 "VL300" 4 "VQ250" 5 "VQ35" 6 "AG4_yestco" 7 "AG5_yestco" 8 "Auto_Clutch" 9 "Auto_Clutch_With_ASG" 10 "AG6_yestco_ZF_6HP_AISIN" 11 "DQ500_DQ250_DQ200" 12 "SQ100_SQ200" 14 "AL1000_AL551_AL951_ZF8HPx" 15 "ManualGearbox_konv" 16 "DL800" 17 "E_Vehicle__Single_Gear";

VAL_ 648 MO2_BLS 0 "no_Brakes" 1 "Brake_Pressed";
VAL_ 648 MO2_BTS 0 "no_braking" 1 "Brake_activated";
VAL_ 648 MO2_Status_Coolant 0 "Temperature_ok" 1 "Temperature_not_ok";
VAL_ 648 MO2_Status_Climate 0 "Climate_off" 1 "Climate_on";
VAL_ 648 MO2_Status_No_Bet 0 "no_NormalOperation" 1 "NormalOperation";
VAL_ 648 MO2_Status_TSK 0 "TSK_not_available" 1 "TSK_available";
VAL_ 648 MO2_Status_GRA 0 "ADDR_GRA_off" 1 "gra_activated_lamp_on" 2 "gra_overdriven_lamp_on" 3 "ADDR_gra_faulted";
VAL_ 648 TSK_Limiter_Selected 0 "no_limiter_selected" 1 "Limiter_Selected";
VAL_ 648 MO2_GRAregelt 0 "no" 1 "yes";
VAL_ 648 MO2_Sport_Error 0 "no_Failure" 1 "Failure";
VAL_ 648 MO2_OffRoad 0 "not_active" 1 "active";

VAL_ 870 AWV_Text 0 "No_Text" 1 "FrontAssist_Off" 2 "FrontAssist_Starting" 3 "FrontAssist_Warning" 4 "FrontAssist_Sens_reinig" 5 "FrontAssist_Failure" 6 "FrontAssist_Demo" 7 "Lead" 8 "Braking_Is_Straight_Performed" 9 "Sensor_not_Available" 10 "Sensor_Clean" 11 "Service_Necessary_Failure" 12 "Function_From_Driver_deactivated" 13 "Function_From_Driver_activated" 14 "FrontAssist_To_Time_not_Available__rev_Failure";
VAL_ 870 AWV_1_Enable 0 "Not_Enabled" 1 "Enabled";
VAL_ 870 AWV_1_Prefill 0 "No_Prefill_Req" 1 "Prefill_Req";
VAL_ 870 AWV_1_Parameter 0 "Defaultparametersatz" 1 "Param_leicht_erh_Recommend" 2 "Param_erh_Recommend" 3 "Param_hoechster_Recommend";
VAL_ 870 AWV_only 0 "ACC_And_AWV_Fitted" 1 "AWV_Without_ACC_Fitted";
VAL_ 870 AWV_CityANB_Variant 0 "Auto_Braking_In_Total_vRange" 1 "Auto_Braking_In_def_vRange";
VAL_ 870 AWV_Hold 0 "No_Request" 1 "Request_The_Veh_In_Standstill_Closed_Hold";
VAL_ 870 ANB_PartialBraking_Enable 0 "PartialBraking_Not_Enabled" 1 "PartialBraking_Enabled";
VAL_ 870 AWV_2_Status 0 "Lamp_Off" 1 "Lamp_On";
VAL_ 870 AWV_2_Error 0 "Lamp_Off" 1 "Lamp_On";
VAL_ 870 AWV_2_SU_WarnTime 0 "Early" 1 "normal" 2 "Late" 3 "adaptiv";
VAL_ 870 AWV_2_SU_BrakeJerk 0 "BrakeJerk_Deactivated" 1 "BrakeJerk_Activated";
VAL_ 870 AWV_2_SU_Chime 0 "Chime_Deactivated" 1 "Chime_Activated";
VAL_ 870 AWV_2_SU_Lamp 0 "Lamp_Deactivated" 1 "Lamp_Activated";
VAL_ 870 AWV_2_Umfeldwarn 0 "No_Warning" 1 "Warning";
VAL_ 870 AWV_2_Enable 0 "No_JerkEnable" 1 "JerkEnable";
VAL_ 870 AWV_2_JerkProfile 0 "No_Jerk" 1 "JerkProfile_1" 2 "JerkProfile_2" 3 "JerkProfile_3" 4 "JerkProfile_4" 5 "JerkProfile_5" 6 "not_Allowed" 7 "not_Allowed";
VAL_ 870 AWV_2_WarningTone 0 "Off" 1 "On";
VAL_ 870 AWV_2_Warnsymbol 0 "Off" 1 "On";
VAL_ 870 AWV_InfoTone 0 "Off" 1 "On";
VAL_ 870 AWV_2_BeltTensioner 0 "Belt_not_Tension" 1 "Belt_Tension";
VAL_ 870 AWV_Configuration_MenuReq 0 "Menu_Deactivate" 1 "Menu_Activate";
VAL_ 870 AWV_Configuration_Vorw_MenuReq 0 "Menu_Deactivate" 1 "Menu_Activate";
VAL_ 870 AWV_Configuration_Status 0 "AWV_Inactive" 1 "AWV_Active";
VAL_ 870 AWV_Configuration_Vorw_Status 0 "AWV_PreWarning_Inactive" 1 "AWV_PreWarning_Active";
VAL_ 870 AWV_2_DistanceWarning 0 "No_WarningNote" 1 "WarningNote";
VAL_ 870 ANB_TargetBraking_Enable 0 "TargetBraking_Not_Enabled" 1 "TargetBraking_Enabled";
VAL_ 870 ANB_CM_Request 0 "No_Request" 1 "Request_Active";

VAL_ 872 ACS_Status_ADDR 2 "ADDR_Passive" 0 "ADDR_Not_Active" 1 "ADDR_Active" 3 "Irrev_Error" ;
VAL_ 872 ACS_ADDR_Overrun 1 "Decel_Limit_Open_Overrun" 0 "Decel_Not_Limit_Open_Overrun" ;
VAL_ 872 ACS_OverrunCut 1 "SA_Not_Permitted" 0 "SA_Permitted" ;
VAL_ 872 ACS_StSt_Info 3 "SystemError" 0 "EngineRunning_nn" 1 "StopInhibit_EngineStartUp_nn" 2 "EngineStartUp_Necessary" ;
VAL_ 872 ACS_TorqueIntervention 1 "TorqueInterv_verhindern" 0 "No_Influence_TorqueInterv_Mot" ;
VAL_ 872 ACS_Type_ACC 0 "Base_ACC" 1 "ACC_With_FollowToStop" 3 "Free" 2 "Free" ;
VAL_ 872 ACS_EnableTargetB 0 "TargetAccel_Not_Enabled" 1 "TargetAccel_Enabled" ;
VAL_ 872 ACS_TargetAccel 2046 "ADDR_Not_Active" 2047 "Error" ;
VAL_ 872 ACS_TrailerOldRequest 0 "No_Haltewunsch" 1 "Veh_Holds_On" ;
VAL_ 872 ACS_Error 1 "FaultMemoryEntry" 0 "No_FaultMemoryEntry" ;
VAL_ 872 ACS_Allowed_ControlDeviation 254 "ADDR_Not_Active" 255 "Error" ;
VAL_ 872 ACS_max_ChangeDegree 254 "NeutralValue" 0 "NeutralValue" 255 "Error" ;

VAL_ 896 MO3_Preheat 0 "no_Preheat" 1 "Preheat_active";
VAL_ 896 MO3_Prio_Rpm 0 "Request" 1 "Forced";
VAL_ 896 MO_Switch_StartStop 0 "StartStop_Over_MainSwitch_deactivated_LED_On" 1 "StartStop_Over_MainSwitch_activated_LED_Off";
VAL_ 896 MO3_WinterProgram 0 "not_active" 1 "active";
VAL_ 896 MO3_Status_Pedal 0 "AccelPedal_iO" 1 "SubstituteValue";
VAL_ 896 MO3_Status_FPG 0 "Gradient_not_Condition" 1 "Gradient_Condition";
VAL_ 896 MO3_Sign_FPG 0 "Positive_Sign" 1 "Negative_Sign";
VAL_ 896 MO3_Status_Temp 0 "Sender_iO" 1 "SubstituteValue";
VAL_ 896 MO3_Sign_WheelWu 0 "Positive_Sign" 1 "Negative_Sign";
VAL_ 896 MO3_Enable_Coasting 0 "CoastingMode_not_Enabled" 1 "CoastingMode_Enabled";
VAL_ 896 MO_StartStop_StopPreparation 0 "EngineStop_not_in_Preparation" 1 "EngineStop_in_Preparation";
CM_ BO_ 896 "Motor message 3 - Contains accelerator pedal, temperatures, and control signals [DE: Motor_3]";

VAL_ 978 LH2_Status_HCA 0 "disabled" 1 "initializing" 2 "fault" 3 "ready" 4 "rejected" 5 "active" 7 "active";

VAL_ 1088 GE1_Shift 0 "no_circuit" 1 "circuit_is_running";
VAL_ 1088 GE1_Status_Protection 0 "no_protection" 1 "protection_requested";
VAL_ 1088 GE1_AcCompressor 0 "no_Request" 1 "Compressor_Off";
VAL_ 1088 GE1_WK 0 "WK_open" 1 "WK_regulated" 2 "WK_closed" 3 "Failure";
VAL_ 1088 GE1_StSt_Info 0 "Engine_running_not_necessary_stop_release" 1 "Engine_start_not_mandatory_necessary_stop_prohibition" 2 "Engine_start_absolute_necessary_start_request" 3 "System_error";
VAL_ 1088 GE1_EGS_Req 0 "no_requirement" 1 "EGS_requirement";
VAL_ 1088 GE1_TargetGear 0 "P (Park) | Disengaged" 1 "Gear 1 | Engaged" 2 "Gear 2 | Engaged" 3 "Gear 3 | Engaged" 4 "Gear 4 | Engaged" 5 "Gear 5 | Engaged" 6 "1m Gear" 7 "Gear_R" 8 "Gear 6 | Engaged" 9 "Gear 7 | Engaged" 10 "Gear 8 | Engaged" 14 "Speed Not Defined" 15 "Failure";
VAL_ 1088 GE1_Selection_Pos 8 "P" 7 "R" 6 "N" 5 "D" 9 "U" 12 "S" 14 "T" 10 "T" 11 "T";
VAL_ 1088 GE1_LimpHome 0 "No Emergency" 1 "No Switching" 2 "Switch to Neutral" 3 "50% Shifting Capacity" 4 "Driving Without UK" 5 "No Emeregency" 6 "No Emergency" 7 "No Emergency, Target Shifting Reached" 15 "Failure";
VAL_ 1088 GE1_Cooling 0 "No Additional Cooling Requested" 1 "20% Additional Fan Cooling Requested" 2 "40% Additional Fan Cooling Requested" 3 "Maximum Additional Fan Cooling Requested";
VAL_ 1088 GE1_Status_OBD 0 "MIL Off" 1 "MIL On";
VAL_ 1088 GE1_LaunchControl 0 "Launch Control Not Active" 1 "Launch Control Program Active";
VAL_ 1088 GE1_InfoBit 0 "Standard Automatic" 1 "CVT";
VAL_ 1088 GE1_SleepInd 0 "CAN is Required" 1 "Sleep Ready";
VAL_ 1088 GE1_FaultEntry 0 "No Failure Memory Entry" 1 "Failure Memory Entry";

VAL_ 1152 MO5_Mp_Code 0 "Max_Torque" 1 "Rpm" 2 "Engine_Type" 3 "ExhaustType_od_Norm_Consumption";
VAL_ 1152 MO5_ExhaustType 0 "no_EOBD" 1 "EOBD";
VAL_ 1152 MO5_ExhaustType2 0 "no_OBD" 1 "OBD";
VAL_ 1152 MO5_ExhaustType3 0 "no_DPF_Fitted" 1 "DPF_Fitted";
VAL_ 1152 OBD_ColdStart_Denominator 0 "Denominator_not_hochzaehlen" 1 "Bedingungen_To_Inkr_Of_ColdStart_Denom_erf";
VAL_ 1152 OBD_Minimum_Trip 0 "no_Min_Normed_Trip" 1 "Min_Normed_Trip";
VAL_ 1152 MO5_DPF_reg 0 "DPF_Regenerated_Not" 1 "DPF_Regenerated";
VAL_ 1152 MO5_Preheat 0 "Lamp_off" 1 "Lamp_on";
VAL_ 1152 MO5_E_Gas 0 "Lamp_off" 1 "Lamp_on";
VAL_ 1152 MO5_OBD_2 0 "Lamp_off" 1 "Lamp_on";
VAL_ 1152 MO5_HotWarning 0 "Lamp_off" 1 "Lamp_on";
VAL_ 1152 MO5_AcCompressor 0 "no_Request" 1 "AcCompressor_Off";
VAL_ 1152 MO5_Field_Cool 0 "no" 1 "yes";
VAL_ 1152 MO5_KliKo_Red 0 "no" 1 "yes";
VAL_ 1152 MO5_UeberlVerb 0 "no_Overflow" 1 "AtLeast_einmal_uebergelaufen";
VAL_ 1152 MO5_HLamp 0 "no_Warning" 1 "PreWarning";
VAL_ 1152 MO5_ParticleLamp 0 "Lamp_off" 1 "Lamp_on";
VAL_ 1152 MO5_Status_BKU 0 "iO_Or_not_Fitted" 1 "n_iO";
VAL_ 1152 MO5_TypeStartSteu 0 "StarterControl_BodyECU_BCM_KessyD1_ZAS" 1 "StarterControl_By_MSG";
VAL_ 1152 MO5_TDE_Lamp 0 "Lamp_off" 1 "Lamp_on";
VAL_ 1152 MO5_TDE_Text 0 "no_Text" 1 "Textanzeige_After_ISO";
VAL_ 1152 MO5_DZM_Damping 0 "normale_Damping" 1 "Dynamic_Damping";
VAL_ 1152 MO5_Interlock 0 "Interlock_not_Pressed" 1 "Interlock_Pressed";
VAL_ 1152 MO5_Start 0 "Start_not_Permitted" 1 "StartEnable";
VAL_ 1152 MO5_Starter 0 "Starter_May_Actuated_Become" 1 "Starter_LeaveLane_Actuation_not_Possible";
VAL_ 1152 MO5_GRA_Hauptsch 0 "Off" 1 "On";
VAL_ 1152 MO5_Torques 0 "Einfach" 1 "Doppelt";
VAL_ 1152 MO5_EngineText1 0 "no_Text" 1 "Text_1";
VAL_ 1152 MO5_EngineText2 0 "no_Text" 1 "Text_2";
VAL_ 1152 MO5_EngineText3 0 "no_Text" 1 "Text_3";
VAL_ 1152 MO5_EngineText4 0 "no_Text" 1 "Text_4";

VAL_ 1386 ACA_StatusACC 6 "ACC_rev_Off" 0 "MainSwitch_Off" 4 "ACC_In_Background" 3 "ACC_Active" 1 "Reserve" 2 "ACC_Passive" 7 "ACC_Irrev_Off" 5 "Free" ;
VAL_ 1386 ACA_ID_StatusACC 0 "No_Display" ;
VAL_ 1386 ACA_Fahrerhinw 1 "On" 0 "Off" ;
VAL_ 1386 ACA_DispDisplay 1 "Display_Ext" 0 "Display_Not_Ext" ;
VAL_ 1386 ACA_TimeGap 3 "TimeGap3" 10 "TimeGap10" 4 "TimeGap4" 14 "TimeGap14" 11 "TimeGap11" 2 "TimeGap2" 13 "TimeGap13" 9 "TimeGap9" 1 "TimeGap1" 8 "TimeGap8" 5 "TimeGap5" 15 "TimeGap15" 0 "Not_Defined" 12 "TimeGap12" 6 "TimeGap6" 7 "TimeGap7" ;
VAL_ 1386 ACA_V_Request 255 "No_Value_In_Memory" ;
VAL_ 1386 ACA_kmh_mph 0 "km_h" 1 "mph" ;
VAL_ 1386 ACA_Acoustic1 0 "No_Chime" 1 "Chime" ;
VAL_ 1386 ACA_Acoustic2 0 "No_Buzzer" 1 "Buzzer" ;
VAL_ 1386 ACA_PrioDisp 1 "Average_Prio" 3 "No_Display_Req" 0 "High_Prio" 2 "Low_Prio" ;
VAL_ 1386 ACA_gemZeitl 6 "TimeGap6" 2 "TimeGap2" 7 "TimeGap7" 13 "TimeGap13" 11 "TimeGap11" 4 "TimeGap4" 8 "TimeGap8" 12 "TimeGap12" 10 "TimeGap10" 0 "No_Object_Recorded" 1 "TimeGap1" 3 "TimeGap3" 9 "TimeGap9" 15 "TimeGap15" 14 "TimeGap14" 5 "TimeGap5" ;
VAL_ 1386 ACA_ACC_Decel 0 "ACC_Delayed_Not" 1 "ACC_Delayed" ;
VAL_ 1386 ACA_StatusGRA 3 "GRA_Active" 4 "GRA_Override" 2 "GRA_Passive" 0 "MainSwitch_Off" 6 "Free" 7 "GRA_Error" 1 "Reserve" 5 "Free" ;
VAL_ 1386 ACA_ID_StatusGRA 0 "No_Display" ;
VAL_ 1386 ACA_Coding 0 "ACC" 1 "GRA" ;
VAL_ 1386 ACA_SpeedoScale 0 "Not_Illuminated" 1 "Illuminated" ;
VAL_ 1386 ACA_Change_TimeGap 1 "Display_angef" 0 "No_Display" ;

VAL_ 1472 EP1_Error_Status 0 "Full_Function" 1 "Left_Side_Faulty" 2 "Right_Side_Faulty" 3 "Both_Side_Faulty";
VAL_ 1472 EP1_Status_EPB 0 "Brake_Opened" 1 "Brake_Closed";
VAL_ 1472 EP1_Status_Switch 0 "Full_Function" 1 "Switch_ausser_Function";
VAL_ 1472 EP1_ClampForce 31 "Error";
VAL_ 1472 EP1_SwitchInfo 0 "No_DriverRequest" 1 "DriverRequest_Open" 2 "DriverRequest_Close" 3 "SwitchError";
VAL_ 1472 EP1_Status_NWS 0 "Full_Function" 1 "No_Function";
VAL_ 1472 EP1_FaultEntry 0 "No_FaultMemoryEntry" 1 "FaultMemoryEntry";
VAL_ 1472 EP1_Enable_Ver 0 "DecelerationReq_Not_freigegeb" 1 "DecelerationReq_Enabled";
VAL_ 1472 EP1_AutoHold_Allowed 0 "Pers_Not_Permitted" 1 "Pers_Permitted";
VAL_ 1472 EP1_AutoHold_Active 0 "No" 1 "Yes";
VAL_ 1472 EP1_SleepInd 0 "CAN_Is_benoetigt" 1 "Sleep_Ready";
VAL_ 1472 EP1_Status_Term_15 0 "Term_15_Off" 1 "Term_15_On";
VAL_ 1472 EP1_Lamp_AutoP 0 "Lamp_Off" 1 "Lamp_On";
VAL_ 1472 EP1_BrakeLight 0 "Off" 1 "On";
VAL_ 1472 EP1_WarningTone1 0 "Off" 1 "On";
VAL_ 1472 EP1_WarningTone2 0 "Off" 1 "On";
VAL_ 1472 EP1_ReqShLock 0 "Off" 1 "On";
VAL_ 1472 EPB_AutoHoldLamp 0 "Lamp_Off" 1 "Lamp_On";
VAL_ 1472 EP1_QualTiltWi 0 "Valid_Value" 1 "Substitute_Init_Or_ErrorValue";
VAL_ 1472 EP1_ClutchModRange 0 "Kuppsensor_Off_ModRange" 1 "Kupplsensor_In_ModRange" 2 "Sensorsignal_Inaccurate" 3 "Sensor_Defective";
VAL_ 1472 EP1_HydraulicHold 0 "Veh_Not_Hydraulic_geh" 1 "Veh_Hydraulic_geh";
VAL_ 1472 EP1_Func_Lamp 0 "Lamp_Off" 1 "Lamp_On";
VAL_ 1472 EP1_WarningTone 0 "WarningTone_Off" 1 "WarningTone_On";
VAL_ 1472 EP1_Error_BKL 0 "BKL_Off" 1 "BKL_On";
VAL_ 1472 EP1_Error_Yellow 0 "Lamp_Off" 1 "Lamp_On";
VAL_ 1472 EP1__Text 0 "No_Text" 1 "Text_1" 2 "Text_2" 3 "Text_3" 4 "Text_4" 5 "Text_5" 6 "Reserved" 7 "Reserved" 8 "Text_8";
CM_ SG_ 1394 FaultMemoryEntry__ZAS_ "[DE: Fehlerspeichereintrag__ZAS_]";
CM_ SG_ 1394 Free_ZAS_1_3 "[DE: Frei_ZAS_1_3]";
CM_ SG_ 1394 Free_ZAS_1_2 "[DE: Frei_ZAS_1_2]";
CM_ SG_ 1394 Terminal_15_SV "[DE: Klemme_15_SV]";
CM_ SG_ 1394 Free_ZAS_1_1 "[DE: Frei_ZAS_1_1]";
CM_ SG_ 1394 Terminal_P__ParkingLightPosition_ "[DE: Klemme_P__Parklichtstellung_]";
CM_ SG_ 1394 Terminal_50__Start_ "[DE: Klemme_50__Starten_]";
CM_ SG_ 1394 Terminal_X__StartProcess_ "[DE: Klemme_X__Startvorgang_]";
CM_ SG_ 1394 Terminal_15__Z_ndung_On_ "[DE: Klemme_15__Z_ndung_ein_]";
CM_ SG_ 1394 S_Contact__Schl_ssel_Inserted_ "[DE: S_Kontakt__Schl_ssel_steckt_]";
CM_ SG_ 1336 Blocking_RearWiper_Detected "[DE: Blockierung_Heckwischer_erkannt]";
CM_ SG_ 1336 Free_Wiper_1_2 "[DE: Frei_Wischer_1_2]";
CM_ SG_ 1336 FaultMemoryEntry__Wiper_ "[DE: Fehlerspeichereintrag__Wischer_]";
CM_ SG_ 1336 Actuation_Wiper_Hec "[DE: Ansteuerung_Scheibenwischer_Hec]";
CM_ SG_ 1336 Actuation_Washer_Rear "[DE: Ansteuerung_Wascher_Heck]";
CM_ SG_ 1336 Wiper_Rear_eingeschal "[DE: Scheibenwischer_Heck_eingeschal]";
CM_ SG_ 1336 Blocking_FrontWiper_erkann "[DE: Blockierung_Frontwischer_erkann]";
CM_ SG_ 1336 Free_Wiper_1_1 "[DE: Frei_Wischer_1_1]";
CM_ SG_ 1336 Status_WasherJetHeater "[DE: Status_Waschduesenheizung]";
CM_ SG_ 1336 ParkPosition_FrontWiper "[DE: Parklage_Frontwischer]";
CM_ SG_ 1336 Actuation_FrontWiper_Schnel "[DE: Ansteuerung_Frontwischer_Schnel]";
CM_ SG_ 1336 Actuation_FrontWiper_Normal "[DE: Ansteuerung_Frontwischer_Normal]";
CM_ SG_ 1336 Actuation_Washer_Front "[DE: Ansteuerung_Wascher_Front]";
CM_ SG_ 1336 FrontWiper__SwitchedOn "[DE: Frontwischer__eingeschaltet]";
CM_ SG_ 1464 WFS_TextBits "[DE: WFS_Textbits]";
CM_ SG_ 1464 Free_WFS_1_1 "[DE: Frei_WFS_1_1]";
CM_ SG_ 1096 Free_SelectorLever_1_1 "[DE: Frei_Waehlhebel_1_1]";
CM_ SG_ 1096 Test_Active_Flag "[DE: Test_aktiv_Flag]";
CM_ SG_ 1096 SelectorLever_TestResult "[DE: Waehlhebel_Testergebnis]";
CM_ SG_ 1096 Error_SelectorLever "[DE: Fehler_Waehlhebel]";
CM_ SG_ 1096 SelectorLeverPosition "[DE: Waehlhebelposition]";
CM_ SG_ 1096 SelectorLever_Initialisation "[DE: Waehlhebel_Initialisierung]";
CM_ SG_ 1496 CD_Changer "[DE: CD_Wechsler]";
CM_ SG_ 1496 VoiceInput "[DE: Spracheingabe]";
CM_ SG_ 1496 Telematics "[DE: Telematik]";
CM_ SG_ 1496 Phone "[DE: Telefon]";
CM_ SG_ 1496 MMI_Front "[DE: MMI_vorne]";
CM_ SG_ 1496 MMI_Rear "[DE: MMI_hinten]";
CM_ SG_ 1496 Free_FitmentList_1_11 "[DE: Frei_Verbauliste_1_11]";
CM_ SG_ 1496 ClimatePanel_HL "[DE: Klimabedienteil_HL]";
CM_ SG_ 1496 Free_FitmentList_1_10 "[DE: Frei_Verbauliste_1_10]";
CM_ SG_ 1496 FuelSender "[DE: Tankgeber]";
CM_ SG_ 1496 AssistDrivingLight "[DE: Assistenzfahrlicht]";
CM_ SG_ 1496 Memory_hinter_Driver "[DE: Memory_hinter_Fahrer]";
CM_ SG_ 1496 SeatMemory_Rear "[DE: Sitzmemory_hinten]";
CM_ SG_ 1496 SeatMemory_Passenger "[DE: Sitzmemory_Beifahrer]";
CM_ SG_ 1496 Trailer_ngersteuergeraet "[DE: Anh_ngersteuergeraet]";
CM_ SG_ 1496 EnergyManagement "[DE: Energiemanagement]";
CM_ SG_ 1496 WiperModule "[DE: Wischermodul]";
CM_ SG_ 1496 EZS___Kessy__Comfort_ "[DE: EZS___Kessy__Komfort_]";
CM_ SG_ 1496 RoofControlUnit "[DE: Verdecksteuergeraet]";
CM_ SG_ 1496 AuxHeater "[DE: Standheizung]";
CM_ SG_ 1496 Free_FitmentList_1_9 "[DE: Frei_Verbauliste_1_9]";
CM_ SG_ 1496 ParkAssist "[DE: Einparkhilfe]";
CM_ SG_ 1496 ClimateControlUnit_Comfort "[DE: Klimasteuergeraet_Komfort]";
CM_ SG_ 1496 SteeringColumnModule "[DE: Lenksaeulenmodul]";
CM_ SG_ 1496 TyrePressure "[DE: Reifendruck]";
CM_ SG_ 1496 InstrumentCluster_Comfort "[DE: Kombiinstrument_Komfort]";
CM_ SG_ 1496 RoofModule "[DE: Dachmodul]";
CM_ SG_ 1496 DoorECU_HR "[DE: TSG_HR]";
CM_ SG_ 1496 DoorECU_HL "[DE: TSG_HL]";
CM_ SG_ 1496 DoorECU_BT "[DE: TSG_BT]";
CM_ SG_ 1496 DoorECU_FT "[DE: TSG_FT]";
CM_ SG_ 1496 BodyECU_Comfort "[DE: BSG_Komfort]";
CM_ SG_ 1496 Free_FitmentList_1_8 "[DE: Frei_Verbauliste_1_8]";
CM_ SG_ 1496 Stabiliser_Decoupling "[DE: Stabi_Entkopplung]";
CM_ SG_ 1496 SelectorLever "[DE: Waehlhebel]";
CM_ SG_ 1496 BatteryManager "[DE: Batteriemanager]";
CM_ SG_ 1496 Damper_ECU "[DE: Daempfer_SG]";
CM_ SG_ 1496 LevelControl "[DE: Niveauregulierung]";
CM_ SG_ 1496 EZS___Kessy__Drive_ "[DE: EZS___Kessy__Antrieb_]";
CM_ SG_ 1496 BrakeBooster "[DE: Bremsbooster]";
CM_ SG_ 1496 PowerSteering "[DE: Lenkhilfe]";
CM_ SG_ 1496 Cluster_Drive "[DE: Kombi_Antrieb]";
CM_ SG_ 1496 InjectionPump "[DE: Einspritzpumpe]";
CM_ SG_ 1496 SteeringAngle "[DE: Lenkwinkel]";
CM_ SG_ 1496 AllWheelDrive "[DE: Allrad]";
CM_ SG_ 1496 BodyECU_Drive "[DE: BSG_Antrieb]";
CM_ SG_ 1496 ADDR "[DE: ADR]";
CM_ SG_ 1496 Climatronic_Drive "[DE: Climatronic_Antrieb]";
CM_ SG_ 1496 GearboxControlUnit "[DE: Getriebesteuergeraet]";
CM_ SG_ 1496 EngineControlUnit "[DE: Motorsteuergeraet]";
CM_ SG_ 1488 CAN_Level_4_1_Drive_Data_Hau "[DE: CAN_Stand_4_1_Antrieb_Daten_Hau]";
CM_ SG_ 1488 CAN_Level_4_1_Drive_Data_Neb "[DE: CAN_Stand_4_1_Antrieb_Daten_Neb]";
CM_ SG_ 1488 CAN_Level_4_1_Comfort_Data_Hau "[DE: CAN_Stand_4_1_Komfort_Daten_Hau]";
CM_ SG_ 1488 CAN_Level_4_1_Comfort_Data_Neb "[DE: CAN_Stand_4_1_Komfort_Daten_Neb]";
CM_ SG_ 1488 Free_SystemInfo_1_6 "[DE: Frei_Systeminfo_1_6]";
CM_ SG_ 1488 FourDoor "[DE: Viertuerer]";
CM_ SG_ 1488 RightHandDrive "[DE: Rechtslenker]";
CM_ SG_ 1488 Vehicle_Index "[DE: Fahrzeug_Index]";
CM_ SG_ 1488 Vehicle_Generation "[DE: Fahrzeug_Generation]";
CM_ SG_ 1488 Vehicle_Derivative "[DE: Fahrzeug_Derivat]";
CM_ SG_ 1488 Vehicle_Brand_2 "[DE: Fahrzeug_Marke_2]";
CM_ SG_ 1488 Vehicle_Class "[DE: Fahrzeug_Klasse]";
CM_ SG_ 1488 FitmentInformation_Valid "[DE: Verbauinformation_gueltig]";
CM_ SG_ 1488 CAN_Infotainment_Fitted "[DE: CAN_Infotainment_verbaut]";
CM_ SG_ 1488 CAN_Infotainment_in_Diagnostics "[DE: CAN_Infotainment_in_Diagnose]";
CM_ SG_ 1488 CAN_Comfort_in_Diagnostics "[DE: CAN_Komfort_in_Diagnose]";
CM_ SG_ 1488 Sleep_CAN_Comfort "[DE: Sleep_CAN_Komfort]";
CM_ SG_ 1488 CAN_Drive_in_Diagnostics "[DE: CAN_Antrieb_in_Diagnose]";
CM_ SG_ 1488 CAN_External_SwitchedIn "[DE: CAN_Extern_zugeschaltet]";
CM_ SG_ 268 Delta_Reduced_TargetTorque "[DE: Delta_reduziertes_Sollmoment]";
CM_ SG_ 268 Delta_ThrottleValveAngle "[DE: Delta_Drosselklappenwinkel]";
CM_ SG_ 268 Free_Slave_1_1 "[DE: Frei_Slave_1_1]";
CM_ SG_ 268 Delta_IgnitionAngleOutput "[DE: Delta_Zuendwinkelausgabe]";
CM_ SG_ 268 BattVoltage_Enable_DVE__Slave_ "[DE: Ubat_Freigabe_DVE__Slave_]";
CM_ SG_ 268 ThrottleValve_Sollwertbegrenzun "[DE: Drosselklappe_Sollwertbegrenzun]";
CM_ SG_ 268 InjectionInhibit_Learn__Slave_ "[DE: Einspritzverbot_lernen__Slave_]";
CM_ SG_ 268 Master_Detected__Slave_ "[DE: Master_erkannt__Slave_]";
CM_ SG_ 268 Error_TorqueOutput "[DE: Fehler_Momentenausgabe]";
CM_ SG_ 268 Error_Gearbox_Torque "[DE: Fehler_Getriebe_Moment]";
CM_ SG_ 268 Error_BrakesMessage "[DE: Fehler_Bremsenbotschaft]";
CM_ SG_ 268 Indicated_ActualTorque__Slave_ "[DE: Indiziertes_Istmoment__Slave_]";
CM_ SG_ 268 Timeout_BrakesMessage "[DE: Timeout_Bremsenbotschaft]";
CM_ SG_ 1332 PositionDetection_Beifahrersit "[DE: Positionserkennung_Beifahrersit]";
CM_ SG_ 1332 PassengerSeat_In_Front_Dritt "[DE: Beifahrersitz_im_vorderen_Dritt]";
CM_ SG_ 1332 PositionDetection_DriverSeat_u "[DE: Positionserkennung_Fahrersitz_u]";
CM_ SG_ 1332 DriverSeat_In_Front_Third "[DE: Fahrersitz_im_vorderen_Drittel]";
CM_ SG_ 1332 Counter_SeatInfo "[DE: Zaehler_Sitzinfo]";
CM_ SG_ 1332 Checksum_SeatInfo "[DE: Checksumme_Sitzinfo]";
CM_ SG_ 1810 SelfTestResult "[DE: Selbsttestergebnis]";
CM_ SG_ 1298 RAM_Contents_4 "[DE: RAM_Inhalt_4]";
CM_ SG_ 1298 RAM_Contents_3 "[DE: RAM_Inhalt_3]";
CM_ SG_ 1298 RAM_Contents_2 "[DE: RAM_Inhalt_2]";
CM_ SG_ 1298 RAM_Contents_1 "[DE: RAM_Inhalt_1]";
CM_ SG_ 274 PumpTemperature__2_1_ "[DE: Pumpentemperatur__2_1_]";
CM_ SG_ 274 PumpTemperature__3_2_2_ "[DE: Pumpentemperatur__3_2_2_]";
CM_ SG_ 274 CylinderCounter__3_2_2_ "[DE: Zylinderzaehler__3_2_2_]";
CM_ SG_ 274 ActuationTime__3_2_2_ "[DE: Ansteuerdauer__3_2_2_]";
CM_ SG_ 274 CamshaftSpeed__3_2_2_ "[DE: Nockenwellendrehzahl__3_2_2_]";
CM_ SG_ 274 Pump_StatusWord__3_2_2_ "[DE: Pumpen_Statuswort__3_2_2_]";
CM_ SG_ 1300 OBD_For_NOX "[DE: OBD_fuer_NOX]";
CM_ SG_ 1300 Free_NOX1_4 "[DE: Frei_NOX1_4]";
CM_ SG_ 1300 ProbeHeater_NOX "[DE: Sondenheizung_NOX]";
CM_ SG_ 1300 OffsetCorrection_NOX "[DE: Offsetkorrektur_NOX]";
CM_ SG_ 1300 Free_NOX1_3 "[DE: Frei_NOX1_3]";
CM_ SG_ 1300 Oxygen_Binary "[DE: Sauerstoff_binaer]";
CM_ SG_ 1300 Free_NOX1_2 "[DE: Frei_NOX1_2]";
CM_ SG_ 1300 Oxygen_linear "[DE: Sauerstoff_linear]";
CM_ SG_ 1300 Free_NOX1_1 "[DE: Frei_NOX1_1]";
CM_ SG_ 1424 LoadState "[DE: Beladungszustand]";
CM_ SG_ 1424 FaultMemoryEntry__Level_1 "[DE: Fehlerspeichereintrag__Niveau_1]";
CM_ SG_ 1424 SystemStatus__Level_1_ "[DE: Systemstatus__Niveau_1_]";
CM_ SG_ 1424 Reserve_VehicleType "[DE: Reserve_Fahrzeugart]";
CM_ SG_ 1424 VehicleType_Level "[DE: Fahrzeugart_Niveau]";
CM_ SG_ 1424 TextBits__Level_1_ "[DE: Textbits__Niveau_1_]";
CM_ SG_ 1424 Adjustment_HL "[DE: Verstellung_HL]";
CM_ SG_ 1424 Adjustment_HR "[DE: Verstellung_HR]";
CM_ SG_ 1424 Adjustment_VL "[DE: Verstellung_VL]";
CM_ SG_ 1424 Adjustment_VR "[DE: Verstellung_VR]";
CM_ SG_ 1424 Lowering_Vehicle "[DE: Absenkung_Fahrzeug]";
CM_ SG_ 1424 Raise_Vehicle "[DE: Anhebung_Fahrzeug]";
CM_ SG_ 1424 Adjustment_Active "[DE: Verstellung_aktiv]";
CM_ SG_ 1424 CompressorRun_in_Kuerze "[DE: Kompressorlauf_in_Kuerze]";
CM_ SG_ 1424 Free_Level_1_5 "[DE: Frei_Niveau_1_5]";
CM_ SG_ 1424 PushButton_Level "[DE: Taster_Niveau]";
CM_ SG_ 1424 ParkLevel "[DE: Parkniveau]";
CM_ SG_ 1424 BetweenLevel "[DE: Zwischenniveau]";
CM_ SG_ 1424 LevelStatuses "[DE: Niveaustati]";
CM_ SG_ 1424 MSG_Restriction "[DE: MSG_Einschraenkung]";
CM_ SG_ 1424 ESP_Influence "[DE: ESP_Beeinflussung]";
CM_ SG_ 1424 WarningLamp_Level_1 "[DE: Warnlampe_Niveau_1]";
CM_ SG_ 1424 Free_Level_1_1 "[DE: Frei_Niveau_1_1]";
CM_ SG_ 1424 Counter_Level_1 "[DE: Zaehler_Niveau_1]";
CM_ SG_ 1424 Checksum_Level_1 "[DE: Checksumme_Niveau_1]";
CM_ SG_ 1328 JunctionType "[DE: Kreuzungstyp]";
CM_ SG_ 1328 Distance_To_Junction "[DE: Entfernung_bis_Kreuzung]";
CM_ SG_ 1328 Distance_To_CurveStart "[DE: Entfernung_bis_Kurvenanfang]";
CM_ SG_ 1328 Voarusliegende_CurveDirection "[DE: Voarusliegende_Kurvenrichtung]";
CM_ SG_ 1328 Ahead_CurvePath "[DE: Vorausliegender_Kurvenverlauf]";
CM_ SG_ 1328 Error_Navigation "[DE: Fehler_Navigation]";
CM_ SG_ 1328 Count_Carriageways__0_Actual_Invalid "[DE: Anzahl_Fahrbahnen__0_ist_unguel]";
CM_ SG_ 1328 RoadType "[DE: Strassentyp]";
CM_ SG_ 1328 CountryId "[DE: Laenderkennung]";
CM_ SG_ 1328 Sign_YawRate______ "[DE: Vorzeichen_Gierrate______]";
CM_ SG_ 1328 YawRateError "[DE: Gierratenfehler]";
CM_ SG_ 1328 YawRate "[DE: Gierrate]";
CM_ SG_ 1792 MSG_Configuration "[DE: MSG_Konfiguration]";
CM_ SG_ 1792 Position_Of_OT_Pulse "[DE: Lage_des_OT_Impuls]";
CM_ SG_ 1280 RAM_Address_4 "[DE: RAM_Adresse_4]";
CM_ SG_ 1280 RAM_Address_3 "[DE: RAM_Adresse_3]";
CM_ SG_ 1280 RAM_Address_2 "[DE: RAM_Adresse_2]";
CM_ SG_ 1280 Ram_Address_1 "[DE: Ram_Adresse_1]";
CM_ SG_ 256 CrankshaftSpeed__3_2_2_ "[DE: Kurbelwellendrehzahl__3_2_2_]";
CM_ SG_ 256 Target_DeliveryStart_KW__3_2_2_ "[DE: Soll_Foerderbeginn_KW__3_2_2_]";
CM_ SG_ 256 Target_DeliveryStart_NW__3_2_2_ "[DE: Soll_Foerderbeginn_NW__3_2_2_]";
CM_ SG_ 256 Target_BeforeInjection "[DE: Soll_Voreinspritzung]";
CM_ SG_ 256 Target_InjectionQuantity "[DE: Soll_Einspritzmenge]";
CM_ SG_ 1796 Free_Engine_NOX_1_2 "[DE: Frei_Motor_NOX_1_2]";
CM_ SG_ 1796 Free_Engine_NOX_1_1 "[DE: Frei_Motor_NOX_1_1]";
CM_ SG_ 1796 HeatPowerRequest "[DE: Heizleistungsanforderung]";
CM_ SG_ 1796 OffsetCorrection_Possible "[DE: Offsetkorrektur_moeglich]";
CM_ SG_ 1796 OperationRange "[DE: Betriebsbereich]";
CM_ SG_ 1796 ExhaustTemperature_NOX "[DE: Abgastemperatur_NOX]";
CM_ SG_ 1796 ExhaustPressure_NOX "[DE: Abgasdruck_NOX]";
CM_ SG_ 900 TorqueData_Inaccurate__Torque "[DE: Momentenangaben_ungenau__Moment]";
CM_ SG_ 1408 Gradient_The_FillCurve "[DE: Steigung_der_Befuellungskennlin]";
CM_ SG_ 1408 WeightingFactor_SootIndex_Turbo "[DE: Bewertungsfaktor_Russindex_Turb]";
CM_ SG_ 1408 WeightingFactor_WearIndex "[DE: Bewertungsfaktor_Verschleissind]";
CM_ SG_ 1408 Manufacturer_Code "[DE: Hersteller_Code]";
CM_ SG_ 1408 Normalised_Consumption "[DE: Normierter_Verbrauch]";
CM_ SG_ 1408 OilLevelThreshold "[DE: Oelniveauschwelle]";
CM_ SG_ 1408 WearIndex "[DE: Verschleissindex]";
CM_ SG_ 1408 SootIndex "[DE: Russindex]";
CM_ SG_ 1408 Free_Engine_Flexia_1 "[DE: Frei_Motor_Flexia_1]";
CM_ SG_ 1408 Multiplex_Switch_Engine_Flexia "[DE: Multiplex_Schalter_Motor_Flexia]";
CM_ SG_ 1416 Free_Engine_7_3 "[DE: Frei_Motor_7_3]";
CM_ SG_ 1416 Sign_EngineRpmGradient "[DE: Vorzeichen_Motordrehzahlgradien]";
CM_ SG_ 1416 Terminal_DFM "[DE: Klemme_DFM]";
CM_ SG_ 1416 PTC___GlowPlugs_SwitchedOff "[DE: PTC___Gluehstifte_ausgeschaltet]";
CM_ SG_ 1416 Free_Engine_7_1 "[DE: Frei_Motor_7_1]";
CM_ SG_ 1416 FaultMemoryEntry__Engine_7_ "[DE: Fehlerspeichereintrag__Motor_7_]";
CM_ SG_ 1416 StatusBit_SpeedLimit "[DE: Statusbit_Geschwindikeitsbegren]";
CM_ SG_ 1416 SpeedLimit_Activatable "[DE: Geschwindigkegrenzung_aktivierb]";
CM_ SG_ 1416 Idle_TargetRpm_Open_Max_W "[DE: Leerlauf_Solldrehzahl_auf_Max_W]";
CM_ SG_ 1160 Free_Engine_6_4 "[DE: Frei_Motor_6_4]";
CM_ SG_ 1160 OilTempProtection "[DE: ltemperaturschutz]";
CM_ SG_ 1160 GRA_BrakeIntervention_Enable "[DE: GRA_Bremseingriff_Freigabe]";
CM_ SG_ 1160 Free_Engine_6_3 "[DE: Frei_Motor_6_3]";
CM_ SG_ 640 ErrorStatus_Gearbox_TorqueIntervention "[DE: Fehlerstatus_Getriebe_Momentene]";
CM_ SG_ 640 ErrorStatus_Brake_TorqueInput "[DE: Fehlerstatus_Brems_Momenteneing]";
CM_ SG_ 640 Time_Out_Brakes_Message "[DE: Time_Out_Bremsen_Botschaft]";
CM_ SG_ 640 ClutchSwitch "[DE: Kupplungsschalter]";
CM_ SG_ 640 KickdownSwitch "[DE: Kickdownschalter]";
CM_ SG_ 640 AccelPedalValue_Inaccurate__Engine_1_ "[DE: Fahrpedalwert_ungenau__Motor_1_]";
CM_ SG_ 640 IdleInformation "[DE: Leergasinformation]";
CM_ SG_ 262 Free_Master_3_1 "[DE: Frei_Master_3_1]";
CM_ SG_ 262 EngineTemperature_Linearised "[DE: Motortemperatur_linearisiert]";
CM_ SG_ 262 Indicated_TargetTorque_f_r_Vmax "[DE: Indiziertes_Sollmoment_f_r_Vmax]";
CM_ SG_ 262 Relative_TorqueRequest_de "[DE: Relative_Momentenanforderung_de]";
CM_ SG_ 262 Delta_EngineTorque_Off_LossTorque "[DE: Delta_Motormoment_aus_Verlustmo]";
CM_ SG_ 260 BattVoltage_Enable_DVE "[DE: Ubat_Freigabe_DVE]";
CM_ SG_ 260 DK_SetpointLimit "[DE: DK_Sollwertbegrenzung]";
CM_ SG_ 260 InjectionInhibit_DV_E_Learn "[DE: Einspritzverbot_DV_E_lernen]";
CM_ SG_ 260 Master_Detected "[DE: Master_erkannt]";
CM_ SG_ 260 Vmax_Limit_Active "[DE: Vmax_Begrenzung_aktiv]";
CM_ SG_ 260 SA_Inhibit_From_FGR "[DE: SA_Verbot_von_FGR]";
CM_ SG_ 260 PedalValue_Complement "[DE: Pedalwert_Komplement]";
CM_ SG_ 260 Counter__Master_2_ "[DE: Zaehler__Master_2_]";
CM_ SG_ 260 Normalised_AccelPedalAngle "[DE: Normierter_Fahrpedalwinkel]";
CM_ SG_ 258 Stationary_TargetRpm "[DE: Stationaere_Solldrehzahl]";
CM_ SG_ 258 Torque_LLR__I_Share_ "[DE: Drehmoment_LLR__I_Anteil_]";
CM_ SG_ 258 Torque_LLR__PD_Share_ "[DE: Drehmoment_LLR__PD_Anteil_]";
CM_ SG_ 258 Torque_LLR__AirPath_ "[DE: Drehmoment_LLR__Luftpfad_]";
CM_ SG_ 258 Free_Master_1_1 "[DE: Frei_Master_1_1]";
CM_ SG_ 258 LLR_Actual_Active "[DE: LLR_ist_aktiv]";
CM_ SG_ 258 I_Share_The_LLR_Active "[DE: I_Anteil_der_LLR_aktiv]";
CM_ SG_ 258 PD_Share_The_LLR_Active "[DE: PD_Anteil_der_LLR_aktiv]";
CM_ SG_ 258 LLR_Enable_After_Start "[DE: LLR_Freigabe_nach_Start]";
CM_ SG_ 1984 Free_LWS_Calibration_1_1 "[DE: Frei_LWS_Kalibrierung_1_1]";
CM_ SG_ 1984 Free_LWS_Calibration_1_2 "[DE: Frei_LWS_Kalibrierung_1_2]";
CM_ SG_ 1986 CodingBytes "[DE: Kodierbytes]";
CM_ SG_ 192 Sign__RB_ "[DE: Vorzeichen__RB_]";
CM_ SG_ 192 SteeringAngle__RB_ "[DE: Lenkwinkel__RB_]";
CM_ SG_ 192 LWS_Alignment__RB_ "[DE: LWS_Abgleich__RB_]";
CM_ SG_ 192 Free_SteeringAngle_1_1__RB_ "[DE: Frei_Lenkwinkel_1_1__RB_]";
CM_ SG_ 196 Sign__ITT_ "[DE: Vorzeichen__ITT_]";
CM_ SG_ 196 SteeringAngle__ITT_ "[DE: Lenkwinkel__ITT_]";
CM_ SG_ 196 LWS_Alignment__ITT_ "[DE: LWS_Abgleich__ITT_]";
CM_ SG_ 196 LWS_Initialisation__ITT_ "[DE: LWS_Initialisierung__ITT_]";
CM_ SG_ 1502 WorkshopCode "[DE: Werkstattcode]";
CM_ SG_ 1502 SensorCoding_PowerSteering "[DE: Sensorcodierung_Lenkhilfe]";
CM_ SG_ 1502 CurveCoding_PowerSteering "[DE: Kennliniencodierung_Lenkhilfe]";
CM_ SG_ 1502 Sender_f__Lenkw__Memory_ausles "[DE: Geber_f__Lenkw__Speicher_ausles]";
CM_ SG_ 1502 InstrumentCluster__Memory_ReadOut "[DE: Kombiinstr__Speicher_auslesen]";
CM_ SG_ 1502 ControlUnit__Memory_ReadOut "[DE: Steuerger__Speicher_auslesen]";
CM_ SG_ 1502 PowerSteering_ControlUnit_Defective "[DE: Lenkhilfe_Steuergeraet_defekt]";
CM_ SG_ 1502 Free_PowerSteering_1_3 "[DE: Frei_Lenkhilfe_1_3]";
CM_ SG_ 1502 Free_PowerSteering_1_4 "[DE: Frei_Lenkhilfe_1_4]";
CM_ SG_ 1502 Sender_f__Lenkwi__k__CAN_Comm_sp "[DE: Geber_f__Lenkwi__k__CAN_Komm_sp]";
CM_ SG_ 1502 Sender_f__SteeringAngle_k__CAN_Comm "[DE: Geber_f__Lenkwinkel_k__CAN_Komm]";
CM_ SG_ 1502 InstrumentCluster__k__CAN_Comm__sp "[DE: Kombiinstr__k__CAN_Kommunik__sp]";
CM_ SG_ 1502 InstrumentCluster_k__CAN_Comm "[DE: Kombiinstrument_k__CAN_Kommunik]";
CM_ SG_ 1502 ControlUnit_k__CAN_Comm__S "[DE: Steuergeraet_k__CAN_Kommunik__S]";
CM_ SG_ 1502 ControlUnit_No_CAN_Comm "[DE: Steuergeraet_keine_CAN_Kommunik]";
CM_ SG_ 1502 PowerSteering_Voltage_Ks__After_Mas "[DE: Lenkhilfe_Spannung_Ks__nach_Mas]";
CM_ SG_ 1502 PowerSteering_Voltage_Ks_After_Mass "[DE: Lenkhilfe_Spannung_Ks_nach_Mass]";
CM_ SG_ 1502 PowerSteering_Voltage_Ks__After___s "[DE: Lenkhilfe_Spannung_Ks__nach___s]";
CM_ SG_ 1502 PowerSteering_Voltage_Ks__After__ "[DE: Lenkhilfe_Spannung_Ks__nach__]";
CM_ SG_ 1502 PowerSteering_TemperatureProtection_sp_ "[DE: Lenkhilfe_Temperaturschutz_sp_]";
CM_ SG_ 1502 PowerSteering_TemperatureProtection "[DE: Lenkhilfe_Temperaturschutz]";
CM_ SG_ 1502 PowerSteering_Operation_Implaus__Sig__sp "[DE: Lenkhilfe_Betrieb_unpl__Sig__sp]";
CM_ SG_ 1502 PowerSteering_Operation_Implaus__Signal "[DE: Lenkhilfe_Betrieb_unpl__Signal]";
CM_ SG_ 1502 PowerSteeringSensor_k__Comm__sp "[DE: Lenkhilfesensor_k__Kommunik__sp]";
CM_ SG_ 1502 PowerSteeringSensor_No_Comm_ "[DE: Lenkhilfesensor_keine_Kommunik_]";
CM_ SG_ 1502 PowerSteeringSensor_Defective_sp_ "[DE: Lenkhilfesensor_defekt_sp_]";
CM_ SG_ 1502 PowerSteeringSensor_Defective "[DE: Lenkhilfesensor_defekt]";
CM_ SG_ 1502 PowerSteeringSensor_OpenCircuit_s "[DE: Lenkhilfesensor_Unterbrechung_s]";
CM_ SG_ 1502 PowerSteeringSensor_OpenCircuit "[DE: Lenkhilfesensor_Unterbrechung]";
CM_ SG_ 1502 PowerSteeringSensor_Ks_After_Mass_s "[DE: Lenkhilfesensor_Ks_nach_Masse_s]";
CM_ SG_ 1502 PowerSteeringSensor_Ks_After_Mass "[DE: Lenkhifesensor_Ks_nach_Masse]";
CM_ SG_ 1502 Voltage_Term_15_Closed_Small_sp_ "[DE: Spannung_Kl_15_zu_klein_sp_]";
CM_ SG_ 1502 Voltage_Term_15_Closed_Small "[DE: Spannung_Kl_15_zu_klein]";
CM_ SG_ 1502 Free_PowerSteering_1_5 "[DE: Frei_Lenkhilfe_1_5]";
CM_ SG_ 1502 Voltage_Term_30_Closed_Small_sp_ "[DE: Spannung_Kl_30_zu_klein_sp_]";
CM_ SG_ 1502 Voltage_Term_30_Closed_Small "[DE: Spannung_Kl_30_zu_klein]";
CM_ SG_ 1502 Voltage_Term_30_Closed_gro__sp_ "[DE: Spannung_Kl_30_zu_gro__sp_]";
CM_ SG_ 1502 Voltage_Term_30_Closed_gro_ "[DE: Spannung_Kl_30_zu_gro_]";
CM_ SG_ 976 LH1_LoadInfo "[DE: LH1_Lastinfo]";
CM_ SG_ 976 LH1_Error_LEFT "[DE: LH1_Fehler_LI]";
CM_ SG_ 976 LH1_SafetyLamp "[DE: LH1_Sicherheitslamp]";
CM_ SG_ 976 LH1_FaultLamp "[DE: LH1_Fehlerlampe]";
CM_ SG_ 976 LH1_TextBits "[DE: LH1_Textbits]";
CM_ SG_ 976 LH1_AcousticSign "[DE: LH1_Akustiksign]";
CM_ SG_ 976 LH1_FaultEntry "[DE: LH1_Fehlereintr]";
CM_ SG_ 976 LH1_EPS_DiagMode "[DE: LH1_EPS_Diagmode]";
CM_ SG_ 976 LH1_Valid_ECU_Temp "[DE: LH1_gue_ECU_Temp]";
CM_ SG_ 976 LH1_Cooling "[DE: LH1_Kuehlung]";
CM_ SG_ 976 LH1_NL_Undervolt "[DE: LH1_NL_Untersp]";
CM_ SG_ 976 LH1_NL_Overvolt "[DE: LH1_NL_Uebersp]";
CM_ SG_ 976 LH1_NL_Overtemp "[DE: LH1_NL_Uebertemp]";
CM_ SG_ 976 LH1_NL_Engine "[DE: LH1_NL_Motor]";
CM_ SG_ 976 LH1_NL_PowerDensity "[DE: LH1_NL_LeistDichte]";
CM_ SG_ 976 LH1_UPower "[DE: LH1_ULeistung]";
CM_ SG_ 1312 Free_Cluster_3_2 "[DE: Frei_Kombi_3_2]";
CM_ SG_ 1312 Odometer "[DE: Kilometerstand]";
CM_ SG_ 1312 ErrorStatus_ParkedTime "[DE: Fehlerstatus_Standzeit]";
CM_ SG_ 1312 ParkedTime "[DE: Standzeit]";
CM_ SG_ 1312 Free_Cluster_3_1 "[DE: Frei_Kombi_3_1]";
CM_ SG_ 1312 KeyInfo "[DE: Schluesselinfo]";
CM_ SG_ 1312 Cluster_Multiplex_Code "[DE: Kombi_Multiplex_Code]";
CM_ SG_ 1312 Cluster_FitmentList_Niveauregulie "[DE: Kombi_Verbauliste_Niveauregulie]";
CM_ SG_ 1312 Cluster_Multiplex_Brand "[DE: Kombi_Multiplex_Marke]";
CM_ SG_ 1312 Cluster_FitmentList_PowerSteering "[DE: Kombi_Verbauliste_Lenkhilfe]";
CM_ SG_ 1312 Cluster_FitmentList_DieselPump "[DE: Kombi_Verbauliste_Dieselpumpe]";
CM_ SG_ 1312 Cluster_FitmentList_SteeringAngle "[DE: Kombi_Verbauliste_Lenkwinkel]";
CM_ SG_ 1312 Cluster_Multiplex_Series "[DE: Kombi_Multiplex_Baureihe]";
CM_ SG_ 1312 Cluster_Multiplex_CountryVariant "[DE: Kombi_Multiplex_Laendervariante]";
CM_ SG_ 1312 Cluster_FitmentList_AllWheelDrive "[DE: Kombi_Verbauliste_Allrad]";
CM_ SG_ 1312 Cluster_FitmentList_VehicleElectrics "[DE: Kombi_Verbauliste_Bordnetz]";
CM_ SG_ 1312 Cluster_FitmentList_ACC "[DE: Kombi_Verbauliste_ACC]";
CM_ SG_ 1312 Cluster_FitmentList_Airbag "[DE: Kombi_Verbauliste_Airbag]";
CM_ SG_ 1312 Cluster_Multiplex_Generation "[DE: Kombi_Multiplex_Generation]";
CM_ SG_ 1312 Cluster_FitmentList_Climate "[DE: Kombi_Verbauliste_Klima]";
CM_ SG_ 1312 Cluster_FitmentList_ABS "[DE: Kombi_Verbauliste_ABS]";
CM_ SG_ 1312 Cluster_FitmentList_Engine "[DE: Kombi_Verbauliste_Motor]";
CM_ SG_ 1312 Cluster_Multiplex_Derivative "[DE: Kombi_Multiplex_Derivat]";
CM_ SG_ 1312 Cluster_Multiplex_LanguageVariant "[DE: Kombi_Multiplex_Sprachvariante]";
CM_ SG_ 1312 Cluster_Multiplex_TyreCircumference "[DE: Kombi_Multiplex_Reifenumfang]";
CM_ SG_ 1056 Free_Cluster_2_2 "[DE: Frei_Kombi_2_2]";
CM_ SG_ 1056 ErrorStatus_Term__58_s "[DE: Fehlerstatus_Kl__58_s]";
CM_ SG_ 1056 Terminal_58s__Cluster_2_ "[DE: Klemme_58s__Kombi_2_]";
CM_ SG_ 1056 ErrorStatus_Term__58_d "[DE: Fehlerstatus_Kl__58_d]";
CM_ SG_ 1056 Terminal_58d__Cluster_2_ "[DE: Klemme_58d__Kombi_2_]";
CM_ SG_ 1056 OutsideTemp__Unfiltered_4_1__Ko "[DE: Aussentemp__ungefiltert_4_1__Ko]";
CM_ SG_ 1056 FaultMemoryEntry__Cluster_ "[DE: Fehlerspeichereintrag__Kombi_]";
CM_ SG_ 1056 Free_Cluster_2_1 "[DE: Frei_Kombi_2_1]";
CM_ SG_ 1056 Trailer_Detected "[DE: Anhaenger_erkannt]";
CM_ SG_ 800 Free_Cluster_1_3 "[DE: Frei_Kombi_1_3]";
CM_ SG_ 800 Displayed_Speed "[DE: Angezeigte_Geschwindigkeit]";
CM_ SG_ 800 Indicator_Right_4_1 "[DE: Blinker_rechts_4_1]";
CM_ SG_ 800 Indicator_Left_4_1 "[DE: Blinker_links_4_1]";
CM_ SG_ 800 Set_TimeGap__Cluster_1_ "[DE: Gesetzte_Zeitluecke__Kombi_1_]";
CM_ SG_ 800 ADDR_Buzzer_SwitchedOff "[DE: ADR_Summer_abgeschaltet]";
CM_ SG_ 800 Free_Cluster_1_2 "[DE: Frei_Kombi_1_2]";
CM_ SG_ 800 Speed__Cluster_1_ "[DE: Geschwindigkeit__Kombi_1_]";
CM_ SG_ 800 SignalSource_Speed_4_ "[DE: Signalquelle_Geschwindigkeit_4_]";
CM_ SG_ 800 LowFuelWarning "[DE: Tankwarnung]";
CM_ SG_ 800 TankContents "[DE: Tankinhalt]";
CM_ SG_ 800 FuelStop "[DE: Tankstop]";
CM_ SG_ 800 Free_Cluster_1_7 "[DE: Frei_Kombi_1_7]";
CM_ SG_ 800 Cluster_In_ActuatorTest "[DE: Kombi_im_Stellgliedtest]";
CM_ SG_ 800 ChargeWarning_Lamp__Cluster_ "[DE: Ladekontroll_Lampe__Kombi_]";
CM_ SG_ 800 BrakeInfo "[DE: Bremsinfo]";
CM_ SG_ 800 GlowPlugLamp__Cluster_1_ "[DE: Vorgluehlampe__Kombi_1_]";
CM_ SG_ 800 LowFuelLamp "[DE: Tankwarnlampe]";
CM_ SG_ 800 HotWarning_PreWarning "[DE: Heissleuchten_Vorwarnung]";
CM_ SG_ 800 CoolantLow "[DE: Kuehlmittelmangel]";
CM_ SG_ 800 Dynamic_OilPressureWarning "[DE: Dynamische_Oeldruckwarnung]";
CM_ SG_ 800 OilPressure "[DE: Oeldruck]";
CM_ SG_ 800 ErrorStatus_Tank "[DE: Fehlerstatus_Tank]";
CM_ SG_ 800 DriverDoor_4_1 "[DE: Fahrertuer_4_1]";
CM_ SG_ 1504 OutsideTemp__Unfilt__Sto_f__4_1 "[DE: Aussentemp__ungef__Sto_f__4_1]";
CM_ SG_ 1504 FaultMemoryEntry__Climate_ "[DE: Fehlerspeichereintrag__Klima_]";
CM_ SG_ 1504 Free_Climate_1_5 "[DE: Frei_Klima_1_5]";
CM_ SG_ 1504 AC_Switch "[DE: AC_Schalter]";
CM_ SG_ 1504 TemperatureUnit "[DE: Temperatureinheit]";
CM_ SG_ 1504 RadiatorFanActuation__Klim "[DE: Kuehlerluefteransteuerung__Klim]";
CM_ SG_ 1504 BlowerLoad_4_1 "[DE: Geblaeselast_4_1]";
CM_ SG_ 1504 CompressorLoad "[DE: Kompressorlast]";
CM_ SG_ 1504 ClimatePressureSignal__Climate_1_ "[DE: Klimadrucksignal__Klima_1_]";
CM_ SG_ 1504 OutsideTemp__Unfilt__4_1__Climate_1 "[DE: Aussentemp__ungef__4_1__Klima_1]";
CM_ SG_ 1504 RefrigerantPressure_Outdated "[DE: Kaeltemitteldruck_veraltet]";
CM_ SG_ 1504 CompressorTorque_Outdated_4_1 "[DE: Kompressormoment_veraltet_4_1]";
CM_ SG_ 1504 No_HeatOutput_Requested_4_1 "[DE: Keine_Heizleistg_gewuenscht_4_1]";
CM_ SG_ 1504 CompressorState__4_1_ "[DE: Kompressorzustand__4_1_]";
CM_ SG_ 1504 Heated_Windscreen "[DE: Heizbare_Frontscheibe]";
CM_ SG_ 1504 Heated_RearWindow "[DE: Heizbare_Heckscheibe]";
CM_ SG_ 1504 DriverDemand_AuxHeater "[DE: Fahrerwunsch_Zuheizer]";
CM_ SG_ 1504 RpmIncrease "[DE: Drehzahlanhebung]";
CM_ SG_ 906 GRA_MainSwitch "[DE: GRA_Hauptschalt]";
CM_ SG_ 906 GRA_Cancel "[DE: GRA_Abbrechen]";
CM_ SG_ 906 GRA_Down_Short "[DE: GRA_Down_kurz]";
CM_ SG_ 906 GRA_Up_Short "[DE: GRA_Up_kurz]";
CM_ SG_ 906 GRA_Down_Long "[DE: GRA_Down_lang]";
CM_ SG_ 906 GRA_Up_Long "[DE: GRA_Up_lang]";
CM_ SG_ 906 GRA_Error_Condition "[DE: GRA_Fehler_Bed]";
CM_ SG_ 906 GRA_CodingInfo "[DE: GRA_Kodierinfo]";
CM_ SG_ 906 GRA_New_Set "[DE: GRA_Neu_Setzen]";
CM_ SG_ 906 GRA_Transmitter "[DE: GRA_Sender]";
CM_ SG_ 906 GRA_TimeGap "[DE: GRA_Zeitluecke]";
CM_ SG_ 906 GRA_Status_Limiter "[DE: GRA_Sta_Limiter]";
CM_ SG_ 906 GRA_Type_MainSwitch "[DE: GRA_Typ_Hauptschalt]";
CM_ SG_ 906 GRA_SportSwitch "[DE: GRA_Sportschalter]";
CM_ SG_ 906 GRA_Error_Tip "[DE: GRA_Fehler_Tip]";
CM_ SG_ 904 Checksum_GRA_Old "[DE: Checksumme_GRA_alt]";
CM_ SG_ 904 Free_GRA_Old "[DE: Frei_GRA_alt]";
CM_ SG_ 904 GRA_Old__ADDR_ControlPanel_Error "[DE: GRA_alt__ADR_Bedienteil_Fehler]";
CM_ SG_ 904 GRA_Old__ADDR_Accelerate "[DE: GRA_alt__ADR_beschleunigen]";
CM_ SG_ 904 GRA_Old__ADDR_Decelerate "[DE: GRA_alt__ADR_verzoegern]";
CM_ SG_ 904 GRA_Old__ADDR___TipSwitch__Wie "[DE: GRA_alt__ADR___Tipschalter__Wie]";
CM_ SG_ 904 GRA_Old__ADDR___TipSwitch__Set "[DE: GRA_alt__ADR___Tipschalter__Set]";
CM_ SG_ 904 GRA_Old__ADDR___TipSwitch__Off "[DE: GRA_alt__ADR___Tipschalter__Aus]";
CM_ SG_ 904 GRA_Old__ADDR___MainSwitch "[DE: GRA_alt__ADR___Hauptschalter]";
CM_ SG_ 904 Counter_GRA_Old "[DE: Zaehler_GRA_alt]";
CM_ SG_ 1352 TestParameter_2 "[DE: Testparameter_2]";
CM_ SG_ 1352 TestParameter_1 "[DE: Testparameter_1]";
CM_ SG_ 1352 SelectorIllumination "[DE: Waehlhebelausleuchtung]";
CM_ SG_ 1352 Free_Gearbox_4_1 "[DE: Frei_Getriebe_4_1]";
CM_ SG_ 1352 TestEnableFlag "[DE: Testfreigabeflag]";
CM_ SG_ 1352 HandbrakeReminder_s_Lamp "[DE: Handbremserinnerung_s_Lampe]";
CM_ SG_ 1352 Shiftlock_Gearbox_4 "[DE: Shiftlock_Getriebe_4]";
CM_ SG_ 1344 Engaged_DriveRange "[DE: eingelegte_Fahrstufe]";
CM_ SG_ 1344 GearDisplay_Cluster___Gearbox_Va "[DE: Ganganzeige_Kombi___Getriebe_Va]";
CM_ SG_ 1344 FaultLamp_f_r_Clutch_At_VL "[DE: Fehlerlampe_f_r_Kupplung_bei_VL]";
CM_ SG_ 1344 Request_CreepAdaptation "[DE: Anforderung_Kriechadaption]";
CM_ SG_ 1344 ECO_Display__4_1_ "[DE: ECO_Anzeige__4_1_]";
CM_ SG_ 1344 Shift_Lock_Lamp "[DE: Shift_Lock_Lampe]";
CM_ SG_ 1344 Suppression_From_Warnings "[DE: Unterdrueckung_von_Warnungen]";
CM_ SG_ 1344 Chime "[DE: Gong]";
CM_ SG_ 1344 Starter_Is_Actuated "[DE: Starter_wird_angesteuert]";
CM_ SG_ 1344 SyncTime "[DE: Synchronisationszeit]";
CM_ SG_ 1344 Inverted_Synchronisation_Wu "[DE: invertierte_Synchronisations_Wu]";
CM_ SG_ 1344 Synchronisation_RequestedRpm "[DE: Synchronisations_Wunschdrehzahl]";
CM_ SG_ 1344 GradientLimit "[DE: Gradientenbegrenzung]";
CM_ SG_ 1344 IdleTargetRpm__Gearbox "[DE: Leerlaufsolldrehzahl__Getriebe]";
CM_ SG_ 1344 ThrottleBlipFlag "[DE: Zwischengasflag]";
CM_ SG_ 1344 OverrunCutSupport "[DE: Schubabschaltunterstuetzung]";
CM_ SG_ 1344 LFR_Adaptation_EnableFlag "[DE: LFR_Adaption_Freigabeflag]";
CM_ SG_ 912 GK1_Status_RDK_Warn "[DE: GK1_Sta_RDK_Warn]";
CM_ SG_ 912 GK1_Status_Trailer "[DE: GK1_Sta_Anhaen]";
CM_ SG_ 912 GK1_Status_Light1 "[DE: GK1_Sta_Licht1]";
CM_ SG_ 912 GK1_Status_Light3 "[DE: GK1_Sta_Licht3]";
CM_ SG_ 912 GK1_Status_DoorContact "[DE: GK1_Sta_Tuerkont]";
CM_ SG_ 912 GK1_Status_Left_Front "[DE: GK1_Sta_Li_vorn]";
CM_ SG_ 912 GK1_CharismaMode "[DE: GK1_CharismaModus]";
CM_ SG_ 912 GK1_SamFuncNr "[DE: GK1_SamFktNr]";
CM_ SG_ 912 GK1_ReverseSch "[DE: GK1_RueckfahrSch]";
CM_ SG_ 912 GK1_ELV_Lock "[DE: GK1_ELV_verrieg]";
CM_ SG_ 912 GK1_Status_Kessy_2 "[DE: GK1_Sta_Kessy_2]";
CM_ SG_ 912 GK1_Status_AuxHeater "[DE: GK1_Sta_Stdhzg]";
CM_ SG_ 912 GK1_SH_Fitment "[DE: GK1_SH_Verbau]";
CM_ SG_ 912 BCM_Remotestart_Operation "[DE: BCM_Remotestart_Betrieb]";
CM_ SG_ 912 GK1_Reverse "[DE: GK1_Rueckfahr]";
CM_ SG_ 912 GK1_BrLeft_Left "[DE: GK1_BrLi_links]";
CM_ SG_ 912 GK1_BrLeft_Right "[DE: GK1_BrLi_rechts]";
CM_ SG_ 912 GK1_BrLeft_Centre "[DE: GK1_BrLi_mitte]";
CM_ SG_ 912 GK1_Indicator_Left "[DE: GK1_Blinker_li]";
CM_ SG_ 912 GK1_Indicator_Right "[DE: GK1_Blinker_re]";
CM_ SG_ 912 GK1_def_P_Lock "[DE: GK1_def_P_verr]";
CM_ SG_ 912 GK1_LS1_HighBeam "[DE: GK1_LS1_Fernlicht]";
CM_ SG_ 912 GK1_Status_Light2 "[DE: GK1_Sta_Licht2]";
CM_ SG_ 912 GK1_Status_LSM "[DE: GK1_Sta_LSM]";
CM_ SG_ 912 GK1_Count_Trailer "[DE: GK1_Count_Anhaen]";
CM_ SG_ 912 GK1_Trailer "[DE: GK1_Anhaenger]";
CM_ SG_ 912 GK1_BrLeft_Trailer "[DE: GK1_BrLi_Anhaen]";
CM_ SG_ 912 GK1_LowBeam "[DE: GK1_Abblendlicht]";
CM_ SG_ 912 GK1_HighBeam "[DE: GK1_Fernlicht]";
CM_ SG_ 912 GK1_Wiper_Front "[DE: GK1_Wischer_vorn]";
CM_ SG_ 912 GK1_Status_ILM_F_1 "[DE: GK1_Sta_ILM_F_1]";
CM_ SG_ 912 GK1_LowBeam_VL_def "[DE: GK1_Abbl_VL_def]";
CM_ SG_ 912 GK1_LowBeam_VR_def "[DE: GK1_Abbl_VR_def]";
CM_ SG_ 912 GK1_Flash_Motorway "[DE: GK1_Blink_Autob]";
CM_ SG_ 912 GK1_HazardFlash_Status "[DE: GK1_Warnblk_Status]";
CM_ SG_ 912 GK1_SH_Running "[DE: GK1_SH_laeuft]";
CM_ SG_ 912 SH1_On_WaterPump "[DE: SH1_ein_Wasserpumpe]";
CM_ SG_ 912 GK1_Fog_On "[DE: GK1_Nebel_ein]";
CM_ SG_ 912 GK1_BrakeLight "[DE: GK1_Bremslicht]";
CM_ SG_ 912 GK1_Trailer_Unplugged "[DE: GK1_Anh_abgesteckt]";
CM_ SG_ 912 GK1_TrailerKonLamp "[DE: GK1_AnhKonLamp]";
CM_ SG_ 912 LDS_Position_AFL "[DE: LDS_Stellung_AFL]";
CM_ SG_ 912 GK1_SH_AdditionalFunc "[DE: GK1_SH_Zusatzfkt]";
CM_ SG_ 1340 Free_Chassis_1_2 "[DE: Frei_Fahrwerk_1_2]";
CM_ SG_ 1340 Free_Chassis_1_1 "[DE: Frei_Fahrwerk_1_1]";
CM_ SG_ 1340 OnPosition_ChassisDamping_4 "[DE: Einstellung_Fahrwerkdaempfung_4]";
CM_ SG_ 1340 Actuation_VehicleLevel "[DE: Ansteuererung_Fahrzeugniveau]";
CM_ SG_ 1472 EP1_Error_Status "[DE: EP1_Fehler_Sta]";
CM_ SG_ 1472 EP1_Status_EPB "[DE: EP1_Sta_EPB]";
CM_ SG_ 1472 EP1_Status_Switch "[DE: EP1_Sta_Schalter]";
CM_ SG_ 1472 EP1_ClampForce "[DE: EP1_Spannkraft]";
CM_ SG_ 1472 EP1_SwitchInfo "[DE: EP1_Schalterinfo]";
CM_ SG_ 1472 EP1_Status_NWS "[DE: EP1_Sta_NWS]";
CM_ SG_ 1472 EP1_Tilt_Angle "[DE: EP1_Neig_winkel]";
CM_ SG_ 1472 EP1_Deceleration "[DE: EP1_Verzoegerung]";
CM_ SG_ 1472 EP1_FaultEntry "[DE: EP1_Fehlereintr]";
CM_ SG_ 1472 EP1_Enable_Ver "[DE: EP1_Freigabe_Ver]";
CM_ SG_ 1472 EP1_AutoHold_Allowed "[DE: EP1_AutoHold_zul]";
CM_ SG_ 1472 EP1_AutoHold_Active "[DE: EP1_AutoHold_aktiv]";
CM_ SG_ 1472 EP1_Status_Term_15 "[DE: EP1_Status_Kl_15]";
CM_ SG_ 1472 EP1_Lamp_AutoP "[DE: EP1_Lampe_AutoP]";
CM_ SG_ 1472 EP1_BrakeLight "[DE: EP1_Bremslicht]";
CM_ SG_ 1472 EP1_WarningTone1 "[DE: EP1_Warnton1]";
CM_ SG_ 1472 EP1_WarningTone2 "[DE: EP1_Warnton2]";
CM_ SG_ 1472 EP1_ReqShLock "[DE: EP1_AnfShLock]";
CM_ SG_ 1472 EPB_AutoHoldLamp "[DE: EPB_Autoholdlampe]";
CM_ SG_ 1472 EP1_QualTiltWi "[DE: EP1_QualNeigWi]";
CM_ SG_ 1472 EP1_ClutchModRange "[DE: EP1_KuppModBer]";
CM_ SG_ 1472 EP1_HydraulicHold "[DE: EP1_HydrHalten]";
CM_ SG_ 1472 EP1_Func_Lamp "[DE: EP1_Fkt_Lampe]";
CM_ SG_ 1472 EP1_WarningTone "[DE: EP1_Warnton]";
CM_ SG_ 1472 EP1_Error_BKL "[DE: EP1_Fehler_BKL]";
CM_ SG_ 1472 EP1_Error_Yellow "[DE: EP1_Fehler_gelb]";
CM_ SG_ 1326 WorkshopCode__Diag_ "[DE: Werkstattcode__Diag_]";
CM_ SG_ 1326 Command_SensorCoding_PowerSteering "[DE: Befehl_Sensorcodierung_Lenkhilf]";
CM_ SG_ 1326 Command_CurveCoding_Steer "[DE: Befehl_Kennliniencodierung_Lenk]";
CM_ SG_ 1326 Command_FaultMemory_Clear "[DE: Befehl_Fehlerspeicher_loeschen]";
CM_ SG_ 1432 Free_Damper_1_4 "[DE: Frei_Daempfer_1_4]";
CM_ SG_ 1432 TextBits_Damper "[DE: Textbits_Daempfer]";
CM_ SG_ 1432 FaultMemoryBit__Damper_1_ "[DE: Fehlerspeicherbit__Daempfer_1_]";
CM_ SG_ 1432 SystemStatus__Damper_1_ "[DE: Systemstatus__Daempfer_1_]";
CM_ SG_ 1432 Free_Damper_1_3 "[DE: Frei_Daempfer_1_3]";
CM_ SG_ 1432 Status_CDC_PushButton "[DE: Status_CDC_Taster]";
CM_ SG_ 1432 Free_Damper_1_2 "[DE: Frei_Daempfer_1_2]";
CM_ SG_ 1432 Status_DamperControl_4_1 "[DE: Status_Daempferregelung_4_1]";
CM_ SG_ 1392 AirCon_SwitchOff "[DE: Klimaanlage_abschalten]";
CM_ SG_ 1392 SeatVentilation_SwitchOff "[DE: Sitzbelueftung_abschalten]";
CM_ SG_ 1392 WasherFluidHeater_SwitchOff "[DE: Wischwasserheizung_abschalten]";
CM_ SG_ 1392 SteeringWheelHeating_SwitchOff "[DE: Lenkradheizung_abschalten]";
CM_ SG_ 1392 Heated_Seats_SwitchOff "[DE: Heizbare_Sitze_abschalten]";
CM_ SG_ 1392 Heated_DoorMirror_Shutoff "[DE: Heizbare_Aussenspiegel_abschalt]";
CM_ SG_ 1392 Heated_Windscreen_Shutoff "[DE: Heizbare_Frontscheibe_abschalte]";
CM_ SG_ 1392 Heated_RearWindow_SwitchOff "[DE: Heizbare_Heckscheibe_abschalten]";
CM_ SG_ 1392 BatteryVoltage_VehicleBattery "[DE: Batteriespannung_Bordnetzbatter]";
CM_ SG_ 1392 BonnetContact "[DE: Motorhaubenkontakt]";
CM_ SG_ 1392 HeadlightLevelling "[DE: Leuchtweitenregulierung]";
CM_ SG_ 1392 FaultMemoryEntry__BodyECU_Load "[DE: Fehlerspeichereintrag__BSG_Last]";
CM_ SG_ 1392 State_The_StarterBattery "[DE: Zustand_der_Starterbatterie]";
CM_ SG_ 1392 State_The_VehicleElectricsBattery "[DE: Zustand_der_Bordnetzbatterie]";
CM_ SG_ 1392 LL_RpmIncrease "[DE: LL_Drehzahlanhebung]";
CM_ SG_ 1392 Terminal_L "[DE: Klemme_L]";
CM_ SG_ 1392 Free_BodyECU_Load_1_1 "[DE: Frei_BSG_Last_1_1]";
CM_ SG_ 1392 ZAS_Terminal_50 "[DE: ZAS_Klemme_50]";
CM_ SG_ 1392 ZAS_Terminal_X "[DE: ZAS_Klemme_X]";
CM_ SG_ 1392 ZAS_Terminal_15 "[DE: ZAS_Klemme_15]";
CM_ SG_ 1392 ZAS_Terminal_S "[DE: ZAS_Klemme_S]";
CM_ SG_ 1136 Free_BodyECU_Cluster_1_3 "[DE: Frei_BSG_Kombi_1_3]";
CM_ SG_ 1136 RearBackrest_HR_Lock__4_1 "[DE: Ruecksitzlehne_HR_verr__4_1]";
CM_ SG_ 1136 RearBackrest_HL_Lock__4_1 "[DE: Ruecksitzlehne_HL_verr__4_1]";
CM_ SG_ 1136 FaultLamp_PowerSteering_Outdated "[DE: Fehlerlampe_Lenkhilfe_veraltet]";
CM_ SG_ 1136 FaultLamp_PowerSteering__BodyECU_Komb "[DE: Fehlerlampe_Lenkhilfe__BSG_Komb]";
CM_ SG_ 1136 ErrorStatus_Term__58s "[DE: Fehlerstatus_Kl__58s]";
CM_ SG_ 1136 Terminal_58s__BodyECU_Cluster_ "[DE: Klemme_58s__BSG_Kombi_]";
CM_ SG_ 1136 ErrorStatus_Term__58d "[DE: Fehlerstatus_Kl__58d]";
CM_ SG_ 1136 Terminal_58d__BodyECU_Cluster_ "[DE: Klemme_58d__BSG_Kombi_]";
CM_ SG_ 1136 Undervoltage "[DE: Unterspannung]";
CM_ SG_ 1136 Free_BodyECU_Cluster_1_2 "[DE: Frei_BSG_Kombi_1_2]";
CM_ SG_ 1136 Tailgate_Opened "[DE: Heckdeckel_geoeffnet]";
CM_ SG_ 1136 Bonnet_Opened "[DE: Motorhaube_geoeffnet]";
CM_ SG_ 1136 Door_Rear_Right_Opened "[DE: Tuer_hinten_rechts_geoeffnet]";
CM_ SG_ 1136 Door_Rear_Left_Opened "[DE: Tuer_hinten_links_geoeffnet]";
CM_ SG_ 1136 PassengerDoor_Opened "[DE: Beifahrertuer_geoeffnet]";
CM_ SG_ 1136 DriverDoor_Opened "[DE: Fahrertuer_geoeffnet]";
CM_ SG_ 1136 Charge_TellTale "[DE: Lade_Kontrollampe]";
CM_ SG_ 1136 Free_BodyECU_Cluster_1_1 "[DE: Frei_BSG_Kombi_1_1]";
CM_ SG_ 1136 ReversingLight "[DE: Rueckfahrlicht]";
CM_ SG_ 1136 DWA_Accumulator "[DE: DWA_Akku]";
CM_ SG_ 1136 HazardFlash_Mode "[DE: Warnblink_Mode]";
CM_ SG_ 1136 Trailer_TellTale "[DE: Anhaenger_Kontrollampe]";
CM_ SG_ 1136 Indicator_Right_TellTale "[DE: Blinker_rechts_Kontrollampe]";
CM_ SG_ 1136 Indicator_Left_TellTale "[DE: Blinker_links_Kontrollampe]";
CM_ SG_ 424 Checksum_Brake_6 "[DE: Checksumme_Bremse_6]";
CM_ SG_ 424 Counter_Brake_6 "[DE: Zaehler_Bremse_6]";
CM_ SG_ 424 Status_BrakePressure__Brake_6__du "[DE: Status_Bremsdruck__Bremse_6__du]";
CM_ SG_ 424 Free_Brake_6_1 "[DE: Frei_Bremse_6_1]";
CM_ SG_ 424 BrakePressure__Brake_6_ "[DE: Bremsdruck__Bremse_6_]";
CM_ SG_ 1192 BR5_ECD_Lamp "[DE: BR5_ECD_Lampe]";
CM_ SG_ 1192 BR5_ZT_Rueckk_Convert "[DE: BR5_ZT_Rueckk_Umsetz]";
CM_ SG_ 1192 BR5_Anhi_Status "[DE: BR5_Anhi_Sta]";
CM_ SG_ 1192 ESP_RollerMode_Deactivate "[DE: ESP_Rollenmodus_Deactiveieren]";
CM_ SG_ 1192 BR5_Sign_Pressure "[DE: BR5_Sign_Druck]";
CM_ SG_ 1192 BR5_Status_Pressure "[DE: BR5_Sta_Druck]";
CM_ SG_ 1192 BR5_PressureValid "[DE: BR5_Druckvalid]";
CM_ SG_ 1192 BR5_Standstill "[DE: BR5_Stillstand]";
CM_ SG_ 1192 BR5_BrakePressure "[DE: BR5_Bremsdruck]";
CM_ SG_ 1192 BR5_Sign "[DE: BR5_Vorzeichen]";
CM_ SG_ 1192 BR5_Status_YawRate "[DE: BR5_Sta_Gierrate]";
CM_ SG_ 1192 BR5_YawRate "[DE: BR5_Giergeschw]";
CM_ SG_ 1192 BR5_ANB_CM_Rueckk_Convert "[DE: BR5_ANB_CM_Rueckk_Umsetz]";
CM_ SG_ 1192 BR5_HDC_Ready "[DE: BR5_HDC_bereit]";
CM_ SG_ 1192 ESP_Status_FallBack_eBKV "[DE: ESP_Stat_FallBack_eBKV]";
CM_ SG_ 1192 ESP_Request_EPB "[DE: ESP_Anforderung_EPB]";
CM_ SG_ 1192 ESP_AutoHold_active "[DE: ESP_Autohold_active]";
CM_ SG_ 1192 ESP_AutoHold_Standby "[DE: ESP_Autohold_Standby]";
CM_ SG_ 1192 BR5_Anhi_Act "[DE: BR5_Anhi_akt]";
CM_ SG_ 1192 BR5_v_Monitor "[DE: BR5_v_Ueberw]";
CM_ SG_ 1192 BR5_BrakeLight "[DE: BR5_Bremslicht]";
CM_ SG_ 1192 BR5_EmergencyBraking "[DE: BR5_Notbremsung]";
CM_ SG_ 1192 BR5_Driver_Occurs_ZBR_Threshold "[DE: BR5_Fahrer_tritt_ZBR_Schw]";
CM_ SG_ 1192 BR5_AWV2_BrakeJerk "[DE: BR5_AWV2_Bremsruck]";
CM_ SG_ 1192 BR5_AWV2_Error "[DE: BR5_AWV2_Fehler]";
CM_ SG_ 672 Free_Brake_4_1 "[DE: Frei_Bremse_4_1]";
CM_ SG_ 672 Unit_ClutchStiffness "[DE: Einheit_Kupplungssteifigkeit]";
CM_ SG_ 672 ABS_SpecifiedValue_Rear_Clutch "[DE: ABS_Vorgabewert_hinten_Kupplung]";
CM_ SG_ 672 ABS_SpecifiedValue_Centre_Clutch "[DE: ABS_Vorgabewert_mitte_Kupplungs]";
CM_ SG_ 1184 WheelSpeed__HR_4_1 "[DE: Radgeschw__HR_4_1]";
CM_ SG_ 1184 Free_Brake_3_4 "[DE: Frei_Bremse_3_4]";
CM_ SG_ 1184 WheelSpeed__HL_4_1 "[DE: Radgeschw__HL_4_1]";
CM_ SG_ 1184 Free_Brake_3_3 "[DE: Frei_Bremse_3_3]";
CM_ SG_ 1184 WheelSpeed__VR_4_1 "[DE: Radgeschw__VR_4_1]";
CM_ SG_ 1184 Free_Brake_3_2 "[DE: Frei_Bremse_3_2]";
CM_ SG_ 1184 WheelSpeed__VL_4_1 "[DE: Radgeschw__VL_4_1]";
CM_ SG_ 1184 Free_Brake_3_1 "[DE: Frei_Bremse_3_1]";
CM_ SG_ 1440 Measured_LateralAccel "[DE: gemessene_Querbeschleunigung]";
CM_ SG_ 1440 Free_Brake_2_2 "[DE: Frei_Bremse_2_2]";
CM_ SG_ 1440 PulseCount "[DE: Impulszahl]";
CM_ SG_ 1440 ErrorStatus_DistancePulses_4_1 "[DE: Fehlerstatus_Wegimpulse_4_1]";
CM_ SG_ 1440 Free_Brake_2_5 "[DE: Frei_Bremse_2_5]";
CM_ SG_ 1440 WarningLamp_DDS "[DE: Warnlampe_DDS]";
CM_ SG_ 1440 FaultMemoryEntry_Brake "[DE: Fehlerspeichereintrag_Bremse]";
CM_ SG_ 1440 DistPulseCounterStatus "[DE: Wegimpulszaehlerstatus]";
CM_ SG_ 1440 DistancePulses_FrontAxle "[DE: Wegimpulse_Vorderachse]";
CM_ SG_ 1440 Timestamp "[DE: Zeitstempel]";
CM_ SG_ 1440 Average_WheelSpeed__Brake_2 "[DE: mittlere_Raddrehzahl__Bremse_2]";
CM_ SG_ 1440 LatAccel__TimerTic "[DE: Querbeschl__TimerTic]";
CM_ SG_ 1440 LateralAccel "[DE: Querbeschleunigung]";
CM_ SG_ 680 FaultMemoryEntry_Booster "[DE: Fehlerspeichereintrag_Booster]";
CM_ SG_ 680 Loseschalter_Implausible_Boost "[DE: Loseschalter_unplausibel_Boost]";
CM_ SG_ 680 ADDR_Relay_ge_ffnet "[DE: ADR_Relais_ge_ffnet]";
CM_ SG_ 680 Status_BrakeBooster_Control "[DE: Status_Bremsbooster_Steuerung]";
CM_ SG_ 680 BrakeBooster_Avail_gbar "[DE: Bremsbooster_verf_gbar]";
CM_ SG_ 680 Intervention_BrakeBooster "[DE: Eingriff_Bremsbooster]";
CM_ SG_ 680 BrakeIntervention_Driver "[DE: Bremseingriff_Fahrer]";
CM_ SG_ 680 Free_BrakeBooster_1_1 "[DE: Frei_Bremsbooster_1_1]";
CM_ SG_ 680 Counter_Booster_1 "[DE: Zaehler_Booster_1]";
CM_ SG_ 680 Checksum_Booster_1 "[DE: Checksumme_Booster_1]";
CM_ SG_ 1400 FaultMemoryEntry__BattMan_ "[DE: Fehlerspeichereintrag__BatMan_]";
CM_ SG_ 1400 PowerRelay "[DE: Leistungsrelais]";
CM_ SG_ 1400 Measurement_StarterLine "[DE: Messung_Starterleitung]";
CM_ SG_ 1400 State_StarterLine "[DE: Zustand_Starterleitung]";
CM_ SG_ 1400 Umschaltrelais_VehicleElectricsBattery "[DE: Umschaltrelais_Bordnetzbatterie]";
CM_ SG_ 1400 Charge_StarterBattery "[DE: Ladung_Starterbatterie]";
CM_ SG_ 1400 StartMode "[DE: Startmodus]";
CM_ SG_ 704 ClutchStiffness_Rear__Is "[DE: Kupplungssteifigkeit_Hinten__Is]";
CM_ SG_ 704 FaultMemoryEntry_AllWheelDrive_1 "[DE: Fehlerspeichereintrag_Allrad_1]";
CM_ SG_ 704 Free_AllWheelDrive_1_1 "[DE: Frei_Allrad_1_1]";
CM_ SG_ 704 Shift_PreWarning "[DE: Schaltung_Vorwarnung]";
CM_ SG_ 704 Shift_Active__AllWheelDrive_1_ "[DE: Schaltung_aktiv__Allrad_1_]";
CM_ SG_ 704 GearInfo__PNG_ "[DE: Ganginfo__PNG_]";
CM_ SG_ 704 PNG_Display_Flashing "[DE: PNG_Anzeige_blinkend]";
CM_ SG_ 704 ClutchStiffness_Centre__Actual "[DE: Kupplungssteifigkeit_Mitte__Ist]";
CM_ SG_ 704 Unit_The_Kupplungssteifigkei "[DE: Einheit_der_Kupplungssteifigkei]";
CM_ SG_ 704 SpeedLimit "[DE: Geschwindigkeitsbegrenzung]";
CM_ SG_ 704 AllWheelDrive_WarningLamp "[DE: Allrad_Warnlampe]";
CM_ SG_ 704 LimpHome "[DE: Notlauf]";
CM_ SG_ 704 Clutch_Complete_Open "[DE: Kupplung_komplett_offen]";
CM_ SG_ 704 ErrorStatus_Kupplungssteifigke "[DE: Fehlerstatus_Kupplungssteifigke]";
CM_ SG_ 704 Ubertemperaturschutz__AllWheelDrive_1_ "[DE: Ubertemperaturschutz__Allrad_1_]";
CM_ SG_ 704 Error_AllWheelDrive_Clutch "[DE: Fehler_Allrad_Kupplung]";
CM_ SG_ 1360 OOP_Passenger "[DE: OOP_Beifahrer]";
CM_ SG_ 1360 OOP_Driver "[DE: OOP_Fahrer]";
CM_ SG_ 1360 OccupancyDetection_Rear_Centre "[DE: Belegungserkennung_hinten_mitte]";
CM_ SG_ 1360 OccupancyDetection_Rear_recht "[DE: Belegungserkennung_hinten_recht]";
CM_ SG_ 1360 OccupancyDetection_Rear_Left "[DE: Belegungserkennung_hinten_links]";
CM_ SG_ 1360 OccupancyDetection_Beifahrersit "[DE: Belegungserkennung_Beifahrersit]";
CM_ SG_ 1360 Checksum_Airbag_2__Reserved "[DE: Checksumme_Airbag_2__reserviert]";
CM_ SG_ 80 FaultMemoryEntry "[DE: Fehlerspeichereintrag]";
CM_ SG_ 80 Free_Airbag_1_2 "[DE: Frei_Airbag_1_2]";
CM_ SG_ 80 Airbag_In_ActuatorTest "[DE: Airbag_im_Stellgliedtest]";
CM_ SG_ 80 Airbag_in_Diagnostics "[DE: Airbag_in_Diagnose]";
CM_ SG_ 80 BeltWarning_Passenger "[DE: Gurtwarnung_Beifahrer]";
CM_ SG_ 80 BeltSwitch_Passenger "[DE: Gurtschalter_Beifahrer]";
CM_ SG_ 80 BeltWarning_Driver "[DE: Gurtwarnung_Fahrer]";
CM_ SG_ 80 BeltSwitch_Driver "[DE: Gurtschalter_Fahrer]";
CM_ SG_ 80 Airbag_SystemError "[DE: Airbag_Systemfehler]";
CM_ SG_ 80 Airbag_Deactivated "[DE: Airbag_deaktiviert]";
CM_ SG_ 80 Airbag_Lamp "[DE: Airbag_Lampe]";
CM_ SG_ 80 Crash_Intensity "[DE: Crash_Intensitaet]";
CM_ SG_ 80 Side_Crash_Passenger "[DE: Seiten_Crash_Beifahrer]";
CM_ SG_ 80 Side_Crash_Driver "[DE: Seiten_Crash_Fahrer]";
CM_ SG_ 80 Rear_Crash "[DE: Heck_Crash]";
CM_ SG_ 864 S_Checksum_ADDR_1 "[DE: S_Checksumme_ADR_1]";
CM_ SG_ 864 S_Free_ADDR_1_1 "[DE: S_Frei_ADR_1_1]";
CM_ SG_ 864 S_TimeGap_Measured "[DE: S_Zeitluecke_gemessen]";
CM_ SG_ 864 S_FaultMemoryEntry_ADDR "[DE: S_Fehlerspeichereintrag_ADR]";
CM_ SG_ 864 S_FaultMemoryEntry_Bremsbo "[DE: S_Fehlerspeichereintrag_Bremsbo]";
CM_ SG_ 864 S_ADDR_Relay_Opened "[DE: S_ADR_Relais_geoeffnet]";
CM_ SG_ 864 S_BrakeBooster_Status "[DE: S_Bremsbooster_Status]";
CM_ SG_ 864 S_Intervention_BrakeBooster "[DE: S_Eingriff_Bremsbooster]";
CM_ SG_ 864 S_Loeseschalter_Implausible "[DE: S_Loeseschalter_unplausibel]";
CM_ SG_ 864 S_BrakeIntervention_Driver "[DE: S_Bremseingriff_Fahrer]";
CM_ SG_ 864 S_Display_Sensor_blind "[DE: S_Anzeige_Sensor_blind]";
CM_ SG_ 864 S_Actuation_Optical_Fahrerh "[DE: S_Ansteuerung_optischer_Fahrerh]";
CM_ SG_ 864 S_Actuation_Chime_2 "[DE: S_Ansteuerung_Gong_2]";
CM_ SG_ 864 S_Actuation_Chime_1 "[DE: S_Ansteuerung_Gong_1]";
CM_ SG_ 864 S_ShiftPrompt "[DE: S_Schaltaufforderung]";
CM_ SG_ 864 S_Display_Priority "[DE: S_Anzeige_Prioritaet]";
CM_ SG_ 864 S_Display_TimeGap "[DE: S_Anzeige_Zeitluecke]";
CM_ SG_ 864 S_SetSpeed "[DE: S_Wunschgeschwindigkeit]";
CM_ SG_ 864 S_Object_Recorded "[DE: S_Objekt_erfasst]";
CM_ SG_ 864 S_Set_TimeGap__ADDR_1_ "[DE: S_Gesetzte_Zeitluecke__ADR_1_]";
CM_ SG_ 864 S_Synchronisation_BrakeBooster "[DE: S_Synchronisation_Bremsbooster]";
CM_ SG_ 864 S_TorqueRequest_Enable "[DE: S_Momentenanforderung_Freigabe]";
CM_ SG_ 864 S_Prevention_OverrunFuelCut "[DE: S_Verhinderung_Schubabschaltung]";
CM_ SG_ 864 S_Status_ADDR_1__S_ "[DE: S_Status_ADR_1__S_]";
CM_ SG_ 864 S_Error_ADDR_1__S_ "[DE: S_Fehler_ADR_1__S_]";
CM_ SG_ 864 S_Counter_ADDR_1 "[DE: S_Zaehler_ADR_1]";
CM_ SG_ 864 S_TorqueRequest_ADDR "[DE: S_Momentenanforderung_ADR]";
CM_ SG_ 608 Free_ADDR_2_2 "[DE: Frei_ADR_2_2]";
CM_ SG_ 608 Request_BrakePressure "[DE: Anforderung_Bremsdruck]";
CM_ SG_ 608 Free_ADDR_2_1 "[DE: Frei_ADR_2_1]";
CM_ SG_ 608 Relay_Test_Error "[DE: Relais_Test_Fehler]";
CM_ SG_ 608 Counter_ADDR_2 "[DE: Zaehler_ADR_2]";
CM_ SG_ 608 Checksum_ADDR_2 "[DE: Checksumme_ADR_2]";
CM_ SG_ 1324 Checksum_ADDR_1 "[DE: Checksumme_ADR_1]";
CM_ SG_ 1324 Free_ADDR_1_5 "[DE: Frei_ADR_1_5]";
CM_ SG_ 1324 TimeGap_Measured "[DE: Zeitluecke_gemessen]";
CM_ SG_ 1324 FaultMemoryEntry_ADDR "[DE: Fehlerspeichereintrag_ADR]";
CM_ SG_ 1324 Reserved_ADDR_1_1 "[DE: Reserviert_ADR_1_1]";
CM_ SG_ 1324 Display_Sensor_blind "[DE: Anzeige_Sensor_blind]";
CM_ SG_ 1324 Actuation_Optical_Fahrerhin "[DE: Ansteuerung_optischer_Fahrerhin]";
CM_ SG_ 1324 Actuation_Chime_2 "[DE: Ansteuerung_Gong_2]";
CM_ SG_ 1324 Actuation_Chime_1 "[DE: Ansteuerung_Gong_1]";
CM_ SG_ 1324 ShiftPrompt "[DE: Schaltaufforderung]";
CM_ SG_ 1324 Display_Priority "[DE: Anzeige_Prioritaet]";
CM_ SG_ 1324 Display_TimeGap "[DE: Anzeige_Zeitluecke]";
CM_ SG_ 1324 SetSpeed "[DE: Wunschgeschwindigkeit]";
CM_ SG_ 1324 Object_Recorded "[DE: Objekt_erfasst]";
CM_ SG_ 1324 Set_TimeGap__ADDR_1_ "[DE: Gesetzte_Zeitluecke__ADR_1_]";
CM_ SG_ 1324 Synchronisation_BrakeBooster "[DE: Synchronisation_Bremsbooster]";
CM_ SG_ 1324 TorqueRequest_Enable "[DE: Momentenanforderung_Freigabe]";
CM_ SG_ 1324 Prevention_OverrunFuelCut "[DE: Verhinderung_Schubabschaltung]";
CM_ SG_ 1324 Status_ADDR_1 "[DE: Status_ADR_1]";
CM_ SG_ 1324 Error_ADDR_1 "[DE: Fehler_ADR_1]";
CM_ SG_ 1324 Counter_ADDR_1 "[DE: Zaehler_ADR_1]";
CM_ SG_ 1324 TorqueRequest_ADDR "[DE: Momentenanforderung_ADR]";
CM_ SG_ 1550 MFA_v_Unit_02 "[DE: MFA_v_Einheit_02]";
CM_ SG_ 872 ACS_Status_ADDR "[DE: ACS_Sta_ADR]";
CM_ SG_ 872 ACS_ADDR_Overrun "[DE: ACS_ADR_Schub]";
CM_ SG_ 872 ACS_OverrunCut "[DE: ACS_Schubabsch]";
CM_ SG_ 872 ACS_TorqueIntervention "[DE: ACS_MomEingriff]";
CM_ SG_ 872 ACS_Type_ACC "[DE: ACS_Typ_ACC]";
CM_ SG_ 872 ACS_EnableTargetB "[DE: ACS_FreigSollB]";
CM_ SG_ 872 ACS_TargetAccel "[DE: ACS_Sollbeschl]";
CM_ SG_ 872 ACS_TrailerOldRequest "[DE: ACS_Anhaltewunsch]";
CM_ SG_ 872 ACS_Error "[DE: ACS_Fehler]";
CM_ SG_ 872 ACS_Allowed_ControlDeviation "[DE: ACS_zul_Regelabw]";
CM_ SG_ 872 ACS_max_ChangeDegree "[DE: ACS_max_AendGrad]";
CM_ SG_ 1386 ACA_StatusACC "[DE: ACA_StaACC]";
CM_ SG_ 1386 ACA_ID_StatusACC "[DE: ACA_ID_StaACC]";
CM_ SG_ 1386 ACA_DispDisplay "[DE: ACA_AnzDisplay]";
CM_ SG_ 1386 ACA_TimeGap "[DE: ACA_Zeitluecke]";
CM_ SG_ 1386 ACA_Acoustic1 "[DE: ACA_Akustik1]";
CM_ SG_ 1386 ACA_Acoustic2 "[DE: ACA_Akustik2]";
CM_ SG_ 1386 ACA_ACC_Decel "[DE: ACA_ACC_Verz]";
CM_ SG_ 1386 ACA_StatusGRA "[DE: ACA_StaGRA]";
CM_ SG_ 1386 ACA_ID_StatusGRA "[DE: ACA_ID_StaGRA]";
CM_ SG_ 1386 ACA_Coding "[DE: ACA_Codierung]";
CM_ SG_ 1386 ACA_SpeedoScale "[DE: ACA_Tachokranz]";
CM_ SG_ 1386 ACA_Change_TimeGap "[DE: ACA_Aend_Zeitluecke]";
CM_ SG_ 208 LH3_BS_Mirror "[DE: LH3_BS_Spiegel]";
CM_ SG_ 208 LH3_Status_DSR "[DE: LH3_Sta_DSR]";
CM_ SG_ 208 LH3_SteeringType "[DE: LH3_Lenkungstyp]";
CM_ SG_ 978 LH2_StraightOff "[DE: LH2_Geradeaus]";
CM_ SG_ 978 LH2_Status_Charisma "[DE: LH2_Sta_Charisma]";
CM_ SG_ 978 LH2_Status_HCA "[DE: LH2_Sta_HCA]";
CM_ SG_ 978 LH2_Ausg_LW1_Valid "[DE: LH2_Ausg_LW1_gue]";
CM_ SG_ 978 LH2_StatusEPS_PLA "[DE: LH2_StatEPS_PLA]";
CM_ SG_ 978 LH2_ActSteeringIntervention "[DE: LH2_aktLenkeingriff]";
CM_ SG_ 980 PL1_Status_PLA_ESP "[DE: PL1_Stat_PLA_ESP]";
CM_ SG_ 980 PL1_BrakeTorque "[DE: PL1_Bremsmoment]";
CM_ SG_ 644 MOB_Enable "[DE: MOB_Freigabe]";
CM_ SG_ 644 MOB_TrailerOldRequest "[DE: MOB_Anhaltewunsch]";
CM_ SG_ 644 TSK_v_Limit_Active "[DE: TSK_v_Begrenzung_aktiv]";
CM_ SG_ 644 TSK_ax_Gearbox_01 "[DE: TSK_ax_Getriebe_01]";
CM_ SG_ 644 MOB_BrakeTorque "[DE: MOB_Bremsmom]";
CM_ SG_ 870 AWV_1_Enable "[DE: AWV_1_Freigabe]";
CM_ SG_ 870 AWV_CityANB_Variant "[DE: AWV_CityANB_Auspraegung]";
CM_ SG_ 870 AWV_Hold "[DE: AWV_Halten]";
CM_ SG_ 870 ANB_PartialBraking_Enable "[DE: ANB_Teilbremsung_Freigabe]";
CM_ SG_ 870 AWV_2_Error "[DE: AWV_2_Fehler]";
CM_ SG_ 870 AWV_2_SU_WarnTime "[DE: AWV_2_SU_Warnzeit]";
CM_ SG_ 870 AWV_2_SU_BrakeJerk "[DE: AWV_2_SU_Bremsruck]";
CM_ SG_ 870 AWV_2_SU_Chime "[DE: AWV_2_SU_Gong]";
CM_ SG_ 870 AWV_2_SU_Lamp "[DE: AWV_2_SU_Lampe]";
CM_ SG_ 870 AWV_2_Enable "[DE: AWV_2_Freigabe]";
CM_ SG_ 870 AWV_2_JerkProfile "[DE: AWV_2_Ruckprofil]";
CM_ SG_ 870 AWV_2_WarningTone "[DE: AWV_2_Warnton]";
CM_ SG_ 870 AWV_InfoTone "[DE: AWV_Infoton]";
CM_ SG_ 870 AWV_2_BeltTensioner "[DE: AWV_2_Gurtstraffer]";
CM_ SG_ 870 AWV_Configuration_MenuReq "[DE: AWV_Konfiguration_Menueanf]";
CM_ SG_ 870 AWV_Configuration_Vorw_MenuReq "[DE: AWV_Konfiguration_Vorw_Menueanf]";
CM_ SG_ 870 AWV_Configuration_Status "[DE: AWV_Konfiguration_Status]";
CM_ SG_ 870 AWV_Configuration_Vorw_Status "[DE: AWV_Konfiguration_Vorw_Status]";
CM_ SG_ 870 AWV_2_DistanceWarning "[DE: AWV_2_Abstandswarnung]";
CM_ SG_ 870 ANB_TargetBraking_Enable "[DE: ANB_Zielbremsung_Freigabe]";
CM_ SG_ 870 ANB_CM_Request "[DE: ANB_CM_Anforderung]";
CM_ SG_ 870 ANB_Target_Teilbrems_Decel_Req "[DE: ANB_Ziel_Teilbrems_Verz_Anf]";
CM_ SG_ 1470 LDW_LearnMode_Right "[DE: LDW_Lernmodus_rechts]";
CM_ SG_ 1470 LDW_LearnMode_Left "[DE: LDW_Lernmodus_links]";
CM_ SG_ 1470 LDW_LearnMode "[DE: LDW_Lernmodus]";
CM_ SG_ 1470 LDW_TextBits "[DE: LDW_Textbits]";
CM_ SG_ 1470 LDW_Chime "[DE: LDW_Gong]";
CM_ SG_ 1470 LDW_CameraType "[DE: LDW_Kameratyp]";
CM_ SG_ 1470 LDW_Lamp_Yellow "[DE: LDW_Lampe_gelb]";
CM_ SG_ 1470 LDW_Lamp_Green "[DE: LDW_Lampe_gruen]";
CM_ SG_ 1470 LDW_SW_Warning_Left "[DE: LDW_SW_Warnung_links]";
CM_ SG_ 1470 LDW_SW_Warning_Right "[DE: LDW_SW_Warnung_rechts]";
CM_ SG_ 1470 LDW_KD_Error "[DE: LDW_KD_Fehler]";
CM_ SG_ 1470 LDW_Side_DLCTLC "[DE: LDW_Seite_DLCTLC]";
CM_ SG_ 1470 LDW_Early_Late "[DE: LDW_Frueh_Spaet]";
CM_ SG_ 428 BR8_Checksum "[DE: BR8_Checksumme]";
CM_ SG_ 428 BR8_Counter "[DE: BR8_Zaehler]";
CM_ SG_ 428 BR8_Status_ACC_Req "[DE: BR8_Sta_ACC_Anf]";
CM_ SG_ 428 BR8_Decel_EPB_Act "[DE: BR8_Verz_EPB_akt]";
CM_ SG_ 428 BR8_Status_Br_temp "[DE: BR8_Sta_Br_temp]";
CM_ SG_ 428 BR8_Status_Br_Pressure "[DE: BR8_Sta_Br_Druck]";
CM_ SG_ 428 BR8_TolAlign_HL "[DE: BR8_TolAbgl_HL]";
CM_ SG_ 428 BR8_TolAlign_HR "[DE: BR8_TolAbgl_HR]";
CM_ SG_ 428 BR8_ActualAccel "[DE: BR8_Istbeschl]";
CM_ SG_ 428 BR8_Status_HW_BLS "[DE: BR8_Sta_HW_BLS]";
CM_ SG_ 428 BR8_QB_LAccel "[DE: BR8_QB_LBeschl]";
CM_ SG_ 428 BR8_ActBrSyst "[DE: BR8_aktBrSyst]";
CM_ SG_ 428 BR8_Fa_Brakes "[DE: BR8_Fa_bremst]";
CM_ SG_ 428 BR8_StatusBrSyst "[DE: BR8_StaBrSyst]";
CM_ SG_ 428 BR8_LongAccel "[DE: BR8_Laengsbeschl]";
CM_ SG_ 428 BR8_Status_ADDR_BR "[DE: BR8_Sta_ADR_BR]";
CM_ SG_ 428 BR8_Status_DecelReg "[DE: BR8_Sta_VerzReg]";
CM_ SG_ 428 BR8_Status_BLS "[DE: BR8_Sta_BLS]";
CM_ SG_ 428 BR8_Decel_EPB "[DE: BR8_Verz_EPB]";
CM_ SG_ 928 B10_Checksum "[DE: B10_Checksumme]";
CM_ SG_ 928 B10_Counter "[DE: B10_Zaehler]";
CM_ SG_ 928 B10_QB_DistPulse_VL "[DE: B10_QB_Wegimp_VL]";
CM_ SG_ 928 B10_QB_DistPulse_VR "[DE: B10_QB_Wegimp_VR]";
CM_ SG_ 928 B10_QB_DistPulse_HL "[DE: B10_QB_Wegimp_HL]";
CM_ SG_ 928 B10_QB_DistPulse_HR "[DE: B10_QB_Wegimp_HR]";
CM_ SG_ 928 B10_DistPulse_VL "[DE: B10_Wegimp_VL]";
CM_ SG_ 928 B10_DistPulse_VR "[DE: B10_Wegimp_VR]";
CM_ SG_ 928 B10_DistPulse_HL "[DE: B10_Wegimp_HL]";
CM_ SG_ 928 B10_DistPulse_HR "[DE: B10_Wegimp_HR]";
CM_ SG_ 928 B10_QB_Direction_VL "[DE: B10_QB_Fahrtr_VL]";
CM_ SG_ 928 B10_QB_Direction_VR "[DE: B10_QB_Fahrtr_VR]";
CM_ SG_ 928 B10_QB_Direction_HL "[DE: B10_QB_Fahrtr_HL]";
CM_ SG_ 928 B10_QB_Direction_HR "[DE: B10_QB_Fahrtr_HR]";
CM_ SG_ 928 B10_Direction_VL "[DE: B10_Fahrtr_VL]";
CM_ SG_ 928 B10_Direction_VR "[DE: B10_Fahrtr_VR]";
CM_ SG_ 928 B10_Direction_HL "[DE: B10_Fahrtr_HL]";
CM_ SG_ 928 B10_Direction_HR "[DE: B10_Fahrtr_HR]";
CM_ SG_ 835 RKS_Tyre_VL "[DE: RKS_Reifen_VL]";
CM_ SG_ 835 RKS_Tyre_VR "[DE: RKS_Reifen_VR]";
CM_ SG_ 835 RKS_Tyre_HL "[DE: RKS_Reifen_HL]";
CM_ SG_ 835 RKS_Tyre_HR "[DE: RKS_Reifen_HR]";
CM_ SG_ 835 RKS_Tyre_RR "[DE: RKS_Reifen_RR]";
CM_ SG_ 835 RKS_Warning_2 "[DE: RKS_Warnung_2]";
CM_ SG_ 835 RKS_Warning_1 "[DE: RKS_Warnung_1]";
CM_ SG_ 835 RKS_SystemError "[DE: RKS_Systemfehler]";
CM_ SG_ 835 RKS_PressureDiff_Front "[DE: RKS_Druckdiff_Vorn]";
CM_ SG_ 835 RKS_PressureDiff_Rear "[DE: RKS_Druckdiff_Hinten]";
CM_ SG_ 835 RKS_RadioMalfunction "[DE: RKS_Funkstoerung]";
CM_ SG_ 835 RKS_System_Off "[DE: RKS_System_Aus]";
CM_ SG_ 835 RKS_KD_Error "[DE: RKS_KD_Fehler]";
CM_ SG_ 835 RKS_Lamp "[DE: RKS_Lampe]";
CM_ SG_ 835 RKS_Tone "[DE: RKS_Ton]";
CM_ SG_ 835 RKS_Chime "[DE: RKS_Gong]";
CM_ SG_ 835 RKS_PartLoad "[DE: RKS_Teillast]";
CM_ SG_ 914 GK2_Status_LSM "[DE: GK2_Sta_LSM]";
CM_ SG_ 914 GK2_Status_Lichtsensor "[DE: GK2_Sta_Lichtsensor]";
CM_ SG_ 914 GK2_Status_Light1 "[DE: GK2_Sta_Licht1]";
CM_ SG_ 914 GK2_Status_VSG "[DE: GK2_Sta_VSG]";
CM_ SG_ 914 GK2_Status_Key "[DE: GK2_Sta_Schluessel]";
CM_ SG_ 914 GK2_Status_Profile "[DE: GK2_Sta_Profil]";
CM_ SG_ 914 GK2_Status_Clima2 "[DE: GK2_Sta_Clima2]";
CM_ SG_ 914 GK2_Status_BodyECU4 "[DE: GK2_Sta_BSG4]";
CM_ SG_ 914 GK2_Status_Kessy_4 "[DE: GK2_Sta_Kessy_4]";
CM_ SG_ 914 BS4_Sliding_Leuchtw_Req "[DE: BS4_Gleitende_Leuchtw_Anf]";
CM_ SG_ 914 BS4_GLW_HighBeam_Req "[DE: BS4_GLW_Fernlicht_Anf]";
CM_ SG_ 914 GK2_Blk_L_Check "[DE: GK2_Blk_L_Kontrolle]";
CM_ SG_ 914 GK2_Blk_R_Check "[DE: GK2_Blk_R_Kontrolle]";
CM_ SG_ 914 GK2_LS_CommError "[DE: GK2_LS_KomFehler]";
CM_ SG_ 914 GK2_Brightness "[DE: GK2_Helligkeit]";
CM_ SG_ 914 GK2_VD_Closed_ver "[DE: GK2_VD_zu_ver]";
CM_ SG_ 914 GK2_VD_Unlocked "[DE: GK2_VD_entriegelt]";
CM_ SG_ 914 GK2_VD_Open_ver "[DE: GK2_VD_offen_ver]";
CM_ SG_ 914 GK2_Roof_Req "[DE: GK2_Verdeck_Anf]";
CM_ SG_ 914 GK2_VDKD_Open "[DE: GK2_VDKD_auf]";
CM_ SG_ 914 GK2_Key "[DE: GK2_Schluessel]";
CM_ SG_ 914 GK2_AFL_Switch "[DE: GK2_AFL_Schalter]";
CM_ SG_ 914 GK2_RearFog "[DE: GK2_Nebelschluss]";
CM_ SG_ 914 GK2_EM_LIN_Invalid "[DE: GK2_EM_LIN_ungueltig]";
CM_ SG_ 914 GK2_Profile "[DE: GK2_Profil]";
CM_ SG_ 914 GK2_Term_StSt_Info "[DE: GK2_Kl_StSt_Info]";
CM_ SG_ 914 GK2_BodyECU_StSt_Info "[DE: GK2_BSG_StSt_Info]";
CM_ SG_ 914 GK2_BEM_P_Alternator "[DE: GK2_BEM_P_Generator]";
CM_ SG_ 914 GK2_BEM_ShutoffStages "[DE: GK2_BEM_Abschaltstufen]";
CM_ SG_ 954 SWA_TextBits "[DE: SWA_Textbits]";
CM_ SG_ 954 SWA_Chime "[DE: SWA_Gong]";
CM_ SG_ 954 SWA_Status_Passive "[DE: SWA_Sta_passiv]";
CM_ SG_ 954 SWA_Status_Active "[DE: SWA_Sta_aktiv]";
CM_ SG_ 954 SWA_InfoLevel_SWA_Left "[DE: SWA_Infostufe_SWA_li]";
CM_ SG_ 954 SWA_Warning_SWA_Left "[DE: SWA_Warnung_SWA_li]";
CM_ SG_ 954 SWA_InfoLevel_SWA_Right "[DE: SWA_Infostufe_SWA_re]";
CM_ SG_ 954 SWA_Warning_SWA_Right "[DE: SWA_Warnung_SWA_re]";
CM_ SG_ 954 SWA_KD_Error "[DE: SWA_KD_Fehler]";
CM_ SG_ 1175 PH_ShutoffCause "[DE: PH_Abschaltursache]";
CM_ SG_ 1175 PH_Opt_Display_V_On "[DE: PH_Opt_Anzeige_V_ein]";
CM_ SG_ 1175 PH_Opt_Display_H_On "[DE: PH_Opt_Anzeige_H_ein]";
CM_ SG_ 1175 PH_Opt_Disp_V_Obstacle "[DE: PH_Opt_Anz_V_Hindernis]";
CM_ SG_ 1175 PH_Opt_Disp_H_Obstacle "[DE: PH_Opt_Anz_H_Hindernis]";
CM_ SG_ 1175 PH_ToneSender_V_Active "[DE: PH_Tongeber_V_aktiv]";
CM_ SG_ 1175 PH_ToneSender_H_Active "[DE: PH_Tongeber_H_aktiv]";
CM_ SG_ 1175 PH_ToneSender_Mute "[DE: PH_Tongeber_mute]";
CM_ SG_ 1175 PH_Req_AudioDucking "[DE: PH_Anf_Audioabsenkung]";
CM_ SG_ 1175 PH_Frequency_Rear "[DE: PH_Frequenz_hinten]";
CM_ SG_ 1175 PH_Volume_Rear "[DE: PH_Lautstaerke_hinten]";
CM_ SG_ 1175 PH_Frequency_Front "[DE: PH_Frequenz_vorn]";
CM_ SG_ 1175 PH_Volume_Front "[DE: PH_Lautstaerke_vorn]";
CM_ SG_ 1175 PH_Trigger_ImageOpenShift "[DE: PH_Trigger_Bildaufschaltung]";
CM_ SG_ 1175 PH_StartStop_Info "[DE: PH_StartStopp_Info]";
CM_ SG_ 1175 PH_Aufbauten_Det "[DE: PH_Aufbauten_erk]";
CM_ SG_ 1175 PH_RangeDet_Front "[DE: PH_BerErk_vorn]";
CM_ SG_ 1175 PH_RangeDet_Rear "[DE: PH_BerErk_hinten]";
CM_ SG_ 1175 PH_Defective "[DE: PH_defekt]";
CM_ SG_ 1175 PH_Disturbed "[DE: PH_gestoert]";
CM_ SG_ 1175 PH_KD_Error "[DE: PH_KD_Fehler]";
CM_ SG_ 1463 B11_HydHold "[DE: B11_HydHalten]";
CM_ SG_ 1463 B11_OBD_Nibble_VL "[DE: B11_OBD_Nib_VL]";
CM_ SG_ 1463 B11_OBD_Nibble_VR "[DE: B11_OBD_Nib_VR]";
CM_ SG_ 1463 B11_OBD_Nibble_HL "[DE: B11_OBD_Nib_HL]";
CM_ SG_ 1463 B11_OBD_Nibble_HR "[DE: B11_OBD_Nib_HR]";
CM_ SG_ 1463 B11_EPB_Actuator_Act "[DE: B11_EPB_Steller_akt]";
CM_ SG_ 1463 B11_EPB_Actuator_Valid "[DE: B11_EPB_Steller_gue]";
CM_ SG_ 1500 VL1_Engine_ECU "[DE: VL1_Motor_SG]";
CM_ SG_ 1500 VL1_Gearbox_ECU "[DE: VL1_Getr_SG]";
CM_ SG_ 1500 VL1_Cluster "[DE: VL1_Kombi]";
CM_ SG_ 1500 VL1_PowerSteering "[DE: VL1_Lenkhilfe]";
CM_ SG_ 1500 VL1_Dyn_LWR "[DE: VL1_dyn_LWR]";
CM_ SG_ 1500 VL1_AllWheelDrive "[DE: VL1_Allrad]";
CM_ SG_ 1500 VL1_ADDR "[DE: VL1_ADR]";
CM_ SG_ 1500 VL1_ADDR_Disconnected "[DE: VL1_ADR_getrennt]";
CM_ SG_ 1500 VL1_Damper "[DE: VL1_Daempfer]";
CM_ SG_ 1500 VL1_EngineSlave "[DE: VL1_MotorSlave]";
CM_ SG_ 1500 VL1_Cluster_KBI "[DE: VL1_Kombi_KBI]";
CM_ SG_ 1500 VL1_Target_eq_Actual "[DE: VL1_Soll_eq_Ist]";
CM_ SG_ 1500 VL1_BodyECU_Comfort "[DE: VL1_BSG_Komf]";
CM_ SG_ 1500 VL1_DoorECU_FT "[DE: VL1_TSG_FT]";
CM_ SG_ 1500 VL1_DoorECU_BT "[DE: VL1_TSG_BT]";
CM_ SG_ 1500 VL1_DoorECU_HL "[DE: VL1_TSG_HL]";
CM_ SG_ 1500 VL1_DoorECU_HR "[DE: VL1_TSG_HR]";
CM_ SG_ 1500 VL1_RoofModule_K "[DE: VL1_Dachmodul_K]";
CM_ SG_ 1500 VL1_CentralElectrics_II "[DE: VL1_Zentralelektrik_II]";
CM_ SG_ 1500 VL1_SteeringColumn "[DE: VL1_Lenksaeule]";
CM_ SG_ 1500 VL1_Clima_Comfort "[DE: VL1_Clima_Komf]";
CM_ SG_ 1500 VL1_ParkAssist "[DE: VL1_Einparkhilfe]";
CM_ SG_ 1500 VL1_PTC_Heating "[DE: VL1_PTC_Heizung]";
CM_ SG_ 1500 VL1_LevelHeat "[DE: VL1_Standheiz]";
CM_ SG_ 1500 VL1_Roof "[DE: VL1_Verdeck]";
CM_ SG_ 1500 VL1_Trailer "[DE: VL1_Anhaenger]";
CM_ SG_ 1500 VL1_Tailgate "[DE: VL1_Heckdeckel]";
CM_ SG_ 1500 VL1_Sonderfzg_ECU "[DE: VL1_Sonderfzg_SG]";
CM_ SG_ 1500 VL1_KeysModule "[DE: VL1_Tastenmodul]";
CM_ SG_ 1500 VL1_Telematics "[DE: VL1_Telematik]";
CM_ SG_ 1500 VL1_InclinationModule_I "[DE: VL1_Neigungsmodul_I]";
CM_ SG_ 1500 VL1_Phone "[DE: VL1_Telefon]";
CM_ SG_ 1490 IDT_Secret_1 "[DE: IDT_Geheimnis_1]";
CM_ SG_ 1490 IDT_Secret_2 "[DE: IDT_Geheimnis_2]";
CM_ SG_ 1490 IDT_Secret_3 "[DE: IDT_Geheimnis_3]";
CM_ SG_ 1490 IDT_Secret_4 "[DE: IDT_Geheimnis_4]";
CM_ SG_ 2000 DI1_km_Level "[DE: DI1_km_Stand]";
CM_ SG_ 2000 DI1_Year "[DE: DI1_Jahr]";
CM_ SG_ 2000 DI1_Month "[DE: DI1_Monat]";
CM_ SG_ 2000 DI1_Hour "[DE: DI1_Stunde]";
CM_ SG_ 2000 DI1_Second "[DE: DI1_Sekunde]";
CM_ SG_ 2000 DI1_KM_Level_Old "[DE: DI1_KM_Stand_alt]";
CM_ SG_ 2000 DI1_Time_Old "[DE: DI1_Zeit_alt]";
CM_ BO_ 1336 "[DE: Wischer_1]";
CM_ BO_ 1096 "[DE: Waehlhebel_1]";
CM_ BO_ 1496 "[DE: Verbauliste_1]";
CM_ BO_ 1488 "[DE: Systeminfo_1]";
CM_ BO_ 1332 "[DE: Sitz_info]";
CM_ BO_ 1424 "[DE: Niveau_1]";
CM_ BO_ 1796 "[DE: Motor_NOX]";
CM_ BO_ 900 "[DE: Motor_Momente]";
CM_ BO_ 1408 "[DE: Motor_Flexia]";
CM_ BO_ 1416 "[DE: Motor_7]";
CM_ BO_ 1160 "[DE: Motor_6]";
CM_ BO_ 640 "[DE: Motor_1]";
CM_ BO_ 1984 "[DE: LWS_Kalibrierung]";
CM_ BO_ 1986 "[DE: Lenkwinkel_Init]";
CM_ BO_ 192 "[DE: Lenkwinkel_1__RB_]";
CM_ BO_ 196 "[DE: Lenkwinkel_1__ITT_]";
CM_ BO_ 1502 "[DE: Lenkhilfe_Fehler]";
CM_ BO_ 976 "[DE: Lenkhilfe_1]";
CM_ BO_ 1312 "[DE: Kombi_3]";
CM_ BO_ 1056 "[DE: Kombi_2]";
CM_ BO_ 800 "[DE: Kombi_1]";
CM_ BO_ 1504 "[DE: Klima_1]";
CM_ BO_ 906 "[DE: GRA_Neu]";
CM_ BO_ 1352 "[DE: Getriebe_4]";
CM_ BO_ 1344 "[DE: Getriebe_2]";
CM_ BO_ 912 "[DE: Gate_Komf_1]";
CM_ BO_ 1340 "[DE: Fahrwerk_1]";
CM_ BO_ 1326 "[DE: Diag_Lenkhilfe]";
CM_ BO_ 1432 "[DE: Daempfer_1]";
CM_ BO_ 1392 "[DE: BSG_Last]";
CM_ BO_ 1136 "[DE: BSG_Kombi]";
CM_ BO_ 424 "[DE: Bremse_6]";
CM_ BO_ 1192 "[DE: Bremse_5]";
CM_ BO_ 672 "[DE: Bremse_4]";
CM_ BO_ 1184 "[DE: Bremse_3]";
CM_ BO_ 1440 "[DE: Bremse_2]";
CM_ BO_ 416 "[DE: Bremse_1]";
CM_ BO_ 680 "[DE: Bremsbooster_1]";
CM_ BO_ 1400 "[DE: BatMan_1]";
CM_ BO_ 704 "[DE: Allrad_1]";
CM_ BO_ 864 "[DE: ADR_System]";
CM_ BO_ 608 "[DE: ADR_2]";
CM_ BO_ 1324 "[DE: ADR_1]";
CM_ BO_ 1550 "[DE: Einheiten_1]";
CM_ BO_ 1386 "[DE: ACC_GRA_Anzeige]";
CM_ BO_ 208 "[DE: Lenkhilfe_3]";
CM_ BO_ 978 "[DE: Lenkhilfe_2]";
CM_ BO_ 644 "[DE: Motor_Bremse]";
CM_ BO_ 428 "[DE: Bremse_8]";
CM_ BO_ 928 "[DE: Bremse_10]";
CM_ BO_ 914 "[DE: Gate_Komf_2]";
CM_ BO_ 1175 "[DE: Parkhilfe_01]";
CM_ BO_ 1463 "[DE: Bremse_11]";
CM_ BO_ 1500 "[DE: Soll_Verbauliste_neu]";
CM_ BO_ 2000 "[DE: Diagnose_1]";
CM_ "English names by can2gauge tools/dbc/dbc_tool.py from opendbc vw_pq.dbc (MIT); the original German names are in the comments as [DE: ...]";
